VERSION ""

NS_ :

BS_:

BU_: VCU_LE CHUD_LE VKM_LE RCRM_LE VPM_LE EDI_LE V2V_LE TCP_LE CSM_LE UHP_Low_LE TouchPad_LE RSE_LE RSC_LE RSA_LE PDIM_LE OTIM_LE ICS_LE LVMPC_LE LVMNav_LE DVB_T_LE ONSTAR_LE HUD_LE IPC_LE RadioHead_LE CHM_LE Dummy_LE CGM_LE AMP_LE

BO_ 2154807296 Lighting_Customization_Info_3_LE: 4 CGM_LE
 SG_ TnDrvStBltShftIntrlkCsStAvl : 19|1@0+ (1,0) [0|1] ""  VCU_LE,CSM_LE
 SG_ TnDrvStBltShftIntrlkCrStVal : 22|3@0+ (1,0) [0|7] ""  VCU_LE,CSM_LE
 SG_ StBltShftIntrlkCsStAvl : 18|1@0+ (1,0) [0|1] ""  CSM_LE
 SG_ StBltShftIntrlkCsCrStVal : 15|3@0+ (1,0) [0|7] ""  CSM_LE
 SG_ EASSI_UnsdRsrvd2 : 24|1@0+ (1,0) [0|1] ""  Dummy_LE
 SG_ EASSI_StlDetd : 26|1@0+ (1,0) [0|1] ""  Dummy_LE
 SG_ EASSI_TrqDetd : 27|1@0+ (1,0) [0|1] ""  Dummy_LE
 SG_ EASSI_FuelReqOn : 28|1@0+ (1,0) [0|1] ""  Dummy_LE
 SG_ EASSI_StrtTyp : 31|3@0+ (1,0) [0|7] ""  Dummy_LE
 SG_ EASSI_StrtStpSt : 17|2@0+ (1,0) [0|3] ""  Dummy_LE
 SG_ EASSI_TorqDetdIndet : 25|1@0+ (1,0) [0|1] ""  Dummy_LE
 SG_ EngAutoStpNotProb : 11|1@0+ (1,0) [0|1] ""  Dummy_LE
 SG_ AFLMnu3CstStAvl : 10|1@0+ (1,0) [0|1] ""  VCU_LE,CSM_LE,RadioHead_LE
 SG_ AFLMnu2CstStAvl : 9|1@0+ (1,0) [0|1] ""  VCU_LE,CSM_LE,RadioHead_LE
 SG_ AFLGPSMnu2CstStAvl : 8|1@0+ (1,0) [0|1] ""  VCU_LE,CSM_LE,RadioHead_LE
 SG_ AFLGPSCstStAvl : 6|1@0+ (1,0) [0|1] ""  VCU_LE,CSM_LE,RadioHead_LE
 SG_ AFLGPSCstCrStVal : 2|3@0+ (1,0) [0|7] ""  VCU_LE,CSM_LE,RadioHead_LE
 SG_ AFLCstStAvl : 7|1@0+ (1,0) [0|1] ""  VCU_LE,CSM_LE,RadioHead_LE
 SG_ AFLCstCrStVal : 5|3@0+ (1,0) [0|7] ""  VCU_LE,CSM_LE,RadioHead_LE

BO_ 2155970560 HVAC_PowerManager_Status_LE: 1 CGM_LE
 SG_ ClmCntLdShdLvlRq : 3|4@0+ (1,0) [0|15] ""  Dummy_LE
 SG_ ClmCntBatSaverIO : 5|1@0+ (1,0) [0|1] ""  VCU_LE,IPC_LE

BO_ 2159067136 ODI_DAB_2_IPC_LE: 8 RadioHead_LE
 SG_ ODI_DAB2IPC : 7|64@0+ (1,0) [0|1.84467440737096E+019] ""  VCU_LE,IPC_LE

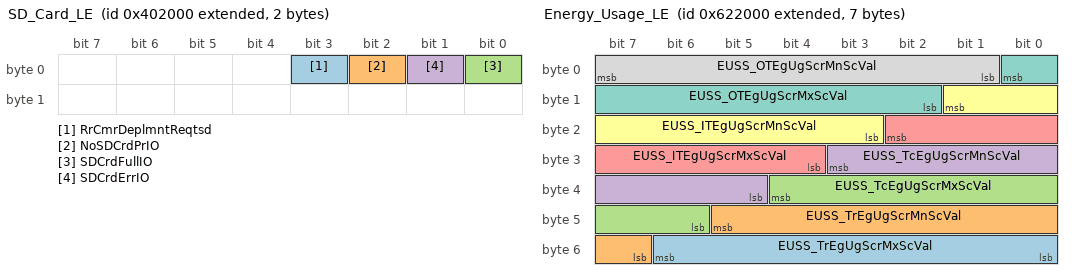
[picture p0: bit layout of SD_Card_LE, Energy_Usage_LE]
BO_ 2151686144 SD_Card_LE: 2 VPM_LE
 SG_ RrCmrDeplmntReqtsd : 3|1@0+ (1,0) [0|1] ""  RCRM_LE
 SG_ NoSDCrdPrIO : 2|1@0+ (1,0) [0|1] ""  CSM_LE,RadioHead_LE,VCU_LE,IPC_LE
 SG_ SDCrdFullIO : 0|1@0+ (1,0) [0|1] ""  CSM_LE,RadioHead_LE,VCU_LE,IPC_LE
 SG_ SDCrdErrIO : 1|1@0+ (1,0) [0|1] ""  CSM_LE,RadioHead_LE,VCU_LE,IPC_LE

BO_ 595 USDT_Req_to_TIM_CGM_LE: 8 ONSTAR_LE
 SG_ DgnInf : 7|64@0+ (1,0) [0|1.84467440737096E+019] ""  TCP_LE,ONSTAR_LE,CGM_LE

BO_ 2153914368 Energy_Usage_LE: 7 CGM_LE
 SG_ EUSS_TrEgUgScrMxScVal : 54|7@0- (0.1,0) [-5|5] ""  VCU_LE,CSM_LE,RadioHead_LE
 SG_ EUSS_TrEgUgScrMnScVal : 45|7@0- (0.1,0) [-5|5] ""  VCU_LE,CSM_LE,RadioHead_LE
 SG_ EUSS_TcEgUgScrMxScVal : 36|7@0- (0.1,0) [-5|5] ""  VCU_LE,CSM_LE,RadioHead_LE
 SG_ EUSS_TcEgUgScrMnScVal : 27|7@0- (0.1,0) [-5|5] ""  VCU_LE,CSM_LE,RadioHead_LE
 SG_ EUSS_ITEgUgScrMxScVal : 18|7@0- (0.1,0) [-5|5] ""  VCU_LE,CSM_LE,RadioHead_LE
 SG_ EUSS_ITEgUgScrMnScVal : 9|7@0- (0.1,0) [-5|5] ""  VCU_LE,CSM_LE,RadioHead_LE
 SG_ EUSS_OTEgUgScrMxScVal : 0|7@0- (0.1,0) [-5|5] ""  VCU_LE,CSM_LE,RadioHead_LE
 SG_ EUSS_OTEgUgScrMnScVal : 7|7@0- (0.1,0) [-5|5] ""  VCU_LE,CSM_LE,RadioHead_LE

BO_ 2150629376 CV_System_Failure_LE: 1 CGM_LE
 SG_ CVSysFlrIO : 0|1@0+ (1,0) [0|1] ""  CSM_LE,VCU_LE,IPC_LE

BO_ 2153390080 Manual_Liftgate_Control_LE: 1 CGM_LE
 SG_ RrClosOpenSwAct_2D1V : 3|1@0+ (1,0) [0|1] ""  VCU_LE,IPC_LE
 SG_ RrClosOpenSwAct_2D1 : 1|1@0+ (1,0) [0|1] ""  VKM_LE,VCU_LE,IPC_LE

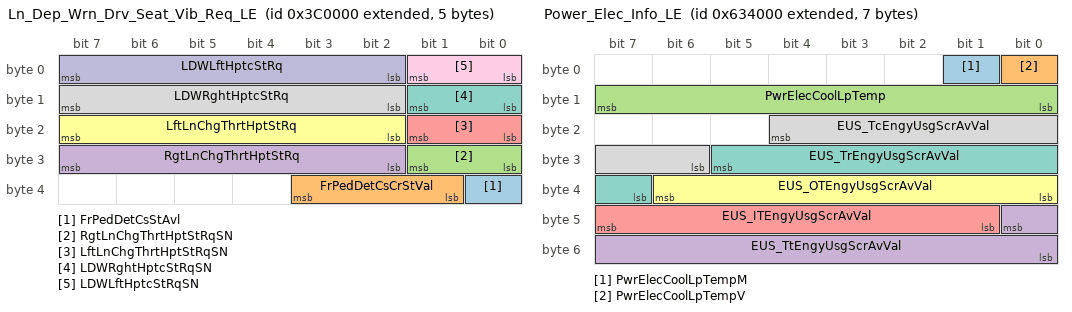
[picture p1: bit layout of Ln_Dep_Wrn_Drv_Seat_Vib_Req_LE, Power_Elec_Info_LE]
BO_ 2151415808 Ln_Dep_Wrn_Drv_Seat_Vib_Req_LE: 5 CGM_LE
 SG_ FrPedDetCsStAvl : 32|1@0+ (1,0) [0|1] ""  VCU_LE,CSM_LE,RadioHead_LE
 SG_ FrPedDetCsCrStVal : 35|3@0+ (1,0) [0|7] ""  VCU_LE,CSM_LE,RadioHead_LE
 SG_ RgtLnChgThrtHptStRqSN : 25|2@0+ (1,0) [0|3] ""  Dummy_LE
 SG_ RgtLnChgThrtHptStRq : 31|6@0+ (1,0) [0|63] "Pulse"  Dummy_LE
 SG_ LftLnChgThrtHptStRqSN : 17|2@0+ (1,0) [0|3] ""  Dummy_LE
 SG_ LftLnChgThrtHptStRq : 23|6@0+ (1,0) [0|63] "Pulse"  Dummy_LE
 SG_ LDWRghtHptcStRqSN : 9|2@0+ (1,0) [0|3] ""  Dummy_LE
 SG_ LDWRghtHptcStRq : 15|6@0+ (1,0) [0|63] ""  Dummy_LE
 SG_ LDWLftHptcStRqSN : 1|2@0+ (1,0) [0|3] ""  Dummy_LE
 SG_ LDWLftHptcStRq : 7|6@0+ (1,0) [0|63] ""  Dummy_LE

BO_ 2150080512 Aux_Coolant_Heater_Status_LE: 8 CGM_LE
 SG_ LBCVLS_VehGPSLctV : 27|1@0+ (1,0) [0|1] ""  TCP_LE,ONSTAR_LE,VCU_LE,CSM_LE,RadioHead_LE
 SG_ LBCVLS_VehGPSLct : 26|3@0+ (1,0) [0|7] ""  TCP_LE,ONSTAR_LE,VCU_LE,CSM_LE,RadioHead_LE
 SG_ EngAstHtDfrdHtMdAct : 0|1@0+ (1,0) [0|1] ""  Dummy_LE
 SG_ LBCPSS_PosUpdtStat : 20|2@0+ (1,0) [0|3] ""  VCU_LE,CSM_LE,RadioHead_LE
 SG_ LBCPSS_PosUpdtLct : 18|3@0+ (1,0) [0|7] ""  VCU_LE,CSM_LE,RadioHead_LE
 SG_ LBCCsStAvl : 7|1@0+ (1,0) [0|1] ""  VCU_LE,CSM_LE,RadioHead_LE
 SG_ LBCCsCrStVal : 2|2@0+ (1,0) [0|3] ""  VCU_LE,CSM_LE,RadioHead_LE
 SG_ LBCCF_Lct4PosStrdIO : 28|1@0+ (1,0) [0|1] ""  VCU_LE,CSM_LE,RadioHead_LE
 SG_ LBCCF_Lct3PosStrdIO : 29|1@0+ (1,0) [0|1] ""  VCU_LE,CSM_LE,RadioHead_LE
 SG_ LBCCF_Lct2PosStrdIO : 30|1@0+ (1,0) [0|1] ""  VCU_LE,CSM_LE,RadioHead_LE
 SG_ LBCCF_Lct1PosStrdIO : 31|1@0+ (1,0) [0|1] ""  VCU_LE,CSM_LE,RadioHead_LE
 SG_ LBCCDRR_PosNumbr : 10|3@0+ (1,0) [0|7] ""  VCU_LE,CSM_LE,RadioHead_LE
 SG_ LBCCDRR_ClrStrdPosResp : 12|2@0+ (1,0) [0|3] ""  VCU_LE,CSM_LE,RadioHead_LE
 SG_ LBCChrgLvlPrfExpIO : 6|1@0+ (1,0) [0|1] ""  VCU_LE,CSM_LE,RadioHead_LE
 SG_ AuxClntHtrVlvStat : 5|3@0+ (1,0) [0|7] ""  Dummy_LE
 SG_ ChrgCyclOvrlEngyEcnEq : 51|12@0+ (0.1,0) [0|409.5] "km/l"  VCU_LE,CSM_LE,RadioHead_LE
 SG_ ChrgCyclElecEngyEcnEq : 35|12@0+ (0.1,0) [0|409.5] "km/l"  VCU_LE,CSM_LE,RadioHead_LE

BO_ 2153988096 Power_Elec_Info_LE: 7 CGM_LE
 SG_ PwrElecCoolLpTempM : 1|1@0+ (1,0) [0|1] ""  Dummy_LE
 SG_ PwrElecCoolLpTempV : 0|1@0+ (1,0) [0|1] ""  Dummy_LE
 SG_ PwrElecCoolLpTemp : 15|8@0+ (1,-40) [-40|215] "deg C"  Dummy_LE
 SG_ EUS_TtEngyUsgScrAvVal : 40|9@0- (0.1,0) [-20|20] ""  VCU_LE,CSM_LE,RadioHead_LE
 SG_ EUS_ITEngyUsgScrAvVal : 47|7@0- (0.1,0) [-5|5] ""  VCU_LE,CSM_LE,RadioHead_LE
 SG_ EUS_OTEngyUsgScrAvVal : 38|7@0- (0.1,0) [-5|5] ""  VCU_LE,CSM_LE,RadioHead_LE
 SG_ EUS_TrEngyUsgScrAvVal : 29|7@0- (0.1,0) [-5|5] ""  VCU_LE,CSM_LE,RadioHead_LE
 SG_ EUS_TcEngyUsgScrAvVal : 20|7@0- (0.1,0) [-5|5] ""  VCU_LE,CSM_LE,RadioHead_LE

BO_ 2151915520 HMI_Display_LE: 8 CGM_LE
 SG_ ESPTrnVehOffFrPrkIO : 44|1@0+ (1,0) [0|1] ""  VCU_LE,IPC_LE
 SG_ ESPTrnsCtlrMalfIO : 45|1@0+ (1,0) [0|1] ""  VCU_LE,IPC_LE
 SG_ ESPShfToDrvTryAgnIO : 43|1@0+ (1,0) [0|1] ""  VCU_LE,IPC_LE
 SG_ ElcShfPriTwoGrsSlInRq : 47|2@0+ (1,0) [0|3] ""  VCU_LE,IPC_LE
 SG_ ESPRedSpdReqShftIO : 42|1@0+ (1,0) [0|1] ""  VCU_LE,IPC_LE
 SG_ DrvEffInd : 39|8@0- (0.78125,0) [-100|99.21875] "%"  CSM_LE,VCU_LE,IPC_LE
 SG_ EngIntkArBstPrExtRngV : 14|1@0+ (1,0) [0|1] ""  VCU_LE,IPC_LE
 SG_ EngIntkArBstPrExtRng : 8|9@0+ (1,-110) [-110|401] "kPa"  VCU_LE,IPC_LE
 SG_ ElecShfRngDispRCExtd : 27|4@0+ (1,0) [0|15] ""  VCU_LE,IPC_LE
 SG_ ElecShfRngDisp : 31|4@0+ (1,0) [0|15] ""  VCU_LE,IPC_LE
 SG_ ESPTransMalfIO : 9|1@0+ (1,0) [0|1] ""  VCU_LE,IPC_LE
 SG_ ESPRngInvldReqIO : 10|1@0+ (1,0) [0|1] ""  VCU_LE,IPC_LE
 SG_ ESPPrkInvldReqIO : 11|1@0+ (1,0) [0|1] ""  VCU_LE,IPC_LE
 SG_ ESPHldShfLvrToEngRgIO : 12|1@0+ (1,0) [0|1] ""  VCU_LE,IPC_LE
 SG_ ESPDrvrPrkIlkSftAtdIO : 13|1@0+ (1,0) [0|1] ""  VCU_LE,IPC_LE
 SG_ ESPDrvrIlkShfAtdIO : 7|1@0+ (1,0) [0|1] ""  VCU_LE,IPC_LE
 SG_ AHAct : 6|1@0+ (1,0) [0|1] ""  VCU_LE,IPC_LE
 SG_ AHEnbld : 5|1@0+ (1,0) [0|1] ""  CSM_LE,VCU_LE,IPC_LE
 SG_ ShfToPrkBfExtngIO : 4|1@0+ (1,0) [0|1] ""  VCU_LE,IPC_LE
 SG_ AHServcIO : 3|1@0+ (1,0) [0|1] ""  VCU_LE,IPC_LE
 SG_ AHAppBrkPedlIO : 2|1@0+ (1,0) [0|1] ""  VCU_LE,IPC_LE
 SG_ AHDisbldStbltIO : 1|1@0+ (1,0) [0|1] ""  VCU_LE,IPC_LE
 SG_ AHDisbldDrOpnIO : 0|1@0+ (1,0) [0|1] ""  VCU_LE,IPC_LE
 SG_ ElcTransRngSlctVDA : 15|1@0+ (1,0) [0|1] ""  VCU_LE,IPC_LE

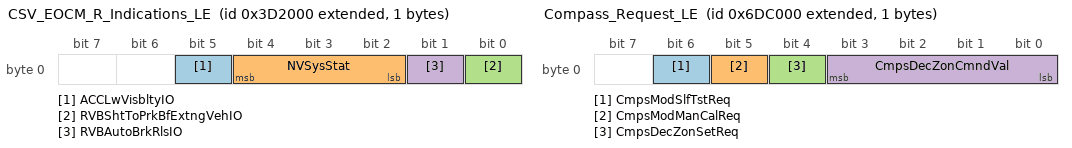
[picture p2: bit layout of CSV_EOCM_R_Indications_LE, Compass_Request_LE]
BO_ 2151489536 CSV_EOCM_R_Indications_LE: 1 CGM_LE
 SG_ ACCLwVisbltyIO : 5|1@0+ (1,0) [0|1] ""  VCU_LE,IPC_LE
 SG_ NVSysStat : 4|3@0+ (1,0) [0|7] ""  VCU_LE,IPC_LE
 SG_ RVBShtToPrkBfExtngVehIO : 0|1@0+ (1,0) [0|1] ""  VCU_LE,IPC_LE
 SG_ RVBAutoBrkRlsIO : 1|1@0+ (1,0) [0|1] ""  VCU_LE,IPC_LE

BO_ 590 USDT_Req_to_RSC_LE: 8 ONSTAR_LE
 SG_ DgnInf : 7|64@0+ (1,0) [0|1.84467440737096E+019] ""  TCP_LE,ONSTAR_LE,CGM_LE,VKM_LE,RSC_LE

BO_ 586 USDT_Req_to_LVMPC_LE: 8 ONSTAR_LE
 SG_ DgnInf : 7|64@0+ (1,0) [0|1.84467440737096E+019] ""  TCP_LE,ONSTAR_LE,CGM_LE,CHUD_LE,LVMPC_LE

BO_ 596 USDT_Req_to_AMP_LE: 8 ONSTAR_LE
 SG_ DgnInf : 7|64@0+ (1,0) [0|1.84467440737096E+019] ""  TCP_LE,ONSTAR_LE,AMP_LE

BO_ 582 USDT_Req_to_ICS_LE: 8 ONSTAR_LE
 SG_ DgnInf : 7|64@0+ (1,0) [0|1.84467440737096E+019] ""  TCP_LE,ONSTAR_LE,ICS_LE

BO_ 257 USDT_Req_to_All_LE_ECUs: 8 ONSTAR_LE
 SG_ DgnInf : 7|64@0+ (1,0) [0|1.84467440737096E+019] ""  RCRM_LE,V2V_LE,CGM_LE,VKM_LE,RSC_LE,RSE_LE,RSA_LE,PDIM_LE,TCP_LE,UHP_Low_LE,LVMNav_LE,ONSTAR_LE,CHUD_LE,LVMPC_LE,IPC_LE,VPM_LE,HUD_LE,AMP_LE,VCU_LE,CSM_LE,RadioHead_LE,CHM_LE,OTIM_LE,ICS_LE,TouchPad_LE,DVB_T_LE

BO_ 594 USDT_Req_to_DVBT_LE: 8 ONSTAR_LE
 SG_ DgnInf : 7|64@0+ (1,0) [0|1.84467440737096E+019] ""  TCP_LE,ONSTAR_LE,TouchPad_LE,DVB_T_LE

BO_ 592 USDT_Req_to_HUD_LE: 8 ONSTAR_LE
 SG_ DgnInf : 7|64@0+ (1,0) [0|1.84467440737096E+019] ""  TCP_LE,ONSTAR_LE,VPM_LE,HUD_LE

BO_ 588 USDT_Req_to_IPC_LE: 8 ONSTAR_LE
 SG_ DgnInf : 7|64@0+ (1,0) [0|1.84467440737096E+019] ""  TCP_LE,ONSTAR_LE,IPC_LE

BO_ 585 USDT_Req_to_OTIM_LE: 8 ONSTAR_LE
 SG_ DgnInf : 7|64@0+ (1,0) [0|1.84467440737096E+019] ""  TCP_LE,ONSTAR_LE,CGM_LE,OTIM_LE

BO_ 584 USDT_Req_to_PDIM_LE: 8 ONSTAR_LE
 SG_ DgnInf : 7|64@0+ (1,0) [0|1.84467440737096E+019] ""  TCP_LE,ONSTAR_LE,CGM_LE,PDIM_LE

BO_ 580 USDT_Req_to_RadioHead_LE: 8 ONSTAR_LE
 SG_ DgnInf : 7|64@0+ (1,0) [0|1.84467440737096E+019] ""  TCP_LE,ONSTAR_LE,VCU_LE,CSM_LE,RadioHead_LE,CHM_LE

BO_ 598 USDT_Req_to_RSA_RSE_LE: 8 ONSTAR_LE
 SG_ DgnInf : 7|64@0+ (1,0) [0|1.84467440737096E+019] ""  TCP_LE,ONSTAR_LE,CGM_LE,RSE_LE,RSA_LE

BO_ 589 USDT_Req_to_UHP_ONS_LE: 8 CSM_LE
 SG_ DgnInf : 7|64@0+ (1,0) [0|1.84467440737096E+019] ""  TCP_LE,UHP_Low_LE,LVMNav_LE,ONSTAR_LE

BO_ 1612 USDT_Resp_From_IPC_LE: 8 IPC_LE
 SG_ DgnInf : 7|64@0+ (1,0) [0|1.84467440737096E+019] ""  CSM_LE,CGM_LE,TCP_LE,ONSTAR_LE

BO_ 1580 VNMF_LE_62C_IPC: 8 IPC_LE
 SG_ VectraSpcNWMgtD : 7|64@0+ (1,0) [0|1.84467440737096E+019] ""  RCRM_LE,V2V_LE,TCP_LE,UHP_Low_LE,LVMNav_LE,ONSTAR_LE,VKM_LE,RSC_LE,RSE_LE,RSA_LE,PDIM_LE,OTIM_LE,CHUD_LE,LVMPC_LE,ICS_LE,VPM_LE,HUD_LE,TouchPad_LE,DVB_T_LE,VCU_LE,CSM_LE,RadioHead_LE,CHM_LE,AMP_LE,CGM_LE

BO_ 1356 UUDT_Resp_From_IPC_LE: 8 IPC_LE
 SG_ DgnInf_LS54C : 7|64@0+ (1,0) [0|1.84467440737096E+019] ""  CSM_LE,CGM_LE,TCP_LE,ONSTAR_LE

BO_ 2154676224 Compass_Request_LE: 1 IPC_LE
 SG_ CmpsModSlfTstReq : 6|1@0+ (1,0) [0|1] ""  CGM_LE
 SG_ CmpsModManCalReq : 5|1@0+ (1,0) [0|1] ""  CGM_LE
 SG_ CmpsDecZonSetReq : 4|1@0+ (1,0) [0|1] ""  CGM_LE
 SG_ CmpsDecZonCmndVal : 3|4@0+ (1,0) [0|15] ""  CGM_LE

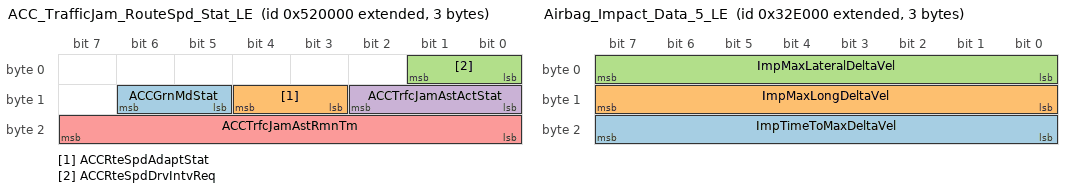
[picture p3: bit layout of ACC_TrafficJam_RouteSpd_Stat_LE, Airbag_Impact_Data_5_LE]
BO_ 2152857600 ACC_TrafficJam_RouteSpd_Stat_LE: 3 CGM_LE
 SG_ ACCGrnMdStat : 14|2@0+ (1,0) [0|3] ""  CSM_LE,ONSTAR_LE,VCU_LE,IPC_LE
 SG_ ACCRteSpdAdaptStat : 12|2@0+ (1,0) [0|3] ""  CSM_LE,VCU_LE,IPC_LE
 SG_ ACCRteSpdDrvIntvReq : 1|2@0+ (1,0) [0|3] ""  VCU_LE,IPC_LE
 SG_ ACCTrfcJamAstActStat : 10|3@0+ (1,0) [0|7] ""  VCU_LE,IPC_LE
 SG_ ACCTrfcJamAstRmnTm : 23|8@0+ (1,0) [0|255] "sec"  VCU_LE,IPC_LE

BO_ 2154995712 Air_Conditioning_Comp_Type_LE: 1 CGM_LE
 SG_ HVHtrFldIO : 4|1@0+ (1,0) [0|1] ""  VCU_LE,IPC_LE
 SG_ HVHtrOvrTmpIndOn : 3|1@0+ (1,0) [0|1] ""  CSM_LE,ONSTAR_LE,VCU_LE,IPC_LE

BO_ 2150817792 Airbag_Impact_Data_5_LE: 3 CGM_LE
 SG_ ImpTimeToMaxDeltaVel : 23|8@0+ (10,0) [0|2550] "ms"  TCP_LE,ONSTAR_LE
 SG_ ImpMaxLongDeltaVel : 15|8@0- (1,0) [-128|127] ""  TCP_LE,ONSTAR_LE
 SG_ ImpMaxLateralDeltaVel : 7|8@0- (1,0) [-128|127] ""  TCP_LE,ONSTAR_LE

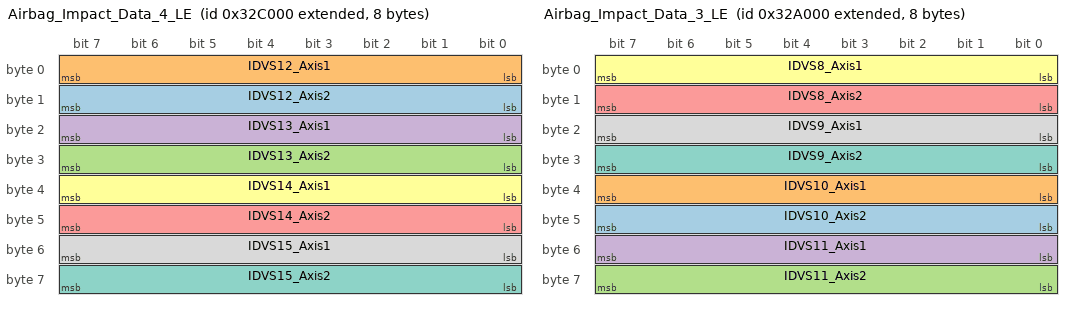
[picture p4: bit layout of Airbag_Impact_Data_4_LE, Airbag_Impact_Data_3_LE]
BO_ 2150809600 Airbag_Impact_Data_4_LE: 8 CGM_LE
 SG_ IDVS12_Axis2 : 15|8@0- (1,0) [-128|127] "counts"  TCP_LE,ONSTAR_LE
 SG_ IDVS12_Axis1 : 7|8@0- (1,0) [-128|127] "counts"  TCP_LE,ONSTAR_LE
 SG_ IDVS13_Axis2 : 31|8@0- (1,0) [-128|127] "counts"  TCP_LE,ONSTAR_LE
 SG_ IDVS13_Axis1 : 23|8@0- (1,0) [-128|127] "counts"  TCP_LE,ONSTAR_LE
 SG_ IDVS14_Axis2 : 47|8@0- (1,0) [-128|127] "counts"  TCP_LE,ONSTAR_LE
 SG_ IDVS14_Axis1 : 39|8@0- (1,0) [-128|127] "counts"  TCP_LE,ONSTAR_LE
 SG_ IDVS15_Axis2 : 63|8@0- (1,0) [-128|127] "counts"  TCP_LE,ONSTAR_LE
 SG_ IDVS15_Axis1 : 55|8@0- (1,0) [-128|127] "counts"  TCP_LE,ONSTAR_LE

BO_ 2150801408 Airbag_Impact_Data_3_LE: 8 CGM_LE
 SG_ IDVS10_Axis2 : 47|8@0- (1,0) [-128|127] "counts"  TCP_LE,ONSTAR_LE
 SG_ IDVS10_Axis1 : 39|8@0- (1,0) [-128|127] "counts"  TCP_LE,ONSTAR_LE
 SG_ IDVS11_Axis2 : 63|8@0- (1,0) [-128|127] "counts"  TCP_LE,ONSTAR_LE
 SG_ IDVS11_Axis1 : 55|8@0- (1,0) [-128|127] "counts"  TCP_LE,ONSTAR_LE
 SG_ IDVS8_Axis2 : 15|8@0- (1,0) [-128|127] "counts"  TCP_LE,ONSTAR_LE
 SG_ IDVS8_Axis1 : 7|8@0- (1,0) [-128|127] "counts"  TCP_LE,ONSTAR_LE
 SG_ IDVS9_Axis2 : 31|8@0- (1,0) [-128|127] "counts"  TCP_LE,ONSTAR_LE
 SG_ IDVS9_Axis1 : 23|8@0- (1,0) [-128|127] "counts"  TCP_LE,ONSTAR_LE

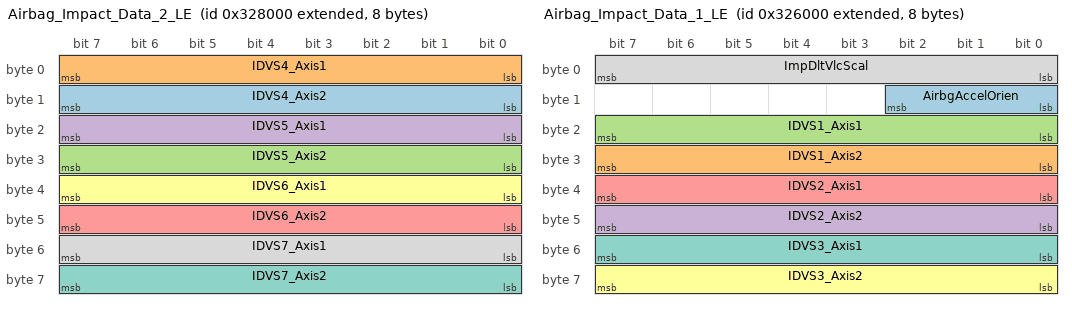
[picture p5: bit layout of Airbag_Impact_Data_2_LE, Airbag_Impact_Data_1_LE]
BO_ 2150793216 Airbag_Impact_Data_2_LE: 8 CGM_LE
 SG_ IDVS4_Axis2 : 15|8@0- (1,0) [-128|127] "counts"  TCP_LE,ONSTAR_LE
 SG_ IDVS4_Axis1 : 7|8@0- (1,0) [-128|127] "counts"  TCP_LE,ONSTAR_LE
 SG_ IDVS5_Axis2 : 31|8@0- (1,0) [-128|127] "counts"  TCP_LE,ONSTAR_LE
 SG_ IDVS5_Axis1 : 23|8@0- (1,0) [-128|127] "counts"  TCP_LE,ONSTAR_LE
 SG_ IDVS6_Axis2 : 47|8@0- (1,0) [-128|127] "counts"  TCP_LE,ONSTAR_LE
 SG_ IDVS6_Axis1 : 39|8@0- (1,0) [-128|127] "counts"  TCP_LE,ONSTAR_LE
 SG_ IDVS7_Axis2 : 63|8@0- (1,0) [-128|127] "counts"  TCP_LE,ONSTAR_LE
 SG_ IDVS7_Axis1 : 55|8@0- (1,0) [-128|127] "counts"  TCP_LE,ONSTAR_LE

BO_ 2150785024 Airbag_Impact_Data_1_LE: 8 CGM_LE
 SG_ AirbgAccelOrien : 10|3@0+ (45,0) [0|315] "deg"  TCP_LE,ONSTAR_LE
 SG_ IDVS1_Axis2 : 31|8@0- (1,0) [-128|127] "counts"  TCP_LE,ONSTAR_LE
 SG_ IDVS1_Axis1 : 23|8@0- (1,0) [-128|127] "counts"  TCP_LE,ONSTAR_LE
 SG_ IDVS2_Axis2 : 47|8@0- (1,0) [-128|127] "counts"  TCP_LE,ONSTAR_LE
 SG_ IDVS2_Axis1 : 39|8@0- (1,0) [-128|127] "counts"  TCP_LE,ONSTAR_LE
 SG_ IDVS3_Axis2 : 63|8@0- (1,0) [-128|127] "counts"  TCP_LE,ONSTAR_LE
 SG_ IDVS3_Axis1 : 55|8@0- (1,0) [-128|127] "counts"  TCP_LE,ONSTAR_LE
 SG_ ImpDltVlcScal : 7|8@0+ (0.00245,0.706) [0.706|1.33075] "kph/cnt"  TCP_LE,ONSTAR_LE

BO_ 2150825984 Airbag_Indications_LE: 6 CGM_LE
 SG_ PdstIntdProtSysDplyd : 46|1@0+ (1,0) [0|1] ""  VCU_LE,IPC_LE
 SG_ PdstIntdProtSysDsbld : 45|1@0+ (1,0) [0|1] ""  VCU_LE,IPC_LE
 SG_ SrvIntdPdstProtSysIO : 44|1@0+ (1,0) [0|1] ""  VCU_LE,IPC_LE
 SG_ FstnThrdRwRtPsStbtInR : 41|2@0+ (1,0) [0|3] ""  CSM_LE,ONSTAR_LE,VCU_LE,IPC_LE
 SG_ FstnThrdRwLtPsStbtInR : 43|2@0+ (1,0) [0|3] ""  CSM_LE,ONSTAR_LE,VCU_LE,IPC_LE
 SG_ FstnThrdRwCtPsStbtInR : 39|2@0+ (1,0) [0|3] ""  V2V_LE,CSM_LE,ONSTAR_LE,VCU_LE,IPC_LE
 SG_ FPSIC_IndPer : 11|4@0+ (1,0) [0|15] ""  CSM_LE,TCP_LE,V2V_LE,ONSTAR_LE,VCU_LE,IPC_LE
 SG_ FPSIC_IO : 15|1@0+ (1,0) [0|1] ""  CSM_LE,TCP_LE,V2V_LE,ONSTAR_LE,VCU_LE,IPC_LE
 SG_ FPSIC_IndDtCyc : 14|3@0+ (12.5,12.5) [12.5|100] "%"  CSM_LE,TCP_LE,V2V_LE,ONSTAR_LE,VCU_LE,IPC_LE
 SG_ FDSIC_IndPer : 3|4@0+ (1,0) [0|15] ""  CSM_LE,TCP_LE,V2V_LE,ONSTAR_LE,VCU_LE,IPC_LE
 SG_ FDSIC_IO : 7|1@0+ (1,0) [0|1] ""  CSM_LE,TCP_LE,V2V_LE,ONSTAR_LE,VCU_LE,IPC_LE
 SG_ FDSIC_IndDC : 6|3@0+ (12.5,12.5) [12.5|100] "%"  CSM_LE,TCP_LE,V2V_LE,ONSTAR_LE,VCU_LE,IPC_LE
 SG_ AirbgFldIO : 35|1@0+ (1,0) [0|1] ""  TCP_LE,V2V_LE,ONSTAR_LE,VCU_LE,IPC_LE
 SG_ SndRwStbltRdIndMd : 37|2@0+ (1,0) [0|3] ""  V2V_LE,CSM_LE,ONSTAR_LE,VCU_LE,IPC_LE
 SG_ AirbgICIndPer : 19|4@0+ (1,0) [0|15] ""  CSM_LE,TCP_LE,ONSTAR_LE,VCU_LE,IPC_LE
 SG_ AirbgICDutCyc : 22|3@0+ (12.5,12.5) [12.5|100] "%"  CSM_LE,TCP_LE,ONSTAR_LE,VCU_LE,IPC_LE
 SG_ AirbgICIO : 23|1@0+ (1,0) [0|1] ""  CSM_LE,TCP_LE,ONSTAR_LE,VCU_LE,IPC_LE
 SG_ FstnSndRwRtPsStbtInR : 29|2@0+ (1,0) [0|3] ""  CSM_LE,ONSTAR_LE,V2V_LE,VCU_LE,IPC_LE
 SG_ FstnSndRwLtPsStbtInR : 25|2@0+ (1,0) [0|3] ""  CSM_LE,ONSTAR_LE,V2V_LE,VCU_LE,IPC_LE
 SG_ FstnSndRwCtPsStbtInR : 27|2@0+ (1,0) [0|3] ""  CSM_LE,ONSTAR_LE,VCU_LE,IPC_LE
 SG_ FsnDrStbAuxIR : 31|2@0+ (1,0) [0|3] ""  VCU_LE,IPC_LE
 SG_ FsnPsStbAuxIR : 34|3@0+ (1,0) [0|7] ""  VCU_LE,IPC_LE

BO_ 2151268352 Column_Lock_Status_LE: 1 CGM_LE
 SG_ ClmnLckTT : 1|2@0+ (1,0) [0|3] ""  CSM_LE,VCU_LE,IPC_LE

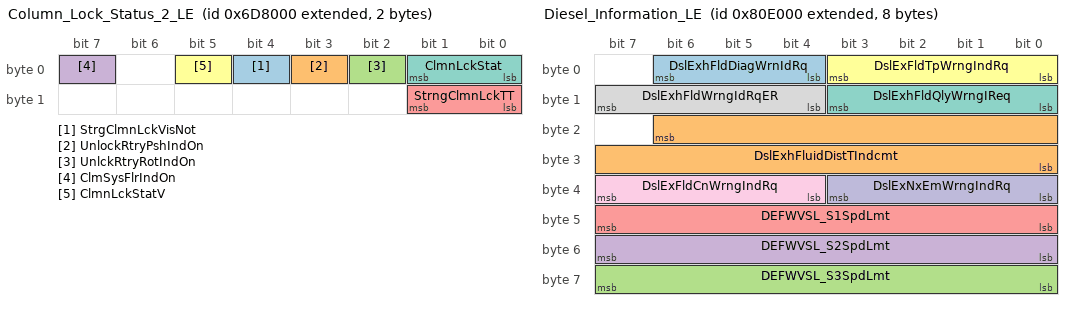
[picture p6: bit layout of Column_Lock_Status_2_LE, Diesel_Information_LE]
BO_ 2154659840 Column_Lock_Status_2_LE: 2 CGM_LE
 SG_ StrgClmnLckVisNot : 4|1@0+ (1,0) [0|1] ""  VCU_LE,IPC_LE
 SG_ UnlockRtryPshIndOn : 3|1@0+ (1,0) [0|1] ""  VCU_LE,IPC_LE
 SG_ UnlckRtryRotIndOn : 2|1@0+ (1,0) [0|1] ""  VCU_LE,IPC_LE
 SG_ ClmSysFlrIndOn : 7|1@0+ (1,0) [0|1] ""  VCU_LE,IPC_LE
 SG_ StrngClmnLckTT : 9|2@0+ (1,0) [0|3] ""  VCU_LE,IPC_LE
 SG_ ClmnLckStatV : 5|1@0+ (1,0) [0|1] ""  Dummy_LE
 SG_ ClmnLckStat : 1|2@0+ (1,0) [0|3] ""  Dummy_LE

BO_ 2149974016 Content_Theft_Sensor_Status_LE: 3 CGM_LE
 SG_ IntrSnsDisbld : 1|1@0+ (1,0) [0|1] ""  VCU_LE,IPC_LE
 SG_ AlrmStat : 18|3@0+ (1,0) [0|7] ""  VPM_LE,TCP_LE,ONSTAR_LE
 SG_ AlrmTrggrdBattRcnctd : 11|1@0+ (1,0) [0|1] ""  TCP_LE,ONSTAR_LE
 SG_ AlrmTrgDrvDr : 3|1@0+ (1,0) [0|1] ""  TCP_LE,ONSTAR_LE
 SG_ AlrmTrgGlsBrkSns : 12|1@0+ (1,0) [0|1] ""  TCP_LE,ONSTAR_LE
 SG_ AlrmTrgHd : 21|1@0+ (1,0) [0|1] ""  TCP_LE,ONSTAR_LE
 SG_ AlrmTrgdIO : 15|1@0+ (1,0) [0|1] ""  VCU_LE,IPC_LE
 SG_ AlrmTrgIntMvmntSns : 10|1@0+ (1,0) [0|1] ""  TCP_LE,ONSTAR_LE
 SG_ AlrmTrgNonOffPM : 13|1@0+ (1,0) [0|1] ""  Dummy_LE
 SG_ AlrmTrgPsngDr : 4|1@0+ (1,0) [0|1] ""  TCP_LE,ONSTAR_LE
 SG_ AlrmTrgRrLftDr : 6|1@0+ (1,0) [0|1] ""  TCP_LE,ONSTAR_LE
 SG_ AlrmTrgRrRtDr : 5|1@0+ (1,0) [0|1] ""  TCP_LE,ONSTAR_LE
 SG_ AlrmTrgTltSns : 9|1@0+ (1,0) [0|1] ""  TCP_LE,ONSTAR_LE
 SG_ AlrmTrgTrnk : 8|1@0+ (1,0) [0|1] ""  TCP_LE,ONSTAR_LE
 SG_ SrvAlrmSysIO : 0|1@0+ (1,0) [0|1] ""  TCP_LE,ONSTAR_LE,VCU_LE,IPC_LE
 SG_ AlrmTrigMidClsr : 14|1@0+ (1,0) [0|1] ""  TCP_LE,ONSTAR_LE
 SG_ AlrmTrigTonn : 7|1@0+ (1,0) [0|1] ""  Dummy_LE

BO_ 2155929600 Diesel_Information_LE: 8 CGM_LE
 SG_ DslExhFldDiagWrnIdRq : 6|3@0+ (1,0) [0|7] ""  CSM_LE,VCU_LE,IPC_LE
 SG_ DslExhFluidDistTIndcmt : 22|15@0+ (2,0) [0|65534] "km"  VCU_LE,IPC_LE
 SG_ DEFWVSL_S3SpdLmt : 63|8@0+ (1,0) [0|255] "km / h"  VCU_LE,IPC_LE
 SG_ DEFWVSL_S2SpdLmt : 55|8@0+ (1,0) [0|255] "km / h"  VCU_LE,IPC_LE
 SG_ DEFWVSL_S1SpdLmt : 47|8@0+ (1,0) [0|255] "km / h"  VCU_LE,IPC_LE
 SG_ DslExFldTpWrngIndRq : 3|4@0+ (1,0) [0|15] ""  VCU_LE,IPC_LE
 SG_ DslExhFldQlyWrngIReq : 11|4@0+ (1,0) [0|15] ""  VCU_LE,IPC_LE
 SG_ DslExhFldWrngIdRqER : 15|4@0+ (1,0) [0|15] ""  VCU_LE,IPC_LE
 SG_ DslExFldCnWrngIndRq : 39|4@0+ (1,0) [0|15] ""  VCU_LE,IPC_LE
 SG_ DslExNxEmWrngIndRq : 35|4@0+ (1,0) [0|15] ""  VCU_LE,IPC_LE

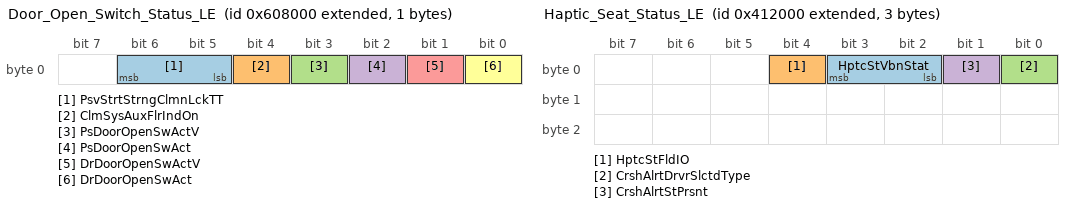
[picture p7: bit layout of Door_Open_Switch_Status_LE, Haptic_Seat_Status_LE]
BO_ 2153807872 Door_Open_Switch_Status_LE: 1 CGM_LE
 SG_ PsvStrtStrngClmnLckTT : 6|2@0+ (1,0) [0|3] ""  VCU_LE,IPC_LE
 SG_ ClmSysAuxFlrIndOn : 4|1@0+ (1,0) [0|1] ""  VCU_LE,IPC_LE
 SG_ PsDoorOpenSwActV : 3|1@0+ (1,0) [0|1] ""  V2V_LE,Dummy_LE
 SG_ PsDoorOpenSwAct : 2|1@0+ (1,0) [0|1] ""  V2V_LE,Dummy_LE
 SG_ DrDoorOpenSwActV : 1|1@0+ (1,0) [0|1] ""  V2V_LE,Dummy_LE
 SG_ DrDoorOpenSwAct : 0|1@0+ (1,0) [0|1] ""  V2V_LE,Dummy_LE

BO_ 2154938368 Fob_Programming_Mode_Status_LE: 1 CGM_LE
 SG_ FobProgMdStat : 1|2@0+ (1,0) [0|3] ""  VCU_LE,IPC_LE

BO_ 2151751680 Haptic_Seat_Status_LE: 3 CGM_LE
 SG_ HptcStVbnStat : 3|2@0+ (1,0) [0|3] ""  V2V_LE,VPM_LE,Dummy_LE
 SG_ HptcStFldIO : 4|1@0+ (1,0) [0|1] ""  VPM_LE,V2V_LE,VCU_LE,IPC_LE
 SG_ CrshAlrtDrvrSlctdType : 0|1@0+ (1,0) [0|1] ""  V2V_LE,VPM_LE,Dummy_LE
 SG_ CrshAlrtStPrsnt : 1|1@0+ (1,0) [0|1] ""  VPM_LE,V2V_LE

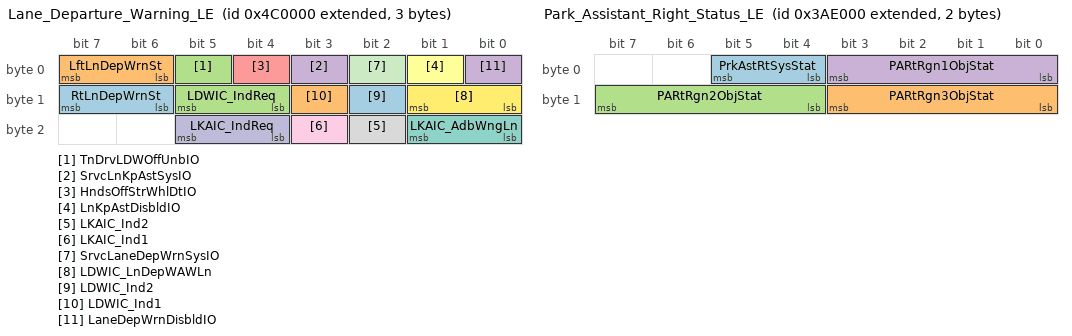
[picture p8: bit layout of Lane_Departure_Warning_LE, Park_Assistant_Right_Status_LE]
BO_ 2152464384 Lane_Departure_Warning_LE: 3 CGM_LE
 SG_ RtLnDepWrnSt : 15|2@0+ (1,0) [0|3] ""  CSM_LE,RadioHead_LE,VCU_LE,IPC_LE
 SG_ LftLnDepWrnSt : 7|2@0+ (1,0) [0|3] ""  CSM_LE,RadioHead_LE,VCU_LE,IPC_LE
 SG_ TnDrvLDWOffUnbIO : 5|1@0+ (1,0) [0|1] ""  VCU_LE,IPC_LE
 SG_ SrvcLnKpAstSysIO : 3|1@0+ (1,0) [0|1] ""  VCU_LE,IPC_LE
 SG_ HndsOffStrWhlDtIO : 4|1@0+ (1,0) [0|1] ""  VCU_LE,IPC_LE
 SG_ LnKpAstDisbldIO : 1|1@0+ (1,0) [0|1] ""  VCU_LE,IPC_LE
 SG_ LKAIC_AdbWngLn : 17|2@0+ (1,0) [0|3] ""  CSM_LE,RadioHead_LE,VCU_LE,IPC_LE
 SG_ LKAIC_Ind2 : 18|1@0+ (1,0) [0|1] ""  CSM_LE,RadioHead_LE,VCU_LE,IPC_LE
 SG_ LKAIC_Ind1 : 19|1@0+ (1,0) [0|1] ""  CSM_LE,RadioHead_LE,VCU_LE,IPC_LE
 SG_ LKAIC_IndReq : 21|2@0+ (1,0) [0|3] ""  CSM_LE,RadioHead_LE,VCU_LE,IPC_LE
 SG_ SrvcLaneDepWrnSysIO : 2|1@0+ (1,0) [0|1] ""  VCU_LE,IPC_LE
 SG_ LDWIC_LnDepWAWLn : 9|2@0+ (1,0) [0|3] ""  CSM_LE,RadioHead_LE,VCU_LE,IPC_LE
 SG_ LDWIC_Ind2 : 10|1@0+ (1,0) [0|1] ""  CSM_LE,RadioHead_LE,VCU_LE,IPC_LE
 SG_ LDWIC_Ind1 : 11|1@0+ (1,0) [0|1] ""  CSM_LE,RadioHead_LE,VCU_LE,IPC_LE
 SG_ LDWIC_IndReq : 13|2@0+ (1,0) [0|3] ""  CSM_LE,RadioHead_LE,VCU_LE,IPC_LE
 SG_ LaneDepWrnDisbldIO : 0|1@0+ (1,0) [0|1] ""  VCU_LE,IPC_LE

BO_ 2151342080 Park_Assistant_Right_Status_LE: 2 CGM_LE
 SG_ PrkAstRtSysStat : 5|2@0+ (1,0) [0|3] ""  VCU_LE,IPC_LE
 SG_ PARtRgn3ObjStat : 11|4@0+ (1,0) [0|15] ""  VCU_LE,IPC_LE
 SG_ PARtRgn2ObjStat : 15|4@0+ (1,0) [0|15] ""  VCU_LE,IPC_LE
 SG_ PARtRgn1ObjStat : 3|4@0+ (1,0) [0|15] ""  VCU_LE,IPC_LE

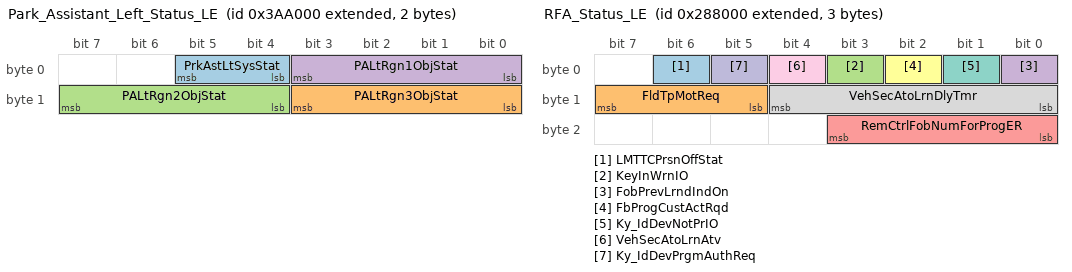
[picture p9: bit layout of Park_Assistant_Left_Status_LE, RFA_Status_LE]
BO_ 2151325696 Park_Assistant_Left_Status_LE: 2 CGM_LE
 SG_ PrkAstLtSysStat : 5|2@0+ (1,0) [0|3] ""  VCU_LE,IPC_LE
 SG_ PALtRgn3ObjStat : 11|4@0+ (1,0) [0|15] ""  VCU_LE,IPC_LE
 SG_ PALtRgn2ObjStat : 15|4@0+ (1,0) [0|15] ""  VCU_LE,IPC_LE
 SG_ PALtRgn1ObjStat : 3|4@0+ (1,0) [0|15] ""  VCU_LE,IPC_LE

BO_ 2150137856 RFA_Status_LE: 3 CGM_LE
 SG_ LMTTCPrsnOffStat : 6|1@0+ (1,0) [0|1] ""  Dummy_LE
 SG_ FldTpMotReq : 15|3@0+ (1,0) [0|7] ""  Dummy_LE
 SG_ KeyInWrnIO : 3|1@0+ (1,0) [0|1] ""  VCU_LE,IPC_LE
 SG_ FobPrevLrndIndOn : 0|1@0+ (1,0) [0|1] ""  Dummy_LE,VCU_LE,IPC_LE
 SG_ RemCtrlFobNumForProgER : 19|4@0+ (1,0) [0|15] ""  VCU_LE,IPC_LE
 SG_ FbProgCustActRqd : 2|1@0+ (1,0) [0|1] ""  Dummy_LE,VCU_LE,IPC_LE
 SG_ Ky_IdDevNotPrIO : 1|1@0+ (1,0) [0|1] ""  VCU_LE,IPC_LE
 SG_ VehSecAtoLrnDlyTmr : 12|5@0+ (1,0) [0|31] "min"  VCU_LE,IPC_LE
 SG_ VehSecAtoLrnAtv : 4|1@0+ (1,0) [0|1] ""  VCU_LE,IPC_LE
 SG_ Ky_IdDevPrgmAuthReq : 5|1@0+ (1,0) [0|1] ""  Dummy_LE

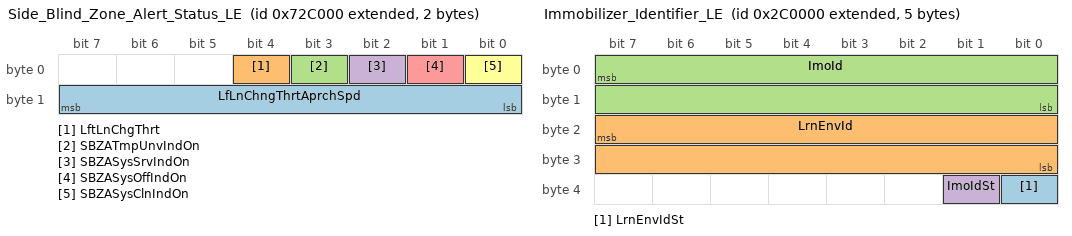
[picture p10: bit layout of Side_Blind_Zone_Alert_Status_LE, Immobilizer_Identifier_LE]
BO_ 2155003904 Side_Blind_Zone_Alert_Status_LE: 2 CGM_LE
 SG_ LfLnChngThrtAprchSpd : 15|8@0- (1,0) [-128|127] "km/h"  Dummy_LE
 SG_ LftLnChgThrt : 4|1@0+ (1,0) [0|1] ""  Dummy_LE
 SG_ SBZATmpUnvIndOn : 3|1@0+ (1,0) [0|1] ""  VCU_LE,IPC_LE
 SG_ SBZASysSrvIndOn : 2|1@0+ (1,0) [0|1] ""  VCU_LE,IPC_LE
 SG_ SBZASysOffIndOn : 1|1@0+ (1,0) [0|1] ""  VCU_LE,IPC_LE
 SG_ SBZASysClnIndOn : 0|1@0+ (1,0) [0|1] ""  VCU_LE,IPC_LE

BO_ 2150662144 Environment_Id_Resp_3_LE: 3 IPC_LE
 SG_ EnvIdRsp3 : 7|16@0+ (1,0) [0|65535] ""  CGM_LE
 SG_ EnvIdRspSt3 : 17|2@0+ (1,0) [0|3] ""  CGM_LE

BO_ 2150367232 Immobilizer_Identifier_LE: 5 CGM_LE
 SG_ LrnEnvIdSt : 32|1@0+ (1,0) [0|1] ""  VCU_LE,IPC_LE
 SG_ LrnEnvId : 23|16@0+ (1,0) [0|65535] ""  VCU_LE,IPC_LE
 SG_ ImoId : 7|16@0+ (1,0) [0|65535] ""  V2V_LE,VCU_LE,IPC_LE
 SG_ ImoIdSt : 33|1@0+ (1,0) [0|1] ""  VCU_LE,IPC_LE

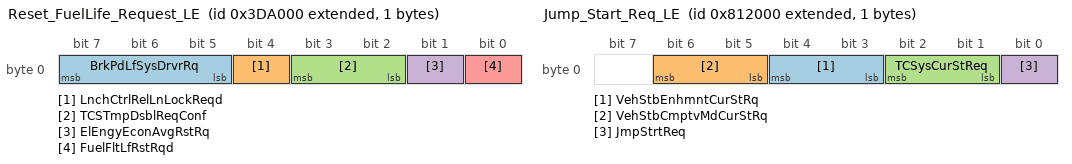
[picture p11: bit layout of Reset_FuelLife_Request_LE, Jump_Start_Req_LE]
BO_ 2151522304 Reset_FuelLife_Request_LE: 1 IPC_LE
 SG_ BrkPdLfSysDrvrRq : 7|3@0+ (1,0) [0|7] ""  CGM_LE
 SG_ LnchCtrlRelLnLockReqd : 4|1@0+ (1,0) [0|1] ""  CGM_LE
 SG_ TCSTmpDsblReqConf : 3|2@0+ (1,0) [0|3] ""  CGM_LE
 SG_ ElEngyEconAvgRstRq : 1|1@0+ (1,0) [0|1] ""  CGM_LE
 SG_ FuelFltLfRstRqd : 0|1@0+ (1,0) [0|1] ""  CGM_LE

BO_ 2153791488 ARB_State_LE: 1 CGM_LE
 SG_ ArtcldRngBrdSt : 2|3@0+ (1,0) [0|7] ""  VCU_LE,IPC_LE

BO_ 2150449152 Engine_Information_5_LE: 4 CGM_LE
 SG_ ESPDrvrExtIO : 29|1@0+ (1,0) [0|1] ""  VCU_LE,IPC_LE
 SG_ ESPDrvrDrStIndtrmntIO : 30|1@0+ (1,0) [0|1] ""  VCU_LE,IPC_LE
 SG_ ESPAutoPrkIO : 31|1@0+ (1,0) [0|1] ""  VCU_LE,IPC_LE
 SG_ ManTransIndReq : 28|3@0+ (1,0) [0|7] ""  VCU_LE,IPC_LE
 SG_ SrvcFlSysPrkInOpnArIO : 0|1@0+ (1,0) [0|1] ""  VCU_LE,IPC_LE
 SG_ TnDrvStblCtrlOffUnbIO : 2|1@0+ (1,0) [0|1] ""  VCU_LE,IPC_LE
 SG_ TnDrvTrCtrlOffUnbIO : 1|1@0+ (1,0) [0|1] ""  VCU_LE,IPC_LE
 SG_ ASIRI_Indication08 : 16|1@0+ (1,0) [0|1] ""  CSM_LE,VCU_LE,IPC_LE
 SG_ ASIRI_Indication07 : 17|1@0+ (1,0) [0|1] ""  CSM_LE,VCU_LE,IPC_LE
 SG_ ASIRI_Indication06 : 18|1@0+ (1,0) [0|1] ""  CSM_LE,VCU_LE,IPC_LE
 SG_ ASIRI_Indication05 : 19|1@0+ (1,0) [0|1] ""  CSM_LE,VCU_LE,IPC_LE
 SG_ ASIRI_Indication04 : 20|1@0+ (1,0) [0|1] ""  CSM_LE,VCU_LE,IPC_LE
 SG_ ASIRI_Indication03 : 21|1@0+ (1,0) [0|1] ""  CSM_LE,VCU_LE,IPC_LE
 SG_ ASIRI_Indication02 : 22|1@0+ (1,0) [0|1] ""  CSM_LE,VCU_LE,IPC_LE
 SG_ ASIRI_Indication01 : 23|1@0+ (1,0) [0|1] ""  CSM_LE,VCU_LE,IPC_LE
 SG_ SpdLmtrSttngTypAct : 25|2@0+ (1,0) [0|3] ""  CSM_LE,RadioHead_LE,VCU_LE,IPC_LE
 SG_ FuelSysNEmsRltMalfAct : 4|1@0+ (1,0) [0|1] ""  VCU_LE,IPC_LE
 SG_ InActFuelMdFuelLvlIO : 3|1@0+ (1,0) [0|1] ""  VCU_LE,IPC_LE
 SG_ EngInltSpcfcHmdtyV : 7|1@0+ (1,0) [0|1] ""  Dummy_LE
 SG_ EngInltSpcfcHmdtyM : 6|1@0+ (1,0) [0|1] ""  Dummy_LE
 SG_ EngInltSpcfcHmdty : 15|8@0+ (0.0196078,0) [0|4.999989] "% water"  Dummy_LE
 SG_ AltFuelSysOvrflDtdIO : 5|1@0+ (1,0) [0|1] ""  VCU_LE,IPC_LE

BO_ 2155945984 Jump_Start_Req_LE: 1 IPC_LE
 SG_ VehStbEnhmntCurStRq : 4|2@0+ (1,0) [0|3] ""  CGM_LE
 SG_ VehStbCmptvMdCurStRq : 6|2@0+ (1,0) [0|3] ""  CGM_LE
 SG_ TCSysCurStReq : 2|2@0+ (1,0) [0|3] ""  CGM_LE
 SG_ JmpStrtReq : 0|1@0+ (1,0) [0|1] ""  CGM_LE

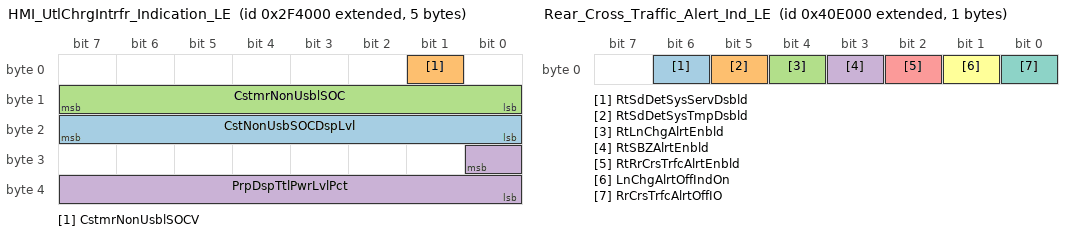
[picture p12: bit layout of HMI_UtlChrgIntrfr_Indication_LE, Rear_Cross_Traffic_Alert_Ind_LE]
BO_ 2150580224 HMI_UtlChrgIntrfr_Indication_LE: 5 CGM_LE
 SG_ CstNonUsbSOCDspLvl : 23|8@0+ (0.392157,0) [0|100.000035] "%"  VCU_LE,IPC_LE
 SG_ CstmrNonUsblSOCV : 1|1@0+ (1,0) [0|1] ""  CSM_LE,ONSTAR_LE,VCU_LE,IPC_LE
 SG_ CstmrNonUsblSOC : 15|8@0+ (0.392157,0) [0|100.000035] "%"  CSM_LE,ONSTAR_LE,VCU_LE,IPC_LE
 SG_ PrpDspTtlPwrLvlPct : 24|9@0- (0.392157,0) [-100.392192|100.000035] "%"  CSM_LE,RadioHead_LE,VCU_LE,IPC_LE

BO_ 2150391808 HMI_Hourmeter_Data_LE: 6 IPC_LE
 SG_ EngRunAtvTm : 31|24@0+ (1,0) [0|16777215] "min"  CSM_LE,CGM_LE
 SG_ EngIdlAtvTm : 7|24@0+ (1,0) [0|16777215] "min"  CGM_LE

BO_ 2151735296 Rear_Cross_Traffic_Alert_Ind_LE: 1 CGM_LE
 SG_ RtSdDetSysServDsbld : 6|1@0+ (1,0) [0|1] ""  Dummy_LE
 SG_ RtSdDetSysTmpDsbld : 5|1@0+ (1,0) [0|1] ""  Dummy_LE
 SG_ RtLnChgAlrtEnbld : 4|1@0+ (1,0) [0|1] ""  Dummy_LE
 SG_ RtSBZAlrtEnbld : 3|1@0+ (1,0) [0|1] ""  Dummy_LE
 SG_ RtRrCrsTrfcAlrtEnbld : 2|1@0+ (1,0) [0|1] ""  Dummy_LE
 SG_ LnChgAlrtOffIndOn : 1|1@0+ (1,0) [0|1] ""  VCU_LE,IPC_LE
 SG_ RrCrsTrfcAlrtOffIO : 0|1@0+ (1,0) [0|1] ""  VCU_LE,IPC_LE

BO_ 2159198208 ODI_IPC_2_AuxIP_LE: 8 IPC_LE
 SG_ ODI_IPC2AxIP : 7|64@0+ (1,0) [0|1.84467440737096E+019] ""  CHUD_LE,HUD_LE

BO_ 2159075328 ODI_IPC_2_DAB_LE: 8 IPC_LE
 SG_ ODI_IPC2DAB : 7|64@0+ (1,0) [0|1.84467440737096E+019] ""  CSM_LE,VCU_LE,RadioHead_LE

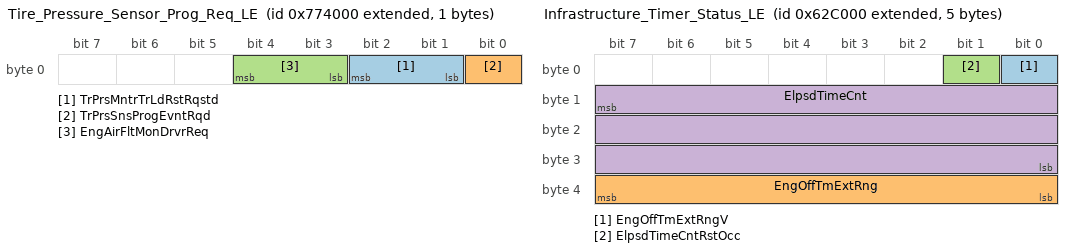
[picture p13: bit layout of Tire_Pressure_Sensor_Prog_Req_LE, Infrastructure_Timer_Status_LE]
BO_ 2155298816 Tire_Pressure_Sensor_Prog_Req_LE: 1 IPC_LE
 SG_ TrPrsMntrTrLdRstRqstd : 2|2@0+ (1,0) [0|3] ""  CGM_LE
 SG_ TrPrsSnsProgEvntRqd : 0|1@0+ (1,0) [0|1] ""  CGM_LE
 SG_ EngAirFltMonDrvrReq : 4|2@0+ (1,0) [0|3] ""  CGM_LE

BO_ 2157985792 Fob_Programming_Request_LE: 1 IPC_LE
 SG_ FobProgEvntRqd : 0|1@0+ (1,0) [0|1] ""  CSM_LE,CGM_LE

BO_ 2153955328 Infrastructure_Timer_Status_LE: 5 CGM_LE
 SG_ EngOffTmExtRngV : 0|1@0+ (1,0) [0|1] ""  EDI_LE,VCU_LE,IPC_LE
 SG_ EngOffTmExtRng : 39|8@0+ (4,0) [0|1020] "min"  EDI_LE,VCU_LE,IPC_LE
 SG_ ElpsdTimeCntRstOcc : 1|1@0+ (1,0) [0|1] ""  EDI_LE,VCU_LE,IPC_LE
 SG_ ElpsdTimeCnt : 15|24@0+ (1,0) [0|16777215] "min"  EDI_LE,VCU_LE,IPC_LE

BO_TX_BU_ 2159067136 : CSM_LE,VCU_LE,RadioHead_LE;
BO_TX_BU_ 595 : CGM_LE,CSM_LE,TCP_LE,ONSTAR_LE;
BO_TX_BU_ 590 : CSM_LE,CGM_LE,TCP_LE,ONSTAR_LE;
BO_TX_BU_ 586 : CSM_LE,CGM_LE,TCP_LE,ONSTAR_LE;
BO_TX_BU_ 596 : CSM_LE,CGM_LE,TCP_LE,ONSTAR_LE;
BO_TX_BU_ 582 : CSM_LE,CGM_LE,TCP_LE,ONSTAR_LE;
BO_TX_BU_ 257 : CSM_LE,TCP_LE,ONSTAR_LE,CGM_LE;
BO_TX_BU_ 594 : CSM_LE,CGM_LE,TCP_LE,ONSTAR_LE;
BO_TX_BU_ 592 : CSM_LE,CGM_LE,TCP_LE,ONSTAR_LE;
BO_TX_BU_ 588 : CSM_LE,CGM_LE,TCP_LE,ONSTAR_LE;
BO_TX_BU_ 585 : CSM_LE,CGM_LE,TCP_LE,ONSTAR_LE;
BO_TX_BU_ 584 : CSM_LE,CGM_LE,TCP_LE,ONSTAR_LE;
BO_TX_BU_ 580 : CGM_LE,TCP_LE,ONSTAR_LE;
BO_TX_BU_ 598 : CGM_LE,CSM_LE,TCP_LE,ONSTAR_LE;
BO_TX_BU_ 589 : CSM_LE,CGM_LE;
BO_TX_BU_ 2154676224 : VCU_LE,IPC_LE;
BO_TX_BU_ 2150662144 : VCU_LE,IPC_LE;
BO_TX_BU_ 2151522304 : VCU_LE,IPC_LE;
BO_TX_BU_ 2155945984 : VCU_LE,IPC_LE;
BO_TX_BU_ 2150391808 : VCU_LE,IPC_LE;
BO_TX_BU_ 2159198208 : VCU_LE,IPC_LE;
BO_TX_BU_ 2159075328 : VCU_LE,IPC_LE;
BO_TX_BU_ 2155298816 : VCU_LE,IPC_LE;
BO_TX_BU_ 2157985792 : VCU_LE,IPC_LE;
CM_ SG_ 2150785024 AirbgAccelOrien "Orientation of first accelerometer axis.  0 degrees is right side of vehicle, 90 degrees is front of vehicle.  Second axis given by adding 90 degrees to first axis.";
CM_ BO_ 2153807872 "LAP: Open Switch ???";
BA_DEF_ SG_  "VNSigPrimaryTriggering" ENUM  "No","Yes","DLCLS","DLCHS","DLCCE","DLCFO";
BA_DEF_ SG_  "VNSigRemoteDiagnostics" ENUM  "No","Yes","DLCLS","DLCHS","DLCCE","DLCFO";
BA_DEF_ SG_  "VNSigInfotainment" ENUM  "No","Yes","DLCLS","DLCHS","DLCCE","DLCFO";
BA_DEF_ SG_  "VNSigParkedVehicle" ENUM  "No","Yes","DLCLS","DLCHS","DLCCE","DLCFO";
BA_DEF_ SG_  "VNSigIntermediate" ENUM  "No","Yes","DLCLS","DLCHS","DLCCE","DLCFO";
BA_DEF_ SG_  "VNSigUnused_4" ENUM  "No","Yes","DLCLS","DLCHS","DLCCE","DLCFO";
BA_DEF_ SG_  "SignalType" STRING ;
BA_DEF_ SG_  "PacketOrder" INT 0 65535;
BA_DEF_ SG_  "SignalLongName" STRING ;
BA_DEF_ SG_  "GenSigStartValue" INT 0 65535;
BA_DEF_ SG_  "VNSigDiagnostic" ENUM  "No","Yes","DLCLS","DLCHS","DLCCE","DLCFO";
BA_DEF_ SG_  "VNSigAllNodes" ENUM  "No","Yes","DLCLS","DLCHS","DLCCE","DLCFO";
BA_DEF_ SG_  "GenSigDeltaValue" INT 0 0;
BA_DEF_ SG_  "GenSigSendType" ENUM  "not used","not used","not used","not used","not used","not used","not used","NoSigSendType","not used","not used","OnAnyChange","OnChangeIfActive","OnDelta","DLCLS","DLCHS","DLCCE","DLCFO";
BA_DEF_ SG_  "GenSigSendOnInit" ENUM  "Not Initialized","Application","Handler","DLCLS","DLCHS","DLCCE","DLCFO";
BA_DEF_ BO_  "AppGenMsgCycleTime" INT 0 0;
BA_DEF_ BO_  "TpTxIndex" INT 0 99;
BA_DEF_ BO_  "GenMsgILSupport" ENUM  "No","Yes","DLCLS","DLCHS","DLCCE","DLCFO";
BA_DEF_ BO_  "TpApplType" STRING ;
BA_DEF_ BO_  "Prio" INT 0 7;
BA_DEF_ BO_  "MessageSubnet" ENUM  "LS","MS","HS","CE","PE","HV","FO","S1","HE","LE","HE2","DLCLS","DLCHS","DLCCE","DLCFO";
BA_DEF_ BO_  "GenMsgMandatoryToSupervision" ENUM  "No","Yes","DLCLS","DLCHS","DLCCE","DLCFO";
BA_DEF_ BO_  "DiagState" ENUM  "No","Yes","DLCLS","DLCHS","DLCCE","DLCFO";
BA_DEF_ BO_  "GenMsgStartDelayTime" INT 0 100000;
BA_DEF_ BO_  "GenMsgDelayTime" INT 0 100000;
BA_DEF_ BO_  "GenMsgCycleTime" INT 0 100000;
BA_DEF_ BO_  "GenMsgSendType" ENUM  "cyclicX","spontanX","cyclicIfActiveX","spontanWithDelay","cyclicAndSpontanX","cyclicAndSpontanWithDelay","spontanWithRepitition","cyclicIfActiveAndSpontanWD","DLCLS","DLCHS","DLCCE","DLCFO";
BA_DEF_ BO_  "DiagResponse" ENUM  "No","Yes","DLCLS","DLCHS","DLCCE","DLCFO";
BA_DEF_ BO_  "DiagRequest" ENUM  "No","Yes","DLCLS","DLCHS","DLCCE","DLCFO";
BA_DEF_ BO_  "NmMessage" ENUM  "No","Yes","DLCLS","DLCHS","DLCCE","DLCFO";
BA_DEF_REL_ BU_SG_REL_  "GenSigSuprvRespComment" STRING ;
BA_DEF_REL_ BU_SG_REL_  "GenSigVBitResp" ENUM  "No","Yes","DLCLS","DLCHS","DLCCE","DLCFO";
BA_DEF_REL_ BU_SG_REL_  "GenSigVBitRespComment" STRING ;
BA_DEF_REL_ BU_SG_REL_  "GenSigVDAFailComment" STRING ;
BA_DEF_REL_ BU_SG_REL_  "GenSigVDAFailResp" ENUM  "No","Yes","DLCLS","DLCHS","DLCCE","DLCFO";
BA_DEF_REL_ BU_SG_REL_  "GenSigRxStartValue" STRING ;
BA_DEF_REL_ BU_SG_REL_  "GenSigSuprvRespSubValue" INT 0 65535;
BA_DEF_REL_ BU_SG_REL_  "GenSigSuprvResp" ENUM  "None","Notify App","Substitute Default","DLCLS","DLCHS","DLCCE","DLCFO";
BA_DEF_REL_ BU_SG_REL_  "GenSigTimeoutMsg" HEX -2147483648 268435455;
BA_DEF_DEF_  "VNSigPrimaryTriggering" "No";
BA_DEF_DEF_  "VNSigRemoteDiagnostics" "No";
BA_DEF_DEF_  "VNSigInfotainment" "No";
BA_DEF_DEF_  "VNSigParkedVehicle" "No";
BA_DEF_DEF_  "VNSigIntermediate" "No";
BA_DEF_DEF_  "VNSigUnused_4" "No";
BA_DEF_DEF_  "SignalType" "";
BA_DEF_DEF_  "PacketOrder" 0;
BA_DEF_DEF_  "SignalLongName" "";
BA_DEF_DEF_  "GenSigStartValue" 0;
BA_DEF_DEF_  "VNSigDiagnostic" "No";
BA_DEF_DEF_  "VNSigAllNodes" "No";
BA_DEF_DEF_  "GenSigDeltaValue" 0;
BA_DEF_DEF_  "GenSigSendType" "NoSigSendType";
BA_DEF_DEF_  "GenSigSendOnInit" "Not Initialized";
BA_DEF_DEF_  "AppGenMsgCycleTime" 0;
BA_DEF_DEF_  "TpTxIndex" 0;
BA_DEF_DEF_  "GenMsgILSupport" "Yes";
BA_DEF_DEF_  "TpApplType" "";
BA_DEF_DEF_  "Prio" 4;
BA_DEF_DEF_  "MessageSubnet" "FO";
BA_DEF_DEF_  "GenMsgMandatoryToSupervision" "No";
BA_DEF_DEF_  "DiagState" "No";
BA_DEF_DEF_  "GenMsgStartDelayTime" 0;
BA_DEF_DEF_  "GenMsgDelayTime" 0;
BA_DEF_DEF_  "GenMsgCycleTime" 0;
BA_DEF_DEF_  "GenMsgSendType" "spontanX";
BA_DEF_DEF_  "DiagResponse" "No";
BA_DEF_DEF_  "DiagRequest" "No";
BA_DEF_DEF_  "NmMessage" "No";
BA_DEF_DEF_REL_ "GenSigSuprvRespComment" "";
BA_DEF_DEF_REL_ "GenSigVBitResp" "No";
BA_DEF_DEF_REL_ "GenSigVBitRespComment" "";
BA_DEF_DEF_REL_ "GenSigVDAFailComment" "";
BA_DEF_DEF_REL_ "GenSigVDAFailResp" "No";
BA_DEF_DEF_REL_ "GenSigRxStartValue" "";
BA_DEF_DEF_REL_ "GenSigSuprvRespSubValue" 0;
BA_DEF_DEF_REL_ "GenSigSuprvResp" "None";
BA_DEF_DEF_REL_ "GenSigTimeoutMsg" 0;
BA_ "MessageSubnet" BO_ 2154807296 9;
BA_ "GenMsgDelayTime" BO_ 2154807296 100;
BA_ "MessageSubnet" BO_ 2155970560 9;
BA_ "GenMsgDelayTime" BO_ 2155970560 100;
BA_ "MessageSubnet" BO_ 2159067136 9;
BA_ "GenMsgDelayTime" BO_ 2159067136 10;
BA_ "MessageSubnet" BO_ 2151686144 9;
BA_ "GenMsgDelayTime" BO_ 2151686144 100;
BA_ "Prio" BO_ 595 0;
BA_ "MessageSubnet" BO_ 595 9;
BA_ "DiagRequest" BO_ 595 1;
BA_ "MessageSubnet" BO_ 2153914368 9;
BA_ "GenMsgDelayTime" BO_ 2153914368 100;
BA_ "MessageSubnet" BO_ 2150629376 9;
BA_ "GenMsgDelayTime" BO_ 2150629376 100;
BA_ "MessageSubnet" BO_ 2153390080 9;
BA_ "GenMsgDelayTime" BO_ 2153390080 500;
BA_ "MessageSubnet" BO_ 2151415808 9;
BA_ "GenMsgDelayTime" BO_ 2151415808 100;
BA_ "MessageSubnet" BO_ 2150080512 9;
BA_ "GenMsgDelayTime" BO_ 2150080512 100;
BA_ "MessageSubnet" BO_ 2153988096 9;
BA_ "GenMsgDelayTime" BO_ 2153988096 100;
BA_ "MessageSubnet" BO_ 2151915520 9;
BA_ "GenMsgCycleTime" BO_ 2151915520 250;
BA_ "GenMsgSendType" BO_ 2151915520 0;
BA_ "MessageSubnet" BO_ 2151489536 9;
BA_ "GenMsgDelayTime" BO_ 2151489536 100;
BA_ "Prio" BO_ 590 0;
BA_ "MessageSubnet" BO_ 590 9;
BA_ "DiagRequest" BO_ 590 1;
BA_ "Prio" BO_ 586 0;
BA_ "MessageSubnet" BO_ 586 9;
BA_ "DiagRequest" BO_ 586 1;
BA_ "Prio" BO_ 596 0;
BA_ "MessageSubnet" BO_ 596 9;
BA_ "DiagRequest" BO_ 596 1;
BA_ "Prio" BO_ 582 0;
BA_ "MessageSubnet" BO_ 582 9;
BA_ "DiagRequest" BO_ 582 1;
BA_ "GenMsgILSupport" BO_ 257 0;
BA_ "Prio" BO_ 257 0;
BA_ "MessageSubnet" BO_ 257 9;
BA_ "DiagState" BO_ 257 1;
BA_ "Prio" BO_ 594 0;
BA_ "MessageSubnet" BO_ 594 9;
BA_ "DiagRequest" BO_ 594 1;
BA_ "Prio" BO_ 592 0;
BA_ "MessageSubnet" BO_ 592 9;
BA_ "DiagRequest" BO_ 592 1;
BA_ "Prio" BO_ 588 0;
BA_ "MessageSubnet" BO_ 588 9;
BA_ "DiagRequest" BO_ 588 1;
BA_ "GenMsgILSupport" BO_ 585 0;
BA_ "Prio" BO_ 585 0;
BA_ "MessageSubnet" BO_ 585 9;
BA_ "DiagRequest" BO_ 585 1;
BA_ "Prio" BO_ 584 0;
BA_ "MessageSubnet" BO_ 584 9;
BA_ "DiagRequest" BO_ 584 1;
BA_ "Prio" BO_ 580 0;
BA_ "MessageSubnet" BO_ 580 9;
BA_ "DiagRequest" BO_ 580 1;
BA_ "Prio" BO_ 598 0;
BA_ "MessageSubnet" BO_ 598 9;
BA_ "DiagRequest" BO_ 598 1;
BA_ "Prio" BO_ 589 0;
BA_ "MessageSubnet" BO_ 589 9;
BA_ "DiagRequest" BO_ 589 1;
BA_ "Prio" BO_ 1612 0;
BA_ "MessageSubnet" BO_ 1612 9;
BA_ "DiagResponse" BO_ 1612 1;
BA_ "Prio" BO_ 1580 0;
BA_ "MessageSubnet" BO_ 1580 9;
BA_ "GenMsgCycleTime" BO_ 1580 3000;
BA_ "GenMsgSendType" BO_ 1580 0;
BA_ "NmMessage" BO_ 1580 1;
BA_ "GenMsgILSupport" BO_ 1356 0;
BA_ "TpApplType" BO_ 1356 "DiagUUDTResponse";
BA_ "Prio" BO_ 1356 0;
BA_ "MessageSubnet" BO_ 1356 9;
BA_ "MessageSubnet" BO_ 2154676224 9;
BA_ "GenMsgDelayTime" BO_ 2154676224 100;
BA_ "MessageSubnet" BO_ 2152857600 9;
BA_ "GenMsgDelayTime" BO_ 2152857600 100;
BA_ "MessageSubnet" BO_ 2154995712 9;
BA_ "GenMsgDelayTime" BO_ 2154995712 100;
BA_ "MessageSubnet" BO_ 2150817792 9;
BA_ "GenMsgDelayTime" BO_ 2150817792 10;
BA_ "MessageSubnet" BO_ 2150809600 9;
BA_ "GenMsgDelayTime" BO_ 2150809600 10;
BA_ "MessageSubnet" BO_ 2150801408 9;
BA_ "GenMsgDelayTime" BO_ 2150801408 10;
BA_ "MessageSubnet" BO_ 2150793216 9;
BA_ "GenMsgDelayTime" BO_ 2150793216 10;
BA_ "MessageSubnet" BO_ 2150785024 9;
BA_ "GenMsgDelayTime" BO_ 2150785024 10;
BA_ "MessageSubnet" BO_ 2150825984 9;
BA_ "GenMsgDelayTime" BO_ 2150825984 10;
BA_ "MessageSubnet" BO_ 2151268352 9;
BA_ "GenMsgDelayTime" BO_ 2151268352 100;
BA_ "MessageSubnet" BO_ 2154659840 9;
BA_ "GenMsgDelayTime" BO_ 2154659840 100;
BA_ "MessageSubnet" BO_ 2149974016 9;
BA_ "GenMsgDelayTime" BO_ 2149974016 100;
BA_ "MessageSubnet" BO_ 2155929600 9;
BA_ "GenMsgCycleTime" BO_ 2155929600 1000;
BA_ "GenMsgSendType" BO_ 2155929600 0;
BA_ "Prio" BO_ 2153807872 3;
BA_ "MessageSubnet" BO_ 2153807872 9;
BA_ "GenMsgDelayTime" BO_ 2153807872 100;
BA_ "MessageSubnet" BO_ 2154938368 9;
BA_ "GenMsgDelayTime" BO_ 2154938368 100;
BA_ "MessageSubnet" BO_ 2151751680 9;
BA_ "GenMsgDelayTime" BO_ 2151751680 100;
BA_ "MessageSubnet" BO_ 2152464384 9;
BA_ "GenMsgDelayTime" BO_ 2152464384 100;
BA_ "MessageSubnet" BO_ 2151342080 9;
BA_ "GenMsgDelayTime" BO_ 2151342080 100;
BA_ "MessageSubnet" BO_ 2151325696 9;
BA_ "GenMsgDelayTime" BO_ 2151325696 100;
BA_ "MessageSubnet" BO_ 2150137856 9;
BA_ "GenMsgDelayTime" BO_ 2150137856 100;
BA_ "MessageSubnet" BO_ 2155003904 9;
BA_ "GenMsgDelayTime" BO_ 2155003904 100;
BA_ "MessageSubnet" BO_ 2150662144 9;
BA_ "GenMsgDelayTime" BO_ 2150662144 100;
BA_ "MessageSubnet" BO_ 2150367232 9;
BA_ "GenMsgStartDelayTime" BO_ 2150367232 170;
BA_ "GenMsgCycleTime" BO_ 2150367232 300;
BA_ "GenMsgSendType" BO_ 2150367232 0;
BA_ "MessageSubnet" BO_ 2151522304 9;
BA_ "GenMsgDelayTime" BO_ 2151522304 100;
BA_ "MessageSubnet" BO_ 2153791488 9;
BA_ "GenMsgDelayTime" BO_ 2153791488 100;
BA_ "MessageSubnet" BO_ 2150449152 9;
BA_ "GenMsgDelayTime" BO_ 2150449152 100;
BA_ "MessageSubnet" BO_ 2155945984 9;
BA_ "GenMsgDelayTime" BO_ 2155945984 100;
BA_ "MessageSubnet" BO_ 2150580224 9;
BA_ "GenMsgDelayTime" BO_ 2150580224 100;
BA_ "MessageSubnet" BO_ 2150391808 9;
BA_ "GenMsgDelayTime" BO_ 2150391808 100;
BA_ "MessageSubnet" BO_ 2151735296 9;
BA_ "GenMsgDelayTime" BO_ 2151735296 100;
BA_ "MessageSubnet" BO_ 2159198208 9;
BA_ "GenMsgDelayTime" BO_ 2159198208 10;
BA_ "MessageSubnet" BO_ 2159075328 9;
BA_ "GenMsgDelayTime" BO_ 2159075328 10;
BA_ "MessageSubnet" BO_ 2155298816 9;
BA_ "GenMsgDelayTime" BO_ 2155298816 100;
BA_ "MessageSubnet" BO_ 2157985792 9;
BA_ "GenMsgDelayTime" BO_ 2157985792 100;
BA_ "MessageSubnet" BO_ 2153955328 9;
BA_ "GenMsgDelayTime" BO_ 2153955328 100;
BA_ "GenSigSendType" SG_ 2154807296 TnDrvStBltShftIntrlkCsStAvl 10;
BA_ "SignalType" SG_ 2154807296 TnDrvStBltShftIntrlkCsStAvl "BLN";
BA_ "SignalLongName" SG_ 2154807296 TnDrvStBltShftIntrlkCsStAvl "Teen Driver Seat Belt Shift Interlock Customization Setting Available";
BA_ "VNSigAllNodes" SG_ 2154807296 TnDrvStBltShftIntrlkCsStAvl 1;
BA_ "GenSigSendType" SG_ 2154807296 TnDrvStBltShftIntrlkCrStVal 10;
BA_ "SignalType" SG_ 2154807296 TnDrvStBltShftIntrlkCrStVal "ENM";
BA_ "SignalLongName" SG_ 2154807296 TnDrvStBltShftIntrlkCrStVal "Teen Driver Seat Belt Shift Interlock Customization Current Setting Value";
BA_ "VNSigAllNodes" SG_ 2154807296 TnDrvStBltShftIntrlkCrStVal 1;
BA_ "GenSigSendType" SG_ 2154807296 StBltShftIntrlkCsStAvl 10;
BA_ "SignalType" SG_ 2154807296 StBltShftIntrlkCsStAvl "BLN";
BA_ "SignalLongName" SG_ 2154807296 StBltShftIntrlkCsStAvl "Seat Belt Shift Interlock Customization Setting Available";
BA_ "VNSigAllNodes" SG_ 2154807296 StBltShftIntrlkCsStAvl 1;
BA_ "GenSigSendType" SG_ 2154807296 StBltShftIntrlkCsCrStVal 10;
BA_ "SignalType" SG_ 2154807296 StBltShftIntrlkCsCrStVal "ENM";
BA_ "SignalLongName" SG_ 2154807296 StBltShftIntrlkCsCrStVal "Seat Belt Shift Interlock Customization Current Setting Value";
BA_ "VNSigAllNodes" SG_ 2154807296 StBltShftIntrlkCsCrStVal 1;
BA_ "GenSigSendType" SG_ 2154807296 EASSI_UnsdRsrvd2 10;
BA_ "SignalType" SG_ 2154807296 EASSI_UnsdRsrvd2 "BLN";
BA_ "PacketOrder" SG_ 2154807296 EASSI_UnsdRsrvd2 7;
BA_ "SignalLongName" SG_ 2154807296 EASSI_UnsdRsrvd2 "Engine Auto Start Stop Information : Unused and Reserved 2";
BA_ "VNSigAllNodes" SG_ 2154807296 EASSI_UnsdRsrvd2 1;
BA_ "GenSigSendType" SG_ 2154807296 EASSI_StlDetd 10;
BA_ "SignalType" SG_ 2154807296 EASSI_StlDetd "BLN";
BA_ "PacketOrder" SG_ 2154807296 EASSI_StlDetd 5;
BA_ "SignalLongName" SG_ 2154807296 EASSI_StlDetd "Engine Auto Start Stop Information : Stall Detected";
BA_ "VNSigAllNodes" SG_ 2154807296 EASSI_StlDetd 1;
BA_ "GenSigSendType" SG_ 2154807296 EASSI_TrqDetd 10;
BA_ "SignalType" SG_ 2154807296 EASSI_TrqDetd "BLN";
BA_ "PacketOrder" SG_ 2154807296 EASSI_TrqDetd 4;
BA_ "SignalLongName" SG_ 2154807296 EASSI_TrqDetd "Engine Auto Start Stop Information : Torque Detected";
BA_ "VNSigAllNodes" SG_ 2154807296 EASSI_TrqDetd 1;
BA_ "GenSigSendType" SG_ 2154807296 EASSI_FuelReqOn 10;
BA_ "SignalType" SG_ 2154807296 EASSI_FuelReqOn "BLN";
BA_ "PacketOrder" SG_ 2154807296 EASSI_FuelReqOn 3;
BA_ "SignalLongName" SG_ 2154807296 EASSI_FuelReqOn "Engine Auto Start Stop Information : Fuel Requested On";
BA_ "VNSigAllNodes" SG_ 2154807296 EASSI_FuelReqOn 1;
BA_ "GenSigSendType" SG_ 2154807296 EASSI_StrtTyp 10;
BA_ "SignalType" SG_ 2154807296 EASSI_StrtTyp "ENM";
BA_ "PacketOrder" SG_ 2154807296 EASSI_StrtTyp 2;
BA_ "SignalLongName" SG_ 2154807296 EASSI_StrtTyp "Engine Auto Start Stop Information : Start Type";
BA_ "VNSigAllNodes" SG_ 2154807296 EASSI_StrtTyp 1;
BA_ "GenSigSendType" SG_ 2154807296 EASSI_StrtStpSt 10;
BA_ "SignalType" SG_ 2154807296 EASSI_StrtStpSt "ENM";
BA_ "PacketOrder" SG_ 2154807296 EASSI_StrtStpSt 1;
BA_ "SignalLongName" SG_ 2154807296 EASSI_StrtStpSt "Engine Auto Start Stop Information : Start Stop State";
BA_ "VNSigAllNodes" SG_ 2154807296 EASSI_StrtStpSt 1;
BA_ "GenSigSendType" SG_ 2154807296 EASSI_TorqDetdIndet 10;
BA_ "SignalType" SG_ 2154807296 EASSI_TorqDetdIndet "BLN";
BA_ "PacketOrder" SG_ 2154807296 EASSI_TorqDetdIndet 6;
BA_ "SignalLongName" SG_ 2154807296 EASSI_TorqDetdIndet "Engine Auto Start Stop Information : Torque Detected Indeterminate";
BA_ "VNSigAllNodes" SG_ 2154807296 EASSI_TorqDetdIndet 1;
BA_ "GenSigSendType" SG_ 2154807296 EngAutoStpNotProb 10;
BA_ "SignalType" SG_ 2154807296 EngAutoStpNotProb "BLN";
BA_ "SignalLongName" SG_ 2154807296 EngAutoStpNotProb "Engine Auto Stop Not Probable";
BA_ "VNSigAllNodes" SG_ 2154807296 EngAutoStpNotProb 1;
BA_ "GenSigSendType" SG_ 2154807296 AFLMnu3CstStAvl 10;
BA_ "GenSigSendOnInit" SG_ 2154807296 AFLMnu3CstStAvl 2;
BA_ "SignalType" SG_ 2154807296 AFLMnu3CstStAvl "BLN";
BA_ "SignalLongName" SG_ 2154807296 AFLMnu3CstStAvl "Adaptive Forward Lighting Menu 3 Customization Setting Available";
BA_ "VNSigAllNodes" SG_ 2154807296 AFLMnu3CstStAvl 1;
BA_ "GenSigSendType" SG_ 2154807296 AFLMnu2CstStAvl 10;
BA_ "GenSigSendOnInit" SG_ 2154807296 AFLMnu2CstStAvl 2;
BA_ "SignalType" SG_ 2154807296 AFLMnu2CstStAvl "BLN";
BA_ "SignalLongName" SG_ 2154807296 AFLMnu2CstStAvl "Adaptive Forward Lighting Menu 2 Customization Setting Available";
BA_ "VNSigAllNodes" SG_ 2154807296 AFLMnu2CstStAvl 1;
BA_ "GenSigSendType" SG_ 2154807296 AFLGPSMnu2CstStAvl 10;
BA_ "GenSigSendOnInit" SG_ 2154807296 AFLGPSMnu2CstStAvl 2;
BA_ "SignalType" SG_ 2154807296 AFLGPSMnu2CstStAvl "BLN";
BA_ "SignalLongName" SG_ 2154807296 AFLGPSMnu2CstStAvl "Adaptive Forward Lighting With GPS Menu 2 Customization Setting Avail";
BA_ "VNSigAllNodes" SG_ 2154807296 AFLGPSMnu2CstStAvl 1;
BA_ "GenSigSendType" SG_ 2154807296 AFLGPSCstStAvl 10;
BA_ "GenSigSendOnInit" SG_ 2154807296 AFLGPSCstStAvl 2;
BA_ "SignalType" SG_ 2154807296 AFLGPSCstStAvl "BLN";
BA_ "SignalLongName" SG_ 2154807296 AFLGPSCstStAvl "Adaptive Forward Lighting With GPS Customization Setting Available";
BA_ "VNSigAllNodes" SG_ 2154807296 AFLGPSCstStAvl 1;
BA_ "GenSigSendType" SG_ 2154807296 AFLGPSCstCrStVal 10;
BA_ "GenSigSendOnInit" SG_ 2154807296 AFLGPSCstCrStVal 2;
BA_ "SignalType" SG_ 2154807296 AFLGPSCstCrStVal "ENM";
BA_ "SignalLongName" SG_ 2154807296 AFLGPSCstCrStVal "Adaptive Forward Lighting With GPS Customization Current Setting Value";
BA_ "VNSigAllNodes" SG_ 2154807296 AFLGPSCstCrStVal 1;
BA_ "GenSigSendType" SG_ 2154807296 AFLCstStAvl 10;
BA_ "GenSigSendOnInit" SG_ 2154807296 AFLCstStAvl 2;
BA_ "SignalType" SG_ 2154807296 AFLCstStAvl "BLN";
BA_ "SignalLongName" SG_ 2154807296 AFLCstStAvl "Adaptive Forward Lighting Customization Setting Available";
BA_ "VNSigAllNodes" SG_ 2154807296 AFLCstStAvl 1;
BA_ "GenSigSendType" SG_ 2154807296 AFLCstCrStVal 10;
BA_ "GenSigSendOnInit" SG_ 2154807296 AFLCstCrStVal 2;
BA_ "SignalType" SG_ 2154807296 AFLCstCrStVal "ENM";
BA_ "SignalLongName" SG_ 2154807296 AFLCstCrStVal "Adaptive Forward Lighting Customization Current Setting Value";
BA_ "VNSigAllNodes" SG_ 2154807296 AFLCstCrStVal 1;
BA_ "GenSigSendType" SG_ 2155970560 ClmCntLdShdLvlRq 10;
BA_ "SignalType" SG_ 2155970560 ClmCntLdShdLvlRq "ENM";
BA_ "SignalLongName" SG_ 2155970560 ClmCntLdShdLvlRq "Climate Control Load Shedding Level Request";
BA_ "VNSigAllNodes" SG_ 2155970560 ClmCntLdShdLvlRq 1;
BA_ "GenSigSendType" SG_ 2155970560 ClmCntBatSaverIO 10;
BA_ "SignalType" SG_ 2155970560 ClmCntBatSaverIO "BLN";
BA_ "SignalLongName" SG_ 2155970560 ClmCntBatSaverIO "Climate Control Battery Saver Indication On";
BA_ "VNSigAllNodes" SG_ 2155970560 ClmCntBatSaverIO 1;
BA_ "GenSigDeltaValue" SG_ 2159067136 ODI_DAB2IPC 1;
BA_ "GenSigSendType" SG_ 2159067136 ODI_DAB2IPC 12;
BA_ "VNSigInfotainment" SG_ 2159067136 ODI_DAB2IPC 1;
BA_ "SignalType" SG_ 2159067136 ODI_DAB2IPC "UNM";
BA_ "SignalLongName" SG_ 2159067136 ODI_DAB2IPC "Open Display Interface DAB 2 IPC";
BA_ "VNSigAllNodes" SG_ 2159067136 ODI_DAB2IPC 1;
BA_ "GenSigSendType" SG_ 2151686144 RrCmrDeplmntReqtsd 10;
BA_ "GenSigSendOnInit" SG_ 2151686144 RrCmrDeplmntReqtsd 2;
BA_ "SignalType" SG_ 2151686144 RrCmrDeplmntReqtsd "BLN";
BA_ "SignalLongName" SG_ 2151686144 RrCmrDeplmntReqtsd "Rear Camera Deployment Requested";
BA_ "VNSigAllNodes" SG_ 2151686144 RrCmrDeplmntReqtsd 1;
BA_ "GenSigSendType" SG_ 2151686144 NoSDCrdPrIO 10;
BA_ "SignalType" SG_ 2151686144 NoSDCrdPrIO "BLN";
BA_ "SignalLongName" SG_ 2151686144 NoSDCrdPrIO "No SD Card Present Indication On";
BA_ "VNSigAllNodes" SG_ 2151686144 NoSDCrdPrIO 1;
BA_ "GenSigSendType" SG_ 2151686144 SDCrdFullIO 10;
BA_ "SignalType" SG_ 2151686144 SDCrdFullIO "BLN";
BA_ "SignalLongName" SG_ 2151686144 SDCrdFullIO "SD Card Full Indication On";
BA_ "VNSigAllNodes" SG_ 2151686144 SDCrdFullIO 1;
BA_ "GenSigSendType" SG_ 2151686144 SDCrdErrIO 10;
BA_ "SignalType" SG_ 2151686144 SDCrdErrIO "BLN";
BA_ "SignalLongName" SG_ 2151686144 SDCrdErrIO "SD Card Error Indication On";
BA_ "VNSigAllNodes" SG_ 2151686144 SDCrdErrIO 1;
BA_ "SignalType" SG_ 595 DgnInf "UNM";
BA_ "SignalLongName" SG_ 595 DgnInf "Diagnostic Information";
BA_ "VNSigDiagnostic" SG_ 595 DgnInf 1;
BA_ "VNSigAllNodes" SG_ 595 DgnInf 1;
BA_ "GenSigDeltaValue" SG_ 2153914368 EUSS_TrEgUgScrMxScVal 1;
BA_ "GenSigSendType" SG_ 2153914368 EUSS_TrEgUgScrMxScVal 12;
BA_ "GenSigSendOnInit" SG_ 2153914368 EUSS_TrEgUgScrMxScVal 1;
BA_ "VNSigInfotainment" SG_ 2153914368 EUSS_TrEgUgScrMxScVal 1;
BA_ "SignalType" SG_ 2153914368 EUSS_TrEgUgScrMxScVal "SNM";
BA_ "PacketOrder" SG_ 2153914368 EUSS_TrEgUgScrMxScVal 8;
BA_ "SignalLongName" SG_ 2153914368 EUSS_TrEgUgScrMxScVal "Energy Usage Score Scaling : Terrain Energy Usage Score Maximum Scale Value";
BA_ "VNSigAllNodes" SG_ 2153914368 EUSS_TrEgUgScrMxScVal 1;
BA_ "GenSigDeltaValue" SG_ 2153914368 EUSS_TrEgUgScrMnScVal 1;
BA_ "GenSigSendType" SG_ 2153914368 EUSS_TrEgUgScrMnScVal 12;
BA_ "GenSigSendOnInit" SG_ 2153914368 EUSS_TrEgUgScrMnScVal 1;
BA_ "VNSigInfotainment" SG_ 2153914368 EUSS_TrEgUgScrMnScVal 1;
BA_ "SignalType" SG_ 2153914368 EUSS_TrEgUgScrMnScVal "SNM";
BA_ "PacketOrder" SG_ 2153914368 EUSS_TrEgUgScrMnScVal 7;
BA_ "SignalLongName" SG_ 2153914368 EUSS_TrEgUgScrMnScVal "Energy Usage Score Scaling : Terrain Energy Usage Score Minimum Scale Value";
BA_ "VNSigAllNodes" SG_ 2153914368 EUSS_TrEgUgScrMnScVal 1;
BA_ "GenSigDeltaValue" SG_ 2153914368 EUSS_TcEgUgScrMxScVal 1;
BA_ "GenSigSendType" SG_ 2153914368 EUSS_TcEgUgScrMxScVal 12;
BA_ "GenSigSendOnInit" SG_ 2153914368 EUSS_TcEgUgScrMxScVal 1;
BA_ "VNSigInfotainment" SG_ 2153914368 EUSS_TcEgUgScrMxScVal 1;
BA_ "SignalType" SG_ 2153914368 EUSS_TcEgUgScrMxScVal "SNM";
BA_ "PacketOrder" SG_ 2153914368 EUSS_TcEgUgScrMxScVal 6;
BA_ "SignalLongName" SG_ 2153914368 EUSS_TcEgUgScrMxScVal "Energy Usage Score Scaling : Technique Energy Usage Score Maximum Scale Value";
BA_ "VNSigAllNodes" SG_ 2153914368 EUSS_TcEgUgScrMxScVal 1;
BA_ "GenSigDeltaValue" SG_ 2153914368 EUSS_TcEgUgScrMnScVal 1;
BA_ "GenSigSendType" SG_ 2153914368 EUSS_TcEgUgScrMnScVal 12;
BA_ "GenSigSendOnInit" SG_ 2153914368 EUSS_TcEgUgScrMnScVal 1;
BA_ "VNSigInfotainment" SG_ 2153914368 EUSS_TcEgUgScrMnScVal 1;
BA_ "SignalType" SG_ 2153914368 EUSS_TcEgUgScrMnScVal "SNM";
BA_ "PacketOrder" SG_ 2153914368 EUSS_TcEgUgScrMnScVal 5;
BA_ "SignalLongName" SG_ 2153914368 EUSS_TcEgUgScrMnScVal "Energy Usage Score Scaling : Technique Energy Usage Score Minimum Scale Value";
BA_ "VNSigAllNodes" SG_ 2153914368 EUSS_TcEgUgScrMnScVal 1;
BA_ "GenSigDeltaValue" SG_ 2153914368 EUSS_ITEgUgScrMxScVal 1;
BA_ "GenSigSendType" SG_ 2153914368 EUSS_ITEgUgScrMxScVal 12;
BA_ "GenSigSendOnInit" SG_ 2153914368 EUSS_ITEgUgScrMxScVal 1;
BA_ "VNSigInfotainment" SG_ 2153914368 EUSS_ITEgUgScrMxScVal 1;
BA_ "SignalType" SG_ 2153914368 EUSS_ITEgUgScrMxScVal "SNM";
BA_ "PacketOrder" SG_ 2153914368 EUSS_ITEgUgScrMxScVal 4;
BA_ "SignalLongName" SG_ 2153914368 EUSS_ITEgUgScrMxScVal "Energy Usage Score Scaling : Inside Temp Energy Usage Score Max Scale Value";
BA_ "VNSigAllNodes" SG_ 2153914368 EUSS_ITEgUgScrMxScVal 1;
BA_ "GenSigDeltaValue" SG_ 2153914368 EUSS_ITEgUgScrMnScVal 1;
BA_ "GenSigSendType" SG_ 2153914368 EUSS_ITEgUgScrMnScVal 12;
BA_ "GenSigSendOnInit" SG_ 2153914368 EUSS_ITEgUgScrMnScVal 1;
BA_ "VNSigInfotainment" SG_ 2153914368 EUSS_ITEgUgScrMnScVal 1;
BA_ "SignalType" SG_ 2153914368 EUSS_ITEgUgScrMnScVal "SNM";
BA_ "PacketOrder" SG_ 2153914368 EUSS_ITEgUgScrMnScVal 3;
BA_ "SignalLongName" SG_ 2153914368 EUSS_ITEgUgScrMnScVal "Energy Usage Score Scaling : Inside Temp Energy Usage Score Min Scale Value";
BA_ "VNSigAllNodes" SG_ 2153914368 EUSS_ITEgUgScrMnScVal 1;
BA_ "GenSigDeltaValue" SG_ 2153914368 EUSS_OTEgUgScrMxScVal 1;
BA_ "GenSigSendType" SG_ 2153914368 EUSS_OTEgUgScrMxScVal 12;
BA_ "GenSigSendOnInit" SG_ 2153914368 EUSS_OTEgUgScrMxScVal 1;
BA_ "VNSigInfotainment" SG_ 2153914368 EUSS_OTEgUgScrMxScVal 1;
BA_ "SignalType" SG_ 2153914368 EUSS_OTEgUgScrMxScVal "SNM";
BA_ "PacketOrder" SG_ 2153914368 EUSS_OTEgUgScrMxScVal 2;
BA_ "SignalLongName" SG_ 2153914368 EUSS_OTEgUgScrMxScVal "Energy Usage Score Scaling : Outside Temp Energy Usage Score Max Scale Value";
BA_ "VNSigAllNodes" SG_ 2153914368 EUSS_OTEgUgScrMxScVal 1;
BA_ "GenSigDeltaValue" SG_ 2153914368 EUSS_OTEgUgScrMnScVal 1;
BA_ "GenSigSendType" SG_ 2153914368 EUSS_OTEgUgScrMnScVal 12;
BA_ "GenSigSendOnInit" SG_ 2153914368 EUSS_OTEgUgScrMnScVal 1;
BA_ "VNSigInfotainment" SG_ 2153914368 EUSS_OTEgUgScrMnScVal 1;
BA_ "SignalType" SG_ 2153914368 EUSS_OTEgUgScrMnScVal "SNM";
BA_ "PacketOrder" SG_ 2153914368 EUSS_OTEgUgScrMnScVal 1;
BA_ "SignalLongName" SG_ 2153914368 EUSS_OTEgUgScrMnScVal "Energy Usage Score Scaling : Outside Temp Energy Usage Score Min Scale Value";
BA_ "VNSigAllNodes" SG_ 2153914368 EUSS_OTEgUgScrMnScVal 1;
BA_ "GenSigSendType" SG_ 2150629376 CVSysFlrIO 10;
BA_ "SignalType" SG_ 2150629376 CVSysFlrIO "BLN";
BA_ "SignalLongName" SG_ 2150629376 CVSysFlrIO "ControVento System Failure Indication On";
BA_ "VNSigAllNodes" SG_ 2150629376 CVSysFlrIO 1;
BA_ "GenSigSendType" SG_ 2153390080 RrClosOpenSwAct_2D1V 10;
BA_ "SignalType" SG_ 2153390080 RrClosOpenSwAct_2D1V "ENM";
BA_ "SignalLongName" SG_ 2153390080 RrClosOpenSwAct_2D1V "Rear Closure Open Switch Active 2D1 Validity";
BA_ "VNSigAllNodes" SG_ 2153390080 RrClosOpenSwAct_2D1V 1;
BA_ "GenSigSendType" SG_ 2153390080 RrClosOpenSwAct_2D1 10;
BA_ "GenSigSendOnInit" SG_ 2153390080 RrClosOpenSwAct_2D1 2;
BA_ "SignalType" SG_ 2153390080 RrClosOpenSwAct_2D1 "BLN";
BA_ "SignalLongName" SG_ 2153390080 RrClosOpenSwAct_2D1 "Rear Closure Open Switch Active 2D1";
BA_ "VNSigAllNodes" SG_ 2153390080 RrClosOpenSwAct_2D1 1;
BA_ "GenSigSendType" SG_ 2151415808 FrPedDetCsStAvl 10;
BA_ "GenSigSendOnInit" SG_ 2151415808 FrPedDetCsStAvl 2;
BA_ "SignalType" SG_ 2151415808 FrPedDetCsStAvl "BLN";
BA_ "SignalLongName" SG_ 2151415808 FrPedDetCsStAvl "Front Pedestrian Detection Customization Setting Available";
BA_ "VNSigAllNodes" SG_ 2151415808 FrPedDetCsStAvl 1;
BA_ "GenSigSendType" SG_ 2151415808 FrPedDetCsCrStVal 10;
BA_ "GenSigSendOnInit" SG_ 2151415808 FrPedDetCsCrStVal 2;
BA_ "SignalType" SG_ 2151415808 FrPedDetCsCrStVal "ENM";
BA_ "SignalLongName" SG_ 2151415808 FrPedDetCsCrStVal "Front Pedestrian Detection Customization Current Setting Value";
BA_ "VNSigAllNodes" SG_ 2151415808 FrPedDetCsCrStVal 1;
BA_ "GenSigDeltaValue" SG_ 2151415808 RgtLnChgThrtHptStRqSN 1;
BA_ "GenSigSendType" SG_ 2151415808 RgtLnChgThrtHptStRqSN 12;
BA_ "SignalType" SG_ 2151415808 RgtLnChgThrtHptStRqSN "UNM";
BA_ "SignalLongName" SG_ 2151415808 RgtLnChgThrtHptStRqSN "Right Lane Change Threat Haptic Seat Request Sequence Number";
BA_ "VNSigAllNodes" SG_ 2151415808 RgtLnChgThrtHptStRqSN 1;
BA_ "GenSigDeltaValue" SG_ 2151415808 RgtLnChgThrtHptStRq 1;
BA_ "GenSigSendType" SG_ 2151415808 RgtLnChgThrtHptStRq 12;
BA_ "SignalType" SG_ 2151415808 RgtLnChgThrtHptStRq "UNM";
BA_ "SignalLongName" SG_ 2151415808 RgtLnChgThrtHptStRq "Right Lane Change Threat Haptic Seat Request";
BA_ "VNSigAllNodes" SG_ 2151415808 RgtLnChgThrtHptStRq 1;
BA_ "GenSigDeltaValue" SG_ 2151415808 LftLnChgThrtHptStRqSN 1;
BA_ "GenSigSendType" SG_ 2151415808 LftLnChgThrtHptStRqSN 12;
BA_ "SignalType" SG_ 2151415808 LftLnChgThrtHptStRqSN "UNM";
BA_ "SignalLongName" SG_ 2151415808 LftLnChgThrtHptStRqSN "Left Lane Change Threat Haptic Seat Request Sequence Number";
BA_ "VNSigAllNodes" SG_ 2151415808 LftLnChgThrtHptStRqSN 1;
BA_ "GenSigDeltaValue" SG_ 2151415808 LftLnChgThrtHptStRq 1;
BA_ "GenSigSendType" SG_ 2151415808 LftLnChgThrtHptStRq 12;
BA_ "SignalType" SG_ 2151415808 LftLnChgThrtHptStRq "UNM";
BA_ "SignalLongName" SG_ 2151415808 LftLnChgThrtHptStRq "Left Lane Change Threat Haptic Seat Request";
BA_ "VNSigAllNodes" SG_ 2151415808 LftLnChgThrtHptStRq 1;
BA_ "GenSigDeltaValue" SG_ 2151415808 LDWRghtHptcStRqSN 1;
BA_ "GenSigSendType" SG_ 2151415808 LDWRghtHptcStRqSN 12;
BA_ "SignalType" SG_ 2151415808 LDWRghtHptcStRqSN "UNM";
BA_ "SignalLongName" SG_ 2151415808 LDWRghtHptcStRqSN "Lane Departure Warning Right Haptic Seat Request Sequence Number";
BA_ "VNSigAllNodes" SG_ 2151415808 LDWRghtHptcStRqSN 1;
BA_ "GenSigDeltaValue" SG_ 2151415808 LDWRghtHptcStRq 1;
BA_ "GenSigSendType" SG_ 2151415808 LDWRghtHptcStRq 12;
BA_ "SignalType" SG_ 2151415808 LDWRghtHptcStRq "UNM";
BA_ "SignalLongName" SG_ 2151415808 LDWRghtHptcStRq "Lane Departure Warning Right Haptic Seat Request";
BA_ "VNSigAllNodes" SG_ 2151415808 LDWRghtHptcStRq 1;
BA_ "GenSigDeltaValue" SG_ 2151415808 LDWLftHptcStRqSN 1;
BA_ "GenSigSendType" SG_ 2151415808 LDWLftHptcStRqSN 12;
BA_ "SignalType" SG_ 2151415808 LDWLftHptcStRqSN "UNM";
BA_ "SignalLongName" SG_ 2151415808 LDWLftHptcStRqSN "Lane Departure Warning Left Haptic Seat Request Sequence Number";
BA_ "VNSigAllNodes" SG_ 2151415808 LDWLftHptcStRqSN 1;
BA_ "GenSigDeltaValue" SG_ 2151415808 LDWLftHptcStRq 1;
BA_ "GenSigSendType" SG_ 2151415808 LDWLftHptcStRq 12;
BA_ "SignalType" SG_ 2151415808 LDWLftHptcStRq "UNM";
BA_ "SignalLongName" SG_ 2151415808 LDWLftHptcStRq "Lane Departure Warning Left Haptic Seat Request";
BA_ "VNSigAllNodes" SG_ 2151415808 LDWLftHptcStRq 1;
BA_ "GenSigSendType" SG_ 2150080512 LBCVLS_VehGPSLctV 10;
BA_ "GenSigSendOnInit" SG_ 2150080512 LBCVLS_VehGPSLctV 1;
BA_ "PacketOrder" SG_ 2150080512 LBCVLS_VehGPSLctV 1;
BA_ "VNSigInfotainment" SG_ 2150080512 LBCVLS_VehGPSLctV 1;
BA_ "SignalType" SG_ 2150080512 LBCVLS_VehGPSLctV "ENM";
BA_ "SignalLongName" SG_ 2150080512 LBCVLS_VehGPSLctV "Location Based Charging Vehicle Location Status : Vehicle GPS Location Validity";
BA_ "VNSigAllNodes" SG_ 2150080512 LBCVLS_VehGPSLctV 1;
BA_ "GenSigSendType" SG_ 2150080512 LBCVLS_VehGPSLct 10;
BA_ "GenSigSendOnInit" SG_ 2150080512 LBCVLS_VehGPSLct 1;
BA_ "PacketOrder" SG_ 2150080512 LBCVLS_VehGPSLct 2;
BA_ "VNSigInfotainment" SG_ 2150080512 LBCVLS_VehGPSLct 1;
BA_ "SignalType" SG_ 2150080512 LBCVLS_VehGPSLct "ENM";
BA_ "SignalLongName" SG_ 2150080512 LBCVLS_VehGPSLct "Location Based Charging Vehicle Location Status : Vehicle GPS Location";
BA_ "VNSigAllNodes" SG_ 2150080512 LBCVLS_VehGPSLct 1;
BA_ "GenSigSendType" SG_ 2150080512 EngAstHtDfrdHtMdAct 10;
BA_ "SignalType" SG_ 2150080512 EngAstHtDfrdHtMdAct "BLN";
BA_ "SignalLongName" SG_ 2150080512 EngAstHtDfrdHtMdAct "Engine Assisted Heating Deferred Heat Mode Active";
BA_ "VNSigAllNodes" SG_ 2150080512 EngAstHtDfrdHtMdAct 1;
BA_ "GenSigSendType" SG_ 2150080512 LBCPSS_PosUpdtStat 10;
BA_ "GenSigSendOnInit" SG_ 2150080512 LBCPSS_PosUpdtStat 1;
BA_ "VNSigInfotainment" SG_ 2150080512 LBCPSS_PosUpdtStat 1;
BA_ "SignalType" SG_ 2150080512 LBCPSS_PosUpdtStat "ENM";
BA_ "PacketOrder" SG_ 2150080512 LBCPSS_PosUpdtStat 1;
BA_ "SignalLongName" SG_ 2150080512 LBCPSS_PosUpdtStat "Location Based Charging Position Storage Status : Position Update Status";
BA_ "VNSigAllNodes" SG_ 2150080512 LBCPSS_PosUpdtStat 1;
BA_ "GenSigSendType" SG_ 2150080512 LBCPSS_PosUpdtLct 10;
BA_ "GenSigSendOnInit" SG_ 2150080512 LBCPSS_PosUpdtLct 1;
BA_ "VNSigInfotainment" SG_ 2150080512 LBCPSS_PosUpdtLct 1;
BA_ "SignalType" SG_ 2150080512 LBCPSS_PosUpdtLct "ENM";
BA_ "PacketOrder" SG_ 2150080512 LBCPSS_PosUpdtLct 2;
BA_ "SignalLongName" SG_ 2150080512 LBCPSS_PosUpdtLct "Location Based Charging Position Storage Status : Position Update Location";
BA_ "VNSigAllNodes" SG_ 2150080512 LBCPSS_PosUpdtLct 1;
BA_ "GenSigSendType" SG_ 2150080512 LBCCsStAvl 10;
BA_ "GenSigSendOnInit" SG_ 2150080512 LBCCsStAvl 1;
BA_ "VNSigInfotainment" SG_ 2150080512 LBCCsStAvl 1;
BA_ "SignalType" SG_ 2150080512 LBCCsStAvl "BLN";
BA_ "SignalLongName" SG_ 2150080512 LBCCsStAvl "Location Based Charging Customization Setting Available";
BA_ "VNSigAllNodes" SG_ 2150080512 LBCCsStAvl 1;
BA_ "GenSigSendType" SG_ 2150080512 LBCCsCrStVal 10;
BA_ "GenSigSendOnInit" SG_ 2150080512 LBCCsCrStVal 1;
BA_ "VNSigInfotainment" SG_ 2150080512 LBCCsCrStVal 1;
BA_ "SignalType" SG_ 2150080512 LBCCsCrStVal "ENM";
BA_ "SignalLongName" SG_ 2150080512 LBCCsCrStVal "Location Based Charging Customization Current Setting Value";
BA_ "VNSigAllNodes" SG_ 2150080512 LBCCsCrStVal 1;
BA_ "GenSigSendType" SG_ 2150080512 LBCCF_Lct4PosStrdIO 10;
BA_ "GenSigSendOnInit" SG_ 2150080512 LBCCF_Lct4PosStrdIO 1;
BA_ "VNSigInfotainment" SG_ 2150080512 LBCCF_Lct4PosStrdIO 1;
BA_ "SignalType" SG_ 2150080512 LBCCF_Lct4PosStrdIO "BLN";
BA_ "PacketOrder" SG_ 2150080512 LBCCF_Lct4PosStrdIO 4;
BA_ "SignalLongName" SG_ 2150080512 LBCCF_Lct4PosStrdIO "Location Based Charging Customer Feedback : Location 4 Position Stored Indication On";
BA_ "VNSigAllNodes" SG_ 2150080512 LBCCF_Lct4PosStrdIO 1;
BA_ "GenSigSendType" SG_ 2150080512 LBCCF_Lct3PosStrdIO 10;
BA_ "GenSigSendOnInit" SG_ 2150080512 LBCCF_Lct3PosStrdIO 1;
BA_ "VNSigInfotainment" SG_ 2150080512 LBCCF_Lct3PosStrdIO 1;
BA_ "SignalType" SG_ 2150080512 LBCCF_Lct3PosStrdIO "BLN";
BA_ "PacketOrder" SG_ 2150080512 LBCCF_Lct3PosStrdIO 3;
BA_ "SignalLongName" SG_ 2150080512 LBCCF_Lct3PosStrdIO "Location Based Charging Customer Feedback : Location 3 Position Stored Indication On";
BA_ "VNSigAllNodes" SG_ 2150080512 LBCCF_Lct3PosStrdIO 1;
BA_ "GenSigSendType" SG_ 2150080512 LBCCF_Lct2PosStrdIO 10;
BA_ "GenSigSendOnInit" SG_ 2150080512 LBCCF_Lct2PosStrdIO 1;
BA_ "VNSigInfotainment" SG_ 2150080512 LBCCF_Lct2PosStrdIO 1;
BA_ "SignalType" SG_ 2150080512 LBCCF_Lct2PosStrdIO "BLN";
BA_ "PacketOrder" SG_ 2150080512 LBCCF_Lct2PosStrdIO 2;
BA_ "SignalLongName" SG_ 2150080512 LBCCF_Lct2PosStrdIO "Location Based Charging Customer Feedback : Location 2 Position Stored Indication On";
BA_ "VNSigAllNodes" SG_ 2150080512 LBCCF_Lct2PosStrdIO 1;
BA_ "GenSigSendType" SG_ 2150080512 LBCCF_Lct1PosStrdIO 10;
BA_ "GenSigSendOnInit" SG_ 2150080512 LBCCF_Lct1PosStrdIO 1;
BA_ "VNSigInfotainment" SG_ 2150080512 LBCCF_Lct1PosStrdIO 1;
BA_ "SignalType" SG_ 2150080512 LBCCF_Lct1PosStrdIO "BLN";
BA_ "PacketOrder" SG_ 2150080512 LBCCF_Lct1PosStrdIO 1;
BA_ "SignalLongName" SG_ 2150080512 LBCCF_Lct1PosStrdIO "Location Based Charging Customer Feedback : Location 1 Position Stored Indication On";
BA_ "VNSigAllNodes" SG_ 2150080512 LBCCF_Lct1PosStrdIO 1;
BA_ "GenSigSendType" SG_ 2150080512 LBCCDRR_PosNumbr 10;
BA_ "VNSigInfotainment" SG_ 2150080512 LBCCDRR_PosNumbr 1;
BA_ "SignalType" SG_ 2150080512 LBCCDRR_PosNumbr "ENM";
BA_ "PacketOrder" SG_ 2150080512 LBCCDRR_PosNumbr 2;
BA_ "SignalLongName" SG_ 2150080512 LBCCDRR_PosNumbr "Location Based Charging Customer Data Reset Response : Position Number";
BA_ "VNSigAllNodes" SG_ 2150080512 LBCCDRR_PosNumbr 1;
BA_ "GenSigSendType" SG_ 2150080512 LBCCDRR_ClrStrdPosResp 10;
BA_ "VNSigInfotainment" SG_ 2150080512 LBCCDRR_ClrStrdPosResp 1;
BA_ "SignalType" SG_ 2150080512 LBCCDRR_ClrStrdPosResp "ENM";
BA_ "PacketOrder" SG_ 2150080512 LBCCDRR_ClrStrdPosResp 1;
BA_ "SignalLongName" SG_ 2150080512 LBCCDRR_ClrStrdPosResp "Location Based Charging Customer Data Reset Response : Clear Stored Position response";
BA_ "VNSigAllNodes" SG_ 2150080512 LBCCDRR_ClrStrdPosResp 1;
BA_ "GenSigSendType" SG_ 2150080512 LBCChrgLvlPrfExpIO 10;
BA_ "GenSigSendOnInit" SG_ 2150080512 LBCChrgLvlPrfExpIO 1;
BA_ "VNSigInfotainment" SG_ 2150080512 LBCChrgLvlPrfExpIO 1;
BA_ "SignalType" SG_ 2150080512 LBCChrgLvlPrfExpIO "BLN";
BA_ "SignalLongName" SG_ 2150080512 LBCChrgLvlPrfExpIO "Location Based Charging Charge Level Preference Expiration Indication On";
BA_ "VNSigAllNodes" SG_ 2150080512 LBCChrgLvlPrfExpIO 1;
BA_ "GenSigSendType" SG_ 2150080512 AuxClntHtrVlvStat 10;
BA_ "GenSigSendOnInit" SG_ 2150080512 AuxClntHtrVlvStat 1;
BA_ "SignalType" SG_ 2150080512 AuxClntHtrVlvStat "ENM";
BA_ "SignalLongName" SG_ 2150080512 AuxClntHtrVlvStat "Auxiliary Coolant Heater Valve Status";
BA_ "VNSigAllNodes" SG_ 2150080512 AuxClntHtrVlvStat 1;
BA_ "GenSigDeltaValue" SG_ 2150080512 ChrgCyclOvrlEngyEcnEq 1;
BA_ "GenSigSendType" SG_ 2150080512 ChrgCyclOvrlEngyEcnEq 12;
BA_ "GenSigSendOnInit" SG_ 2150080512 ChrgCyclOvrlEngyEcnEq 1;
BA_ "VNSigInfotainment" SG_ 2150080512 ChrgCyclOvrlEngyEcnEq 1;
BA_ "SignalType" SG_ 2150080512 ChrgCyclOvrlEngyEcnEq "UNM";
BA_ "SignalLongName" SG_ 2150080512 ChrgCyclOvrlEngyEcnEq "Charge Cycle Overall Energy Economy Equivalent";
BA_ "VNSigAllNodes" SG_ 2150080512 ChrgCyclOvrlEngyEcnEq 1;
BA_ "GenSigDeltaValue" SG_ 2150080512 ChrgCyclElecEngyEcnEq 1;
BA_ "GenSigSendType" SG_ 2150080512 ChrgCyclElecEngyEcnEq 12;
BA_ "GenSigSendOnInit" SG_ 2150080512 ChrgCyclElecEngyEcnEq 1;
BA_ "VNSigInfotainment" SG_ 2150080512 ChrgCyclElecEngyEcnEq 1;
BA_ "SignalType" SG_ 2150080512 ChrgCyclElecEngyEcnEq "UNM";
BA_ "SignalLongName" SG_ 2150080512 ChrgCyclElecEngyEcnEq "Charge Cycle Electrical Energy Economy Equivalent";
BA_ "VNSigAllNodes" SG_ 2150080512 ChrgCyclElecEngyEcnEq 1;
BA_ "GenSigSendType" SG_ 2153988096 PwrElecCoolLpTempM 10;
BA_ "GenSigSendOnInit" SG_ 2153988096 PwrElecCoolLpTempM 1;
BA_ "SignalType" SG_ 2153988096 PwrElecCoolLpTempM "ENM";
BA_ "SignalLongName" SG_ 2153988096 PwrElecCoolLpTempM "Power Electronics Cooling Loop Temperature Mask";
BA_ "VNSigAllNodes" SG_ 2153988096 PwrElecCoolLpTempM 1;
BA_ "GenSigSendType" SG_ 2153988096 PwrElecCoolLpTempV 10;
BA_ "GenSigSendOnInit" SG_ 2153988096 PwrElecCoolLpTempV 1;
BA_ "SignalType" SG_ 2153988096 PwrElecCoolLpTempV "ENM";
BA_ "SignalLongName" SG_ 2153988096 PwrElecCoolLpTempV "Power Electronics Cooling Loop Temperature Validity";
BA_ "VNSigAllNodes" SG_ 2153988096 PwrElecCoolLpTempV 1;
BA_ "GenSigDeltaValue" SG_ 2153988096 PwrElecCoolLpTemp 1;
BA_ "GenSigSendType" SG_ 2153988096 PwrElecCoolLpTemp 12;
BA_ "GenSigSendOnInit" SG_ 2153988096 PwrElecCoolLpTemp 1;
BA_ "SignalType" SG_ 2153988096 PwrElecCoolLpTemp "UNM";
BA_ "SignalLongName" SG_ 2153988096 PwrElecCoolLpTemp "Power Electronics Cooling Loop Temperature";
BA_ "VNSigAllNodes" SG_ 2153988096 PwrElecCoolLpTemp 1;
BA_ "GenSigDeltaValue" SG_ 2153988096 EUS_TtEngyUsgScrAvVal 1;
BA_ "GenSigSendType" SG_ 2153988096 EUS_TtEngyUsgScrAvVal 12;
BA_ "GenSigSendOnInit" SG_ 2153988096 EUS_TtEngyUsgScrAvVal 1;
BA_ "VNSigInfotainment" SG_ 2153988096 EUS_TtEngyUsgScrAvVal 1;
BA_ "SignalType" SG_ 2153988096 EUS_TtEngyUsgScrAvVal "SNM";
BA_ "PacketOrder" SG_ 2153988096 EUS_TtEngyUsgScrAvVal 5;
BA_ "SignalLongName" SG_ 2153988096 EUS_TtEngyUsgScrAvVal "Energy Usage Score : Total Energy Usage Score Value";
BA_ "VNSigAllNodes" SG_ 2153988096 EUS_TtEngyUsgScrAvVal 1;
BA_ "GenSigDeltaValue" SG_ 2153988096 EUS_ITEngyUsgScrAvVal 1;
BA_ "GenSigSendType" SG_ 2153988096 EUS_ITEngyUsgScrAvVal 12;
BA_ "GenSigSendOnInit" SG_ 2153988096 EUS_ITEngyUsgScrAvVal 1;
BA_ "VNSigInfotainment" SG_ 2153988096 EUS_ITEngyUsgScrAvVal 1;
BA_ "SignalType" SG_ 2153988096 EUS_ITEngyUsgScrAvVal "SNM";
BA_ "PacketOrder" SG_ 2153988096 EUS_ITEngyUsgScrAvVal 4;
BA_ "SignalLongName" SG_ 2153988096 EUS_ITEngyUsgScrAvVal "Energy Usage Score : Inside Temperature Energy Usage Score Average Value";
BA_ "VNSigAllNodes" SG_ 2153988096 EUS_ITEngyUsgScrAvVal 1;
BA_ "GenSigDeltaValue" SG_ 2153988096 EUS_OTEngyUsgScrAvVal 1;
BA_ "GenSigSendType" SG_ 2153988096 EUS_OTEngyUsgScrAvVal 12;
BA_ "GenSigSendOnInit" SG_ 2153988096 EUS_OTEngyUsgScrAvVal 1;
BA_ "VNSigInfotainment" SG_ 2153988096 EUS_OTEngyUsgScrAvVal 1;
BA_ "SignalType" SG_ 2153988096 EUS_OTEngyUsgScrAvVal "SNM";
BA_ "PacketOrder" SG_ 2153988096 EUS_OTEngyUsgScrAvVal 3;
BA_ "SignalLongName" SG_ 2153988096 EUS_OTEngyUsgScrAvVal "Energy Usage Score : Outside Temperature Energy Usage Score Average Value";
BA_ "VNSigAllNodes" SG_ 2153988096 EUS_OTEngyUsgScrAvVal 1;
BA_ "GenSigDeltaValue" SG_ 2153988096 EUS_TrEngyUsgScrAvVal 1;
BA_ "GenSigSendType" SG_ 2153988096 EUS_TrEngyUsgScrAvVal 12;
BA_ "GenSigSendOnInit" SG_ 2153988096 EUS_TrEngyUsgScrAvVal 1;
BA_ "VNSigInfotainment" SG_ 2153988096 EUS_TrEngyUsgScrAvVal 1;
BA_ "SignalType" SG_ 2153988096 EUS_TrEngyUsgScrAvVal "SNM";
BA_ "PacketOrder" SG_ 2153988096 EUS_TrEngyUsgScrAvVal 2;
BA_ "SignalLongName" SG_ 2153988096 EUS_TrEngyUsgScrAvVal "Energy Usage Score : Terrain Energy Usage Score Average Value";
BA_ "VNSigAllNodes" SG_ 2153988096 EUS_TrEngyUsgScrAvVal 1;
BA_ "GenSigDeltaValue" SG_ 2153988096 EUS_TcEngyUsgScrAvVal 1;
BA_ "GenSigSendType" SG_ 2153988096 EUS_TcEngyUsgScrAvVal 12;
BA_ "GenSigSendOnInit" SG_ 2153988096 EUS_TcEngyUsgScrAvVal 1;
BA_ "VNSigInfotainment" SG_ 2153988096 EUS_TcEngyUsgScrAvVal 1;
BA_ "SignalType" SG_ 2153988096 EUS_TcEngyUsgScrAvVal "SNM";
BA_ "PacketOrder" SG_ 2153988096 EUS_TcEngyUsgScrAvVal 1;
BA_ "SignalLongName" SG_ 2153988096 EUS_TcEngyUsgScrAvVal "Energy Usage Score : Technique Energy Usage Score Average Value";
BA_ "VNSigAllNodes" SG_ 2153988096 EUS_TcEngyUsgScrAvVal 1;
BA_ "SignalType" SG_ 2151915520 ESPTrnVehOffFrPrkIO "BLN";
BA_ "SignalLongName" SG_ 2151915520 ESPTrnVehOffFrPrkIO "Electronic Shift Primary Turn Vehicle Off For Park Indication On";
BA_ "VNSigAllNodes" SG_ 2151915520 ESPTrnVehOffFrPrkIO 1;
BA_ "SignalType" SG_ 2151915520 ESPTrnsCtlrMalfIO "BLN";
BA_ "SignalLongName" SG_ 2151915520 ESPTrnsCtlrMalfIO "Electronic Shift Primary Transmission Controller Malfunction Indication On";
BA_ "VNSigAllNodes" SG_ 2151915520 ESPTrnsCtlrMalfIO 1;
BA_ "SignalType" SG_ 2151915520 ESPShfToDrvTryAgnIO "BLN";
BA_ "SignalLongName" SG_ 2151915520 ESPShfToDrvTryAgnIO "Electronic Shift Primary Shift To Drive Try Again Indication On";
BA_ "VNSigAllNodes" SG_ 2151915520 ESPShfToDrvTryAgnIO 1;
BA_ "SignalType" SG_ 2151915520 ElcShfPriTwoGrsSlInRq "ENM";
BA_ "SignalLongName" SG_ 2151915520 ElcShfPriTwoGrsSlInRq "Electronic Shift Primary Two Gears Selected Indication Request";
BA_ "VNSigAllNodes" SG_ 2151915520 ElcShfPriTwoGrsSlInRq 1;
BA_ "GenSigSendType" SG_ 2151915520 ESPRedSpdReqShftIO 10;
BA_ "SignalType" SG_ 2151915520 ESPRedSpdReqShftIO "BLN";
BA_ "SignalLongName" SG_ 2151915520 ESPRedSpdReqShftIO "Electronic Shift Primary Reduce Speed for Requested Shift Indication On";
BA_ "VNSigAllNodes" SG_ 2151915520 ESPRedSpdReqShftIO 1;
BA_ "SignalType" SG_ 2151915520 DrvEffInd "SNM";
BA_ "SignalLongName" SG_ 2151915520 DrvEffInd "Drive Efficiency Indication";
BA_ "VNSigAllNodes" SG_ 2151915520 DrvEffInd 1;
BA_ "SignalType" SG_ 2151915520 EngIntkArBstPrExtRngV "ENM";
BA_ "SignalLongName" SG_ 2151915520 EngIntkArBstPrExtRngV "Engine Intake Air Boost Pressure Extended Range Validity";
BA_ "VNSigAllNodes" SG_ 2151915520 EngIntkArBstPrExtRngV 1;
BA_ "SignalType" SG_ 2151915520 EngIntkArBstPrExtRng "UNM";
BA_ "SignalLongName" SG_ 2151915520 EngIntkArBstPrExtRng "Engine Intake Air Boost Pressure Extended Range";
BA_ "VNSigAllNodes" SG_ 2151915520 EngIntkArBstPrExtRng 1;
BA_ "SignalType" SG_ 2151915520 ElecShfRngDispRCExtd "UNM";
BA_ "SignalLongName" SG_ 2151915520 ElecShfRngDispRCExtd "Electronic Shift Range Display Rolling Count Extended";
BA_ "VNSigAllNodes" SG_ 2151915520 ElecShfRngDispRCExtd 1;
BA_ "SignalType" SG_ 2151915520 ElecShfRngDisp "ENM";
BA_ "SignalLongName" SG_ 2151915520 ElecShfRngDisp "Electronic Shift Range Display";
BA_ "VNSigAllNodes" SG_ 2151915520 ElecShfRngDisp 1;
BA_ "SignalType" SG_ 2151915520 ESPTransMalfIO "BLN";
BA_ "SignalLongName" SG_ 2151915520 ESPTransMalfIO "Electronic Shift Primary Transmission Malfunction Indication On";
BA_ "VNSigAllNodes" SG_ 2151915520 ESPTransMalfIO 1;
BA_ "SignalType" SG_ 2151915520 ESPRngInvldReqIO "BLN";
BA_ "SignalLongName" SG_ 2151915520 ESPRngInvldReqIO "Electronic Shift Primary Range Invalid Request Indication On";
BA_ "VNSigAllNodes" SG_ 2151915520 ESPRngInvldReqIO 1;
BA_ "SignalType" SG_ 2151915520 ESPPrkInvldReqIO "BLN";
BA_ "SignalLongName" SG_ 2151915520 ESPPrkInvldReqIO "Electronic Shift Primary Park Invalid Request Indication On";
BA_ "VNSigAllNodes" SG_ 2151915520 ESPPrkInvldReqIO 1;
BA_ "SignalType" SG_ 2151915520 ESPHldShfLvrToEngRgIO "BLN";
BA_ "SignalLongName" SG_ 2151915520 ESPHldShfLvrToEngRgIO "Electronic Shift Primary Hold Shift Lever to Engage Range Indication On";
BA_ "VNSigAllNodes" SG_ 2151915520 ESPHldShfLvrToEngRgIO 1;
BA_ "SignalType" SG_ 2151915520 ESPDrvrPrkIlkSftAtdIO "BLN";
BA_ "SignalLongName" SG_ 2151915520 ESPDrvrPrkIlkSftAtdIO "Electronic Shift Primary Driver Park Interlock Shift Attempted Indication On";
BA_ "VNSigAllNodes" SG_ 2151915520 ESPDrvrPrkIlkSftAtdIO 1;
BA_ "SignalType" SG_ 2151915520 ESPDrvrIlkShfAtdIO "BLN";
BA_ "SignalLongName" SG_ 2151915520 ESPDrvrIlkShfAtdIO "Electronic Shift Primary Driver Interlock Shift Attempted Indication On";
BA_ "VNSigAllNodes" SG_ 2151915520 ESPDrvrIlkShfAtdIO 1;
BA_ "SignalType" SG_ 2151915520 AHAct "BLN";
BA_ "SignalLongName" SG_ 2151915520 AHAct "Auto Hold Active";
BA_ "VNSigAllNodes" SG_ 2151915520 AHAct 1;
BA_ "SignalType" SG_ 2151915520 AHEnbld "BLN";
BA_ "SignalLongName" SG_ 2151915520 AHEnbld "Auto Hold Enabled";
BA_ "VNSigAllNodes" SG_ 2151915520 AHEnbld 1;
BA_ "SignalType" SG_ 2151915520 ShfToPrkBfExtngIO "BLN";
BA_ "SignalLongName" SG_ 2151915520 ShfToPrkBfExtngIO "Shift To Park Before Exiting Indication On";
BA_ "VNSigAllNodes" SG_ 2151915520 ShfToPrkBfExtngIO 1;
BA_ "SignalType" SG_ 2151915520 AHServcIO "BLN";
BA_ "SignalLongName" SG_ 2151915520 AHServcIO "Auto Hold Service Indication On";
BA_ "VNSigAllNodes" SG_ 2151915520 AHServcIO 1;
BA_ "SignalType" SG_ 2151915520 AHAppBrkPedlIO "BLN";
BA_ "SignalLongName" SG_ 2151915520 AHAppBrkPedlIO "Auto Hold Apply Brake Pedal Indication On";
BA_ "VNSigAllNodes" SG_ 2151915520 AHAppBrkPedlIO 1;
BA_ "SignalType" SG_ 2151915520 AHDisbldStbltIO "BLN";
BA_ "SignalLongName" SG_ 2151915520 AHDisbldStbltIO "Auto Hold Disabled Seatbelt Indication On";
BA_ "VNSigAllNodes" SG_ 2151915520 AHDisbldStbltIO 1;
BA_ "SignalType" SG_ 2151915520 AHDisbldDrOpnIO "BLN";
BA_ "SignalLongName" SG_ 2151915520 AHDisbldDrOpnIO "Auto Hold Disabled Door Open Indication On";
BA_ "VNSigAllNodes" SG_ 2151915520 AHDisbldDrOpnIO 1;
BA_ "SignalType" SG_ 2151915520 ElcTransRngSlctVDA "ENM";
BA_ "SignalLongName" SG_ 2151915520 ElcTransRngSlctVDA "Electronic Transmission Range Select Virtual Device Availability";
BA_ "GenSigStartValue" SG_ 2151915520 ElcTransRngSlctVDA 1;
BA_ "VNSigAllNodes" SG_ 2151915520 ElcTransRngSlctVDA 1;
BA_ "GenSigSendType" SG_ 2151489536 ACCLwVisbltyIO 10;
BA_ "SignalType" SG_ 2151489536 ACCLwVisbltyIO "BLN";
BA_ "SignalLongName" SG_ 2151489536 ACCLwVisbltyIO "Adaptive Cruise Control Low Visibility Indication On";
BA_ "VNSigAllNodes" SG_ 2151489536 ACCLwVisbltyIO 1;
BA_ "GenSigSendType" SG_ 2151489536 NVSysStat 10;
BA_ "SignalType" SG_ 2151489536 NVSysStat "ENM";
BA_ "SignalLongName" SG_ 2151489536 NVSysStat "Night Vision System Status";
BA_ "VNSigAllNodes" SG_ 2151489536 NVSysStat 1;
BA_ "GenSigSendType" SG_ 2151489536 RVBShtToPrkBfExtngVehIO 10;
BA_ "GenSigSendOnInit" SG_ 2151489536 RVBShtToPrkBfExtngVehIO 2;
BA_ "SignalType" SG_ 2151489536 RVBShtToPrkBfExtngVehIO "BLN";
BA_ "SignalLongName" SG_ 2151489536 RVBShtToPrkBfExtngVehIO "RVB Shift to Park Before Exiting Vehicle Indication On";
BA_ "VNSigAllNodes" SG_ 2151489536 RVBShtToPrkBfExtngVehIO 1;
BA_ "GenSigSendType" SG_ 2151489536 RVBAutoBrkRlsIO 10;
BA_ "SignalType" SG_ 2151489536 RVBAutoBrkRlsIO "BLN";
BA_ "SignalLongName" SG_ 2151489536 RVBAutoBrkRlsIO "RVB Autonomous Brake Release Indication On";
BA_ "VNSigAllNodes" SG_ 2151489536 RVBAutoBrkRlsIO 1;
BA_ "SignalType" SG_ 590 DgnInf "UNM";
BA_ "SignalLongName" SG_ 590 DgnInf "Diagnostic Information";
BA_ "VNSigDiagnostic" SG_ 590 DgnInf 1;
BA_ "VNSigAllNodes" SG_ 590 DgnInf 1;
BA_ "SignalType" SG_ 586 DgnInf "UNM";
BA_ "SignalLongName" SG_ 586 DgnInf "Diagnostic Information";
BA_ "VNSigDiagnostic" SG_ 586 DgnInf 1;
BA_ "VNSigAllNodes" SG_ 586 DgnInf 1;
BA_ "SignalType" SG_ 596 DgnInf "UNM";
BA_ "SignalLongName" SG_ 596 DgnInf "Diagnostic Information";
BA_ "VNSigDiagnostic" SG_ 596 DgnInf 1;
BA_ "VNSigAllNodes" SG_ 596 DgnInf 1;
BA_ "SignalType" SG_ 582 DgnInf "UNM";
BA_ "SignalLongName" SG_ 582 DgnInf "Diagnostic Information";
BA_ "VNSigDiagnostic" SG_ 582 DgnInf 1;
BA_ "VNSigAllNodes" SG_ 582 DgnInf 1;
BA_ "GenSigDeltaValue" SG_ 257 DgnInf 1;
BA_ "GenSigSendType" SG_ 257 DgnInf 12;
BA_ "SignalType" SG_ 257 DgnInf "UNM";
BA_ "SignalLongName" SG_ 257 DgnInf "Diagnostic Information";
BA_ "VNSigDiagnostic" SG_ 257 DgnInf 1;
BA_ "VNSigAllNodes" SG_ 257 DgnInf 1;
BA_ "SignalType" SG_ 594 DgnInf "UNM";
BA_ "SignalLongName" SG_ 594 DgnInf "Diagnostic Information";
BA_ "VNSigDiagnostic" SG_ 594 DgnInf 1;
BA_ "VNSigAllNodes" SG_ 594 DgnInf 1;
BA_ "SignalType" SG_ 592 DgnInf "UNM";
BA_ "SignalLongName" SG_ 592 DgnInf "Diagnostic Information";
BA_ "VNSigDiagnostic" SG_ 592 DgnInf 1;
BA_ "VNSigAllNodes" SG_ 592 DgnInf 1;
BA_ "SignalType" SG_ 588 DgnInf "UNM";
BA_ "SignalLongName" SG_ 588 DgnInf "Diagnostic Information";
BA_ "VNSigDiagnostic" SG_ 588 DgnInf 1;
BA_ "VNSigAllNodes" SG_ 588 DgnInf 1;
BA_ "SignalType" SG_ 585 DgnInf "UNM";
BA_ "SignalLongName" SG_ 585 DgnInf "Diagnostic Information";
BA_ "VNSigDiagnostic" SG_ 585 DgnInf 1;
BA_ "VNSigAllNodes" SG_ 585 DgnInf 1;
BA_ "SignalType" SG_ 584 DgnInf "UNM";
BA_ "SignalLongName" SG_ 584 DgnInf "Diagnostic Information";
BA_ "VNSigDiagnostic" SG_ 584 DgnInf 1;
BA_ "VNSigAllNodes" SG_ 584 DgnInf 1;
BA_ "SignalType" SG_ 580 DgnInf "UNM";
BA_ "SignalLongName" SG_ 580 DgnInf "Diagnostic Information";
BA_ "VNSigDiagnostic" SG_ 580 DgnInf 1;
BA_ "VNSigAllNodes" SG_ 580 DgnInf 1;
BA_ "SignalType" SG_ 598 DgnInf "UNM";
BA_ "SignalLongName" SG_ 598 DgnInf "Diagnostic Information";
BA_ "VNSigDiagnostic" SG_ 598 DgnInf 1;
BA_ "VNSigAllNodes" SG_ 598 DgnInf 1;
BA_ "SignalType" SG_ 589 DgnInf "UNM";
BA_ "SignalLongName" SG_ 589 DgnInf "Diagnostic Information";
BA_ "VNSigDiagnostic" SG_ 589 DgnInf 1;
BA_ "VNSigAllNodes" SG_ 589 DgnInf 1;
BA_ "SignalType" SG_ 1612 DgnInf "UNM";
BA_ "SignalLongName" SG_ 1612 DgnInf "Diagnostic Information";
BA_ "VNSigDiagnostic" SG_ 1612 DgnInf 1;
BA_ "VNSigAllNodes" SG_ 1612 DgnInf 1;
BA_ "VNSigPrimaryTriggering" SG_ 1580 VectraSpcNWMgtD 1;
BA_ "VNSigRemoteDiagnostics" SG_ 1580 VectraSpcNWMgtD 1;
BA_ "VNSigInfotainment" SG_ 1580 VectraSpcNWMgtD 1;
BA_ "VNSigParkedVehicle" SG_ 1580 VectraSpcNWMgtD 1;
BA_ "VNSigIntermediate" SG_ 1580 VectraSpcNWMgtD 1;
BA_ "VNSigUnused_4" SG_ 1580 VectraSpcNWMgtD 1;
BA_ "SignalType" SG_ 1580 VectraSpcNWMgtD "UNM";
BA_ "SignalLongName" SG_ 1580 VectraSpcNWMgtD "Vectra Specific Network Management Data";
BA_ "VNSigDiagnostic" SG_ 1580 VectraSpcNWMgtD 1;
BA_ "VNSigAllNodes" SG_ 1580 VectraSpcNWMgtD 1;
BA_ "GenSigDeltaValue" SG_ 1356 DgnInf_LS54C 1;
BA_ "GenSigSendType" SG_ 1356 DgnInf_LS54C 12;
BA_ "SignalType" SG_ 1356 DgnInf_LS54C "UNM";
BA_ "SignalLongName" SG_ 1356 DgnInf_LS54C "Diagnostic Information LS54C";
BA_ "VNSigDiagnostic" SG_ 1356 DgnInf_LS54C 1;
BA_ "VNSigAllNodes" SG_ 1356 DgnInf_LS54C 1;
BA_ "GenSigSendType" SG_ 2154676224 CmpsModSlfTstReq 10;
BA_ "SignalType" SG_ 2154676224 CmpsModSlfTstReq "ENM";
BA_ "SignalLongName" SG_ 2154676224 CmpsModSlfTstReq "Compass Module Self Test Request";
BA_ "VNSigAllNodes" SG_ 2154676224 CmpsModSlfTstReq 1;
BA_ "GenSigSendType" SG_ 2154676224 CmpsModManCalReq 10;
BA_ "SignalType" SG_ 2154676224 CmpsModManCalReq "ENM";
BA_ "SignalLongName" SG_ 2154676224 CmpsModManCalReq "Compass Module Manual Calibration Request";
BA_ "VNSigAllNodes" SG_ 2154676224 CmpsModManCalReq 1;
BA_ "GenSigSendType" SG_ 2154676224 CmpsDecZonSetReq 10;
BA_ "SignalType" SG_ 2154676224 CmpsDecZonSetReq "ENM";
BA_ "SignalLongName" SG_ 2154676224 CmpsDecZonSetReq "Compass Declination Zone Set Request";
BA_ "VNSigAllNodes" SG_ 2154676224 CmpsDecZonSetReq 1;
BA_ "GenSigSendType" SG_ 2154676224 CmpsDecZonCmndVal 10;
BA_ "SignalType" SG_ 2154676224 CmpsDecZonCmndVal "ENM";
BA_ "SignalLongName" SG_ 2154676224 CmpsDecZonCmndVal "Compass Declination Zone Commanded Value";
BA_ "VNSigAllNodes" SG_ 2154676224 CmpsDecZonCmndVal 1;
BA_ "GenSigSendType" SG_ 2152857600 ACCGrnMdStat 10;
BA_ "SignalType" SG_ 2152857600 ACCGrnMdStat "ENM";
BA_ "SignalLongName" SG_ 2152857600 ACCGrnMdStat "Adaptive Cruise Control Green Mode Status";
BA_ "VNSigAllNodes" SG_ 2152857600 ACCGrnMdStat 1;
BA_ "GenSigSendType" SG_ 2152857600 ACCRteSpdAdaptStat 10;
BA_ "SignalType" SG_ 2152857600 ACCRteSpdAdaptStat "ENM";
BA_ "SignalLongName" SG_ 2152857600 ACCRteSpdAdaptStat "Adaptive Cruise Control Route Speed Adaption Status";
BA_ "VNSigAllNodes" SG_ 2152857600 ACCRteSpdAdaptStat 1;
BA_ "GenSigSendType" SG_ 2152857600 ACCRteSpdDrvIntvReq 10;
BA_ "SignalType" SG_ 2152857600 ACCRteSpdDrvIntvReq "ENM";
BA_ "SignalLongName" SG_ 2152857600 ACCRteSpdDrvIntvReq "Adaptive Cruise Control Route Speed Driver Intervention Request";
BA_ "VNSigAllNodes" SG_ 2152857600 ACCRteSpdDrvIntvReq 1;
BA_ "GenSigSendType" SG_ 2152857600 ACCTrfcJamAstActStat 10;
BA_ "SignalType" SG_ 2152857600 ACCTrfcJamAstActStat "ENM";
BA_ "SignalLongName" SG_ 2152857600 ACCTrfcJamAstActStat "Adaptive Cruise Control Traffic Jam Assist Activation Status";
BA_ "VNSigAllNodes" SG_ 2152857600 ACCTrfcJamAstActStat 1;
BA_ "GenSigDeltaValue" SG_ 2152857600 ACCTrfcJamAstRmnTm 1;
BA_ "GenSigSendType" SG_ 2152857600 ACCTrfcJamAstRmnTm 12;
BA_ "SignalType" SG_ 2152857600 ACCTrfcJamAstRmnTm "UNM";
BA_ "SignalLongName" SG_ 2152857600 ACCTrfcJamAstRmnTm "Adaptive Cruise Control Traffic Jam Assist Remaining Time";
BA_ "VNSigAllNodes" SG_ 2152857600 ACCTrfcJamAstRmnTm 1;
BA_ "GenSigSendType" SG_ 2154995712 HVHtrFldIO 10;
BA_ "SignalType" SG_ 2154995712 HVHtrFldIO "BLN";
BA_ "SignalLongName" SG_ 2154995712 HVHtrFldIO "High Voltage Heater Failed Indication On";
BA_ "VNSigAllNodes" SG_ 2154995712 HVHtrFldIO 1;
BA_ "GenSigSendType" SG_ 2154995712 HVHtrOvrTmpIndOn 10;
BA_ "SignalType" SG_ 2154995712 HVHtrOvrTmpIndOn "BLN";
BA_ "SignalLongName" SG_ 2154995712 HVHtrOvrTmpIndOn "High Voltage Heater Over Temperature Indication On";
BA_ "VNSigAllNodes" SG_ 2154995712 HVHtrOvrTmpIndOn 1;
BA_ "GenSigDeltaValue" SG_ 2150817792 ImpTimeToMaxDeltaVel 1;
BA_ "GenSigSendType" SG_ 2150817792 ImpTimeToMaxDeltaVel 12;
BA_ "VNSigPrimaryTriggering" SG_ 2150817792 ImpTimeToMaxDeltaVel 1;
BA_ "SignalType" SG_ 2150817792 ImpTimeToMaxDeltaVel "UNM";
BA_ "SignalLongName" SG_ 2150817792 ImpTimeToMaxDeltaVel "Impact Time to Maximum Delta Velocity";
BA_ "VNSigAllNodes" SG_ 2150817792 ImpTimeToMaxDeltaVel 1;
BA_ "GenSigDeltaValue" SG_ 2150817792 ImpMaxLongDeltaVel 1;
BA_ "GenSigSendType" SG_ 2150817792 ImpMaxLongDeltaVel 12;
BA_ "VNSigPrimaryTriggering" SG_ 2150817792 ImpMaxLongDeltaVel 1;
BA_ "SignalType" SG_ 2150817792 ImpMaxLongDeltaVel "SNM";
BA_ "SignalLongName" SG_ 2150817792 ImpMaxLongDeltaVel "Impact Maximum Longitudinal Delta Velocity";
BA_ "VNSigAllNodes" SG_ 2150817792 ImpMaxLongDeltaVel 1;
BA_ "GenSigDeltaValue" SG_ 2150817792 ImpMaxLateralDeltaVel 1;
BA_ "GenSigSendType" SG_ 2150817792 ImpMaxLateralDeltaVel 12;
BA_ "VNSigPrimaryTriggering" SG_ 2150817792 ImpMaxLateralDeltaVel 1;
BA_ "SignalType" SG_ 2150817792 ImpMaxLateralDeltaVel "SNM";
BA_ "SignalLongName" SG_ 2150817792 ImpMaxLateralDeltaVel "Impact Maximum Lateral Delta Velocity";
BA_ "VNSigAllNodes" SG_ 2150817792 ImpMaxLateralDeltaVel 1;
BA_ "GenSigDeltaValue" SG_ 2150809600 IDVS12_Axis2 1;
BA_ "GenSigSendType" SG_ 2150809600 IDVS12_Axis2 12;
BA_ "VNSigPrimaryTriggering" SG_ 2150809600 IDVS12_Axis2 1;
BA_ "SignalType" SG_ 2150809600 IDVS12_Axis2 "SNM";
BA_ "PacketOrder" SG_ 2150809600 IDVS12_Axis2 2;
BA_ "SignalLongName" SG_ 2150809600 IDVS12_Axis2 "Impact Delta Velocity Sample 12 : Axis 2";
BA_ "VNSigAllNodes" SG_ 2150809600 IDVS12_Axis2 1;
BA_ "GenSigDeltaValue" SG_ 2150809600 IDVS12_Axis1 1;
BA_ "GenSigSendType" SG_ 2150809600 IDVS12_Axis1 12;
BA_ "VNSigPrimaryTriggering" SG_ 2150809600 IDVS12_Axis1 1;
BA_ "SignalType" SG_ 2150809600 IDVS12_Axis1 "SNM";
BA_ "PacketOrder" SG_ 2150809600 IDVS12_Axis1 1;
BA_ "SignalLongName" SG_ 2150809600 IDVS12_Axis1 "Impact Delta Velocity Sample 12 : Axis 1";
BA_ "VNSigAllNodes" SG_ 2150809600 IDVS12_Axis1 1;
BA_ "GenSigDeltaValue" SG_ 2150809600 IDVS13_Axis2 1;
BA_ "GenSigSendType" SG_ 2150809600 IDVS13_Axis2 12;
BA_ "VNSigPrimaryTriggering" SG_ 2150809600 IDVS13_Axis2 1;
BA_ "SignalType" SG_ 2150809600 IDVS13_Axis2 "SNM";
BA_ "PacketOrder" SG_ 2150809600 IDVS13_Axis2 2;
BA_ "SignalLongName" SG_ 2150809600 IDVS13_Axis2 "Impact Delta Velocity Sample 13 : Axis 2";
BA_ "VNSigAllNodes" SG_ 2150809600 IDVS13_Axis2 1;
BA_ "GenSigDeltaValue" SG_ 2150809600 IDVS13_Axis1 1;
BA_ "GenSigSendType" SG_ 2150809600 IDVS13_Axis1 12;
BA_ "VNSigPrimaryTriggering" SG_ 2150809600 IDVS13_Axis1 1;
BA_ "SignalType" SG_ 2150809600 IDVS13_Axis1 "SNM";
BA_ "PacketOrder" SG_ 2150809600 IDVS13_Axis1 1;
BA_ "SignalLongName" SG_ 2150809600 IDVS13_Axis1 "Impact Delta Velocity Sample 13 : Axis 1";
BA_ "VNSigAllNodes" SG_ 2150809600 IDVS13_Axis1 1;
BA_ "GenSigDeltaValue" SG_ 2150809600 IDVS14_Axis2 1;
BA_ "GenSigSendType" SG_ 2150809600 IDVS14_Axis2 12;
BA_ "VNSigPrimaryTriggering" SG_ 2150809600 IDVS14_Axis2 1;
BA_ "SignalType" SG_ 2150809600 IDVS14_Axis2 "SNM";
BA_ "PacketOrder" SG_ 2150809600 IDVS14_Axis2 2;
BA_ "SignalLongName" SG_ 2150809600 IDVS14_Axis2 "Impact Delta Velocity Sample 14 : Axis 2";
BA_ "VNSigAllNodes" SG_ 2150809600 IDVS14_Axis2 1;
BA_ "GenSigDeltaValue" SG_ 2150809600 IDVS14_Axis1 1;
BA_ "GenSigSendType" SG_ 2150809600 IDVS14_Axis1 12;
BA_ "VNSigPrimaryTriggering" SG_ 2150809600 IDVS14_Axis1 1;
BA_ "SignalType" SG_ 2150809600 IDVS14_Axis1 "SNM";
BA_ "PacketOrder" SG_ 2150809600 IDVS14_Axis1 1;
BA_ "SignalLongName" SG_ 2150809600 IDVS14_Axis1 "Impact Delta Velocity Sample 14 : Axis 1";
BA_ "VNSigAllNodes" SG_ 2150809600 IDVS14_Axis1 1;
BA_ "GenSigDeltaValue" SG_ 2150809600 IDVS15_Axis2 1;
BA_ "GenSigSendType" SG_ 2150809600 IDVS15_Axis2 12;
BA_ "VNSigPrimaryTriggering" SG_ 2150809600 IDVS15_Axis2 1;
BA_ "SignalType" SG_ 2150809600 IDVS15_Axis2 "SNM";
BA_ "PacketOrder" SG_ 2150809600 IDVS15_Axis2 2;
BA_ "SignalLongName" SG_ 2150809600 IDVS15_Axis2 "Impact Delta Velocity Sample 15 : Axis 2";
BA_ "VNSigAllNodes" SG_ 2150809600 IDVS15_Axis2 1;
BA_ "GenSigDeltaValue" SG_ 2150809600 IDVS15_Axis1 1;
BA_ "GenSigSendType" SG_ 2150809600 IDVS15_Axis1 12;
BA_ "VNSigPrimaryTriggering" SG_ 2150809600 IDVS15_Axis1 1;
BA_ "SignalType" SG_ 2150809600 IDVS15_Axis1 "SNM";
BA_ "PacketOrder" SG_ 2150809600 IDVS15_Axis1 1;
BA_ "SignalLongName" SG_ 2150809600 IDVS15_Axis1 "Impact Delta Velocity Sample 15 : Axis 1";
BA_ "VNSigAllNodes" SG_ 2150809600 IDVS15_Axis1 1;
BA_ "GenSigDeltaValue" SG_ 2150801408 IDVS10_Axis2 1;
BA_ "GenSigSendType" SG_ 2150801408 IDVS10_Axis2 12;
BA_ "VNSigPrimaryTriggering" SG_ 2150801408 IDVS10_Axis2 1;
BA_ "SignalType" SG_ 2150801408 IDVS10_Axis2 "SNM";
BA_ "PacketOrder" SG_ 2150801408 IDVS10_Axis2 2;
BA_ "SignalLongName" SG_ 2150801408 IDVS10_Axis2 "Impact Delta Velocity Sample 10 : Axis 2";
BA_ "VNSigAllNodes" SG_ 2150801408 IDVS10_Axis2 1;
BA_ "GenSigDeltaValue" SG_ 2150801408 IDVS10_Axis1 1;
BA_ "GenSigSendType" SG_ 2150801408 IDVS10_Axis1 12;
BA_ "VNSigPrimaryTriggering" SG_ 2150801408 IDVS10_Axis1 1;
BA_ "SignalType" SG_ 2150801408 IDVS10_Axis1 "SNM";
BA_ "PacketOrder" SG_ 2150801408 IDVS10_Axis1 1;
BA_ "SignalLongName" SG_ 2150801408 IDVS10_Axis1 "Impact Delta Velocity Sample 10 : Axis 1";
BA_ "VNSigAllNodes" SG_ 2150801408 IDVS10_Axis1 1;
BA_ "GenSigDeltaValue" SG_ 2150801408 IDVS11_Axis2 1;
BA_ "GenSigSendType" SG_ 2150801408 IDVS11_Axis2 12;
BA_ "VNSigPrimaryTriggering" SG_ 2150801408 IDVS11_Axis2 1;
BA_ "SignalType" SG_ 2150801408 IDVS11_Axis2 "SNM";
BA_ "PacketOrder" SG_ 2150801408 IDVS11_Axis2 2;
BA_ "SignalLongName" SG_ 2150801408 IDVS11_Axis2 "Impact Delta Velocity Sample 11 : Axis 2";
BA_ "VNSigAllNodes" SG_ 2150801408 IDVS11_Axis2 1;
BA_ "GenSigDeltaValue" SG_ 2150801408 IDVS11_Axis1 1;
BA_ "GenSigSendType" SG_ 2150801408 IDVS11_Axis1 12;
BA_ "VNSigPrimaryTriggering" SG_ 2150801408 IDVS11_Axis1 1;
BA_ "SignalType" SG_ 2150801408 IDVS11_Axis1 "SNM";
BA_ "PacketOrder" SG_ 2150801408 IDVS11_Axis1 1;
BA_ "SignalLongName" SG_ 2150801408 IDVS11_Axis1 "Impact Delta Velocity Sample 11 : Axis 1";
BA_ "VNSigAllNodes" SG_ 2150801408 IDVS11_Axis1 1;
BA_ "GenSigDeltaValue" SG_ 2150801408 IDVS8_Axis2 1;
BA_ "GenSigSendType" SG_ 2150801408 IDVS8_Axis2 12;
BA_ "VNSigPrimaryTriggering" SG_ 2150801408 IDVS8_Axis2 1;
BA_ "SignalType" SG_ 2150801408 IDVS8_Axis2 "SNM";
BA_ "PacketOrder" SG_ 2150801408 IDVS8_Axis2 2;
BA_ "SignalLongName" SG_ 2150801408 IDVS8_Axis2 "Impact Delta Velocity Sample 8 : Axis 2";
BA_ "VNSigAllNodes" SG_ 2150801408 IDVS8_Axis2 1;
BA_ "GenSigDeltaValue" SG_ 2150801408 IDVS8_Axis1 1;
BA_ "GenSigSendType" SG_ 2150801408 IDVS8_Axis1 12;
BA_ "VNSigPrimaryTriggering" SG_ 2150801408 IDVS8_Axis1 1;
BA_ "SignalType" SG_ 2150801408 IDVS8_Axis1 "SNM";
BA_ "PacketOrder" SG_ 2150801408 IDVS8_Axis1 1;
BA_ "SignalLongName" SG_ 2150801408 IDVS8_Axis1 "Impact Delta Velocity Sample 8 : Axis 1";
BA_ "VNSigAllNodes" SG_ 2150801408 IDVS8_Axis1 1;
BA_ "GenSigDeltaValue" SG_ 2150801408 IDVS9_Axis2 1;
BA_ "GenSigSendType" SG_ 2150801408 IDVS9_Axis2 12;
BA_ "VNSigPrimaryTriggering" SG_ 2150801408 IDVS9_Axis2 1;
BA_ "SignalType" SG_ 2150801408 IDVS9_Axis2 "SNM";
BA_ "PacketOrder" SG_ 2150801408 IDVS9_Axis2 2;
BA_ "SignalLongName" SG_ 2150801408 IDVS9_Axis2 "Impact Delta Velocity Sample 9 : Axis 2";
BA_ "VNSigAllNodes" SG_ 2150801408 IDVS9_Axis2 1;
BA_ "GenSigDeltaValue" SG_ 2150801408 IDVS9_Axis1 1;
BA_ "GenSigSendType" SG_ 2150801408 IDVS9_Axis1 12;
BA_ "VNSigPrimaryTriggering" SG_ 2150801408 IDVS9_Axis1 1;
BA_ "SignalType" SG_ 2150801408 IDVS9_Axis1 "SNM";
BA_ "PacketOrder" SG_ 2150801408 IDVS9_Axis1 1;
BA_ "SignalLongName" SG_ 2150801408 IDVS9_Axis1 "Impact Delta Velocity Sample 9 : Axis 1";
BA_ "VNSigAllNodes" SG_ 2150801408 IDVS9_Axis1 1;
BA_ "GenSigDeltaValue" SG_ 2150793216 IDVS4_Axis2 1;
BA_ "GenSigSendType" SG_ 2150793216 IDVS4_Axis2 12;
BA_ "VNSigPrimaryTriggering" SG_ 2150793216 IDVS4_Axis2 1;
BA_ "SignalType" SG_ 2150793216 IDVS4_Axis2 "SNM";
BA_ "PacketOrder" SG_ 2150793216 IDVS4_Axis2 2;
BA_ "SignalLongName" SG_ 2150793216 IDVS4_Axis2 "Impact Delta Velocity Sample 4 : Axis 2";
BA_ "VNSigAllNodes" SG_ 2150793216 IDVS4_Axis2 1;
BA_ "GenSigDeltaValue" SG_ 2150793216 IDVS4_Axis1 1;
BA_ "GenSigSendType" SG_ 2150793216 IDVS4_Axis1 12;
BA_ "VNSigPrimaryTriggering" SG_ 2150793216 IDVS4_Axis1 1;
BA_ "SignalType" SG_ 2150793216 IDVS4_Axis1 "SNM";
BA_ "PacketOrder" SG_ 2150793216 IDVS4_Axis1 1;
BA_ "SignalLongName" SG_ 2150793216 IDVS4_Axis1 "Impact Delta Velocity Sample 4 : Axis 1";
BA_ "VNSigAllNodes" SG_ 2150793216 IDVS4_Axis1 1;
BA_ "GenSigDeltaValue" SG_ 2150793216 IDVS5_Axis2 1;
BA_ "GenSigSendType" SG_ 2150793216 IDVS5_Axis2 12;
BA_ "VNSigPrimaryTriggering" SG_ 2150793216 IDVS5_Axis2 1;
BA_ "SignalType" SG_ 2150793216 IDVS5_Axis2 "SNM";
BA_ "PacketOrder" SG_ 2150793216 IDVS5_Axis2 2;
BA_ "SignalLongName" SG_ 2150793216 IDVS5_Axis2 "Impact Delta Velocity Sample 5 : Axis 2";
BA_ "VNSigAllNodes" SG_ 2150793216 IDVS5_Axis2 1;
BA_ "GenSigDeltaValue" SG_ 2150793216 IDVS5_Axis1 1;
BA_ "GenSigSendType" SG_ 2150793216 IDVS5_Axis1 12;
BA_ "VNSigPrimaryTriggering" SG_ 2150793216 IDVS5_Axis1 1;
BA_ "SignalType" SG_ 2150793216 IDVS5_Axis1 "SNM";
BA_ "PacketOrder" SG_ 2150793216 IDVS5_Axis1 1;
BA_ "SignalLongName" SG_ 2150793216 IDVS5_Axis1 "Impact Delta Velocity Sample 5 : Axis 1";
BA_ "VNSigAllNodes" SG_ 2150793216 IDVS5_Axis1 1;
BA_ "GenSigDeltaValue" SG_ 2150793216 IDVS6_Axis2 1;
BA_ "GenSigSendType" SG_ 2150793216 IDVS6_Axis2 12;
BA_ "VNSigPrimaryTriggering" SG_ 2150793216 IDVS6_Axis2 1;
BA_ "SignalType" SG_ 2150793216 IDVS6_Axis2 "SNM";
BA_ "PacketOrder" SG_ 2150793216 IDVS6_Axis2 2;
BA_ "SignalLongName" SG_ 2150793216 IDVS6_Axis2 "Impact Delta Velocity Sample 6 : Axis 2";
BA_ "VNSigAllNodes" SG_ 2150793216 IDVS6_Axis2 1;
BA_ "GenSigDeltaValue" SG_ 2150793216 IDVS6_Axis1 1;
BA_ "GenSigSendType" SG_ 2150793216 IDVS6_Axis1 12;
BA_ "VNSigPrimaryTriggering" SG_ 2150793216 IDVS6_Axis1 1;
BA_ "SignalType" SG_ 2150793216 IDVS6_Axis1 "SNM";
BA_ "PacketOrder" SG_ 2150793216 IDVS6_Axis1 1;
BA_ "SignalLongName" SG_ 2150793216 IDVS6_Axis1 "Impact Delta Velocity Sample 6 : Axis 1";
BA_ "VNSigAllNodes" SG_ 2150793216 IDVS6_Axis1 1;
BA_ "GenSigDeltaValue" SG_ 2150793216 IDVS7_Axis2 1;
BA_ "GenSigSendType" SG_ 2150793216 IDVS7_Axis2 12;
BA_ "VNSigPrimaryTriggering" SG_ 2150793216 IDVS7_Axis2 1;
BA_ "SignalType" SG_ 2150793216 IDVS7_Axis2 "SNM";
BA_ "PacketOrder" SG_ 2150793216 IDVS7_Axis2 2;
BA_ "SignalLongName" SG_ 2150793216 IDVS7_Axis2 "Impact Delta Velocity Sample 7 : Axis 2";
BA_ "VNSigAllNodes" SG_ 2150793216 IDVS7_Axis2 1;
BA_ "GenSigDeltaValue" SG_ 2150793216 IDVS7_Axis1 1;
BA_ "GenSigSendType" SG_ 2150793216 IDVS7_Axis1 12;
BA_ "VNSigPrimaryTriggering" SG_ 2150793216 IDVS7_Axis1 1;
BA_ "SignalType" SG_ 2150793216 IDVS7_Axis1 "SNM";
BA_ "PacketOrder" SG_ 2150793216 IDVS7_Axis1 1;
BA_ "SignalLongName" SG_ 2150793216 IDVS7_Axis1 "Impact Delta Velocity Sample 7 : Axis 1";
BA_ "VNSigAllNodes" SG_ 2150793216 IDVS7_Axis1 1;
BA_ "GenSigDeltaValue" SG_ 2150785024 AirbgAccelOrien 1;
BA_ "GenSigSendType" SG_ 2150785024 AirbgAccelOrien 12;
BA_ "VNSigPrimaryTriggering" SG_ 2150785024 AirbgAccelOrien 1;
BA_ "SignalType" SG_ 2150785024 AirbgAccelOrien "UNM";
BA_ "SignalLongName" SG_ 2150785024 AirbgAccelOrien "Airbag Accelerometer Orientation";
BA_ "VNSigAllNodes" SG_ 2150785024 AirbgAccelOrien 1;
BA_ "GenSigDeltaValue" SG_ 2150785024 IDVS1_Axis2 1;
BA_ "GenSigSendType" SG_ 2150785024 IDVS1_Axis2 12;
BA_ "VNSigPrimaryTriggering" SG_ 2150785024 IDVS1_Axis2 1;
BA_ "SignalType" SG_ 2150785024 IDVS1_Axis2 "SNM";
BA_ "PacketOrder" SG_ 2150785024 IDVS1_Axis2 2;
BA_ "SignalLongName" SG_ 2150785024 IDVS1_Axis2 "Impact Delta Velocity Sample 1 : Axis 2";
BA_ "VNSigAllNodes" SG_ 2150785024 IDVS1_Axis2 1;
BA_ "GenSigSendType" SG_ 2150785024 IDVS1_Axis1 12;
BA_ "VNSigPrimaryTriggering" SG_ 2150785024 IDVS1_Axis1 1;
BA_ "SignalType" SG_ 2150785024 IDVS1_Axis1 "SNM";
BA_ "PacketOrder" SG_ 2150785024 IDVS1_Axis1 1;
BA_ "SignalLongName" SG_ 2150785024 IDVS1_Axis1 "Impact Delta Velocity Sample 1 : Axis 1";
BA_ "VNSigAllNodes" SG_ 2150785024 IDVS1_Axis1 1;
BA_ "GenSigDeltaValue" SG_ 2150785024 IDVS2_Axis2 1;
BA_ "GenSigSendType" SG_ 2150785024 IDVS2_Axis2 12;
BA_ "VNSigPrimaryTriggering" SG_ 2150785024 IDVS2_Axis2 1;
BA_ "SignalType" SG_ 2150785024 IDVS2_Axis2 "SNM";
BA_ "PacketOrder" SG_ 2150785024 IDVS2_Axis2 2;
BA_ "SignalLongName" SG_ 2150785024 IDVS2_Axis2 "Impact Delta Velocity Sample 2 : Axis 2";
BA_ "VNSigAllNodes" SG_ 2150785024 IDVS2_Axis2 1;
BA_ "GenSigDeltaValue" SG_ 2150785024 IDVS2_Axis1 1;
BA_ "GenSigSendType" SG_ 2150785024 IDVS2_Axis1 12;
BA_ "VNSigPrimaryTriggering" SG_ 2150785024 IDVS2_Axis1 1;
BA_ "SignalType" SG_ 2150785024 IDVS2_Axis1 "SNM";
BA_ "PacketOrder" SG_ 2150785024 IDVS2_Axis1 1;
BA_ "SignalLongName" SG_ 2150785024 IDVS2_Axis1 "Impact Delta Velocity Sample 2 : Axis 1";
BA_ "VNSigAllNodes" SG_ 2150785024 IDVS2_Axis1 1;
BA_ "GenSigDeltaValue" SG_ 2150785024 IDVS3_Axis2 1;
BA_ "GenSigSendType" SG_ 2150785024 IDVS3_Axis2 12;
BA_ "VNSigPrimaryTriggering" SG_ 2150785024 IDVS3_Axis2 1;
BA_ "SignalType" SG_ 2150785024 IDVS3_Axis2 "SNM";
BA_ "PacketOrder" SG_ 2150785024 IDVS3_Axis2 2;
BA_ "SignalLongName" SG_ 2150785024 IDVS3_Axis2 "Impact Delta Velocity Sample 3 : Axis 2";
BA_ "VNSigAllNodes" SG_ 2150785024 IDVS3_Axis2 1;
BA_ "GenSigDeltaValue" SG_ 2150785024 IDVS3_Axis1 1;
BA_ "GenSigSendType" SG_ 2150785024 IDVS3_Axis1 12;
BA_ "VNSigPrimaryTriggering" SG_ 2150785024 IDVS3_Axis1 1;
BA_ "SignalType" SG_ 2150785024 IDVS3_Axis1 "SNM";
BA_ "PacketOrder" SG_ 2150785024 IDVS3_Axis1 1;
BA_ "SignalLongName" SG_ 2150785024 IDVS3_Axis1 "Impact Delta Velocity Sample 3 : Axis 1";
BA_ "VNSigAllNodes" SG_ 2150785024 IDVS3_Axis1 1;
BA_ "GenSigDeltaValue" SG_ 2150785024 ImpDltVlcScal 1;
BA_ "GenSigSendType" SG_ 2150785024 ImpDltVlcScal 12;
BA_ "VNSigPrimaryTriggering" SG_ 2150785024 ImpDltVlcScal 1;
BA_ "SignalType" SG_ 2150785024 ImpDltVlcScal "UNM";
BA_ "SignalLongName" SG_ 2150785024 ImpDltVlcScal "Impact Delta Velocity Scaling";
BA_ "VNSigAllNodes" SG_ 2150785024 ImpDltVlcScal 1;
BA_ "GenSigSendType" SG_ 2150825984 PdstIntdProtSysDplyd 10;
BA_ "SignalType" SG_ 2150825984 PdstIntdProtSysDplyd "BLN";
BA_ "SignalLongName" SG_ 2150825984 PdstIntdProtSysDplyd "Pedestrian Integrated Protection System Deployed";
BA_ "VNSigAllNodes" SG_ 2150825984 PdstIntdProtSysDplyd 1;
BA_ "GenSigSendType" SG_ 2150825984 PdstIntdProtSysDsbld 10;
BA_ "SignalType" SG_ 2150825984 PdstIntdProtSysDsbld "BLN";
BA_ "SignalLongName" SG_ 2150825984 PdstIntdProtSysDsbld "Pedestrian Integrated Protection System Disabled";
BA_ "VNSigAllNodes" SG_ 2150825984 PdstIntdProtSysDsbld 1;
BA_ "GenSigSendType" SG_ 2150825984 SrvIntdPdstProtSysIO 10;
BA_ "SignalType" SG_ 2150825984 SrvIntdPdstProtSysIO "BLN";
BA_ "SignalLongName" SG_ 2150825984 SrvIntdPdstProtSysIO "Service Integrated Pedestrian Protection System Indication On";
BA_ "VNSigAllNodes" SG_ 2150825984 SrvIntdPdstProtSysIO 1;
BA_ "GenSigSendType" SG_ 2150825984 FstnThrdRwRtPsStbtInR 10;
BA_ "SignalType" SG_ 2150825984 FstnThrdRwRtPsStbtInR "ENM";
BA_ "SignalLongName" SG_ 2150825984 FstnThrdRwRtPsStbtInR "Fasten Third Row Right Passenger Seatbelt Indication Request";
BA_ "VNSigAllNodes" SG_ 2150825984 FstnThrdRwRtPsStbtInR 1;
BA_ "GenSigSendType" SG_ 2150825984 FstnThrdRwLtPsStbtInR 10;
BA_ "SignalType" SG_ 2150825984 FstnThrdRwLtPsStbtInR "ENM";
BA_ "SignalLongName" SG_ 2150825984 FstnThrdRwLtPsStbtInR "Fasten Third Row Left Passenger Seatbelt Indication Request";
BA_ "VNSigAllNodes" SG_ 2150825984 FstnThrdRwLtPsStbtInR 1;
BA_ "GenSigSendType" SG_ 2150825984 FstnThrdRwCtPsStbtInR 10;
BA_ "SignalType" SG_ 2150825984 FstnThrdRwCtPsStbtInR "ENM";
BA_ "SignalLongName" SG_ 2150825984 FstnThrdRwCtPsStbtInR "Fasten Third Row Center Passenger Seatbelt Indication Request";
BA_ "VNSigAllNodes" SG_ 2150825984 FstnThrdRwCtPsStbtInR 1;
BA_ "GenSigSendType" SG_ 2150825984 FPSIC_IndPer 10;
BA_ "GenSigSendOnInit" SG_ 2150825984 FPSIC_IndPer 1;
BA_ "GenSigStartValue" SG_ 2150825984 FPSIC_IndPer 3;
BA_ "SignalType" SG_ 2150825984 FPSIC_IndPer "ENM";
BA_ "PacketOrder" SG_ 2150825984 FPSIC_IndPer 3;
BA_ "SignalLongName" SG_ 2150825984 FPSIC_IndPer "Fasten Passenger Seatbelt Indication Control : Indication Period";
BA_ "VNSigAllNodes" SG_ 2150825984 FPSIC_IndPer 1;
BA_ "GenSigSendType" SG_ 2150825984 FPSIC_IO 10;
BA_ "GenSigSendOnInit" SG_ 2150825984 FPSIC_IO 1;
BA_ "SignalType" SG_ 2150825984 FPSIC_IO "BLN";
BA_ "PacketOrder" SG_ 2150825984 FPSIC_IO 1;
BA_ "SignalLongName" SG_ 2150825984 FPSIC_IO "Fasten Passenger Seatbelt Indication Control : Indication On";
BA_ "VNSigAllNodes" SG_ 2150825984 FPSIC_IO 1;
BA_ "GenSigDeltaValue" SG_ 2150825984 FPSIC_IndDtCyc 1;
BA_ "GenSigSendType" SG_ 2150825984 FPSIC_IndDtCyc 12;
BA_ "GenSigSendOnInit" SG_ 2150825984 FPSIC_IndDtCyc 1;
BA_ "GenSigStartValue" SG_ 2150825984 FPSIC_IndDtCyc 7;
BA_ "SignalType" SG_ 2150825984 FPSIC_IndDtCyc "UNM";
BA_ "PacketOrder" SG_ 2150825984 FPSIC_IndDtCyc 2;
BA_ "SignalLongName" SG_ 2150825984 FPSIC_IndDtCyc "Fasten Passenger Seatbelt Indication Control : Indication Duty Cycle";
BA_ "VNSigAllNodes" SG_ 2150825984 FPSIC_IndDtCyc 1;
BA_ "GenSigSendType" SG_ 2150825984 FDSIC_IndPer 10;
BA_ "GenSigSendOnInit" SG_ 2150825984 FDSIC_IndPer 1;
BA_ "GenSigStartValue" SG_ 2150825984 FDSIC_IndPer 3;
BA_ "SignalType" SG_ 2150825984 FDSIC_IndPer "ENM";
BA_ "PacketOrder" SG_ 2150825984 FDSIC_IndPer 3;
BA_ "SignalLongName" SG_ 2150825984 FDSIC_IndPer "Fasten Driver Seatbelt Indication Control : Indication Period";
BA_ "VNSigAllNodes" SG_ 2150825984 FDSIC_IndPer 1;
BA_ "GenSigSendType" SG_ 2150825984 FDSIC_IO 10;
BA_ "GenSigSendOnInit" SG_ 2150825984 FDSIC_IO 1;
BA_ "SignalType" SG_ 2150825984 FDSIC_IO "BLN";
BA_ "PacketOrder" SG_ 2150825984 FDSIC_IO 1;
BA_ "SignalLongName" SG_ 2150825984 FDSIC_IO "Fasten Driver Seatbelt Indication Control : Indication On";
BA_ "VNSigAllNodes" SG_ 2150825984 FDSIC_IO 1;
BA_ "GenSigDeltaValue" SG_ 2150825984 FDSIC_IndDC 1;
BA_ "GenSigSendType" SG_ 2150825984 FDSIC_IndDC 12;
BA_ "GenSigSendOnInit" SG_ 2150825984 FDSIC_IndDC 1;
BA_ "GenSigStartValue" SG_ 2150825984 FDSIC_IndDC 7;
BA_ "SignalType" SG_ 2150825984 FDSIC_IndDC "UNM";
BA_ "PacketOrder" SG_ 2150825984 FDSIC_IndDC 2;
BA_ "SignalLongName" SG_ 2150825984 FDSIC_IndDC "Fasten Driver Seatbelt Indication Control : Indication Duty Cycle";
BA_ "VNSigAllNodes" SG_ 2150825984 FDSIC_IndDC 1;
BA_ "GenSigSendType" SG_ 2150825984 AirbgFldIO 10;
BA_ "GenSigSendOnInit" SG_ 2150825984 AirbgFldIO 1;
BA_ "SignalType" SG_ 2150825984 AirbgFldIO "BLN";
BA_ "SignalLongName" SG_ 2150825984 AirbgFldIO "Airbag Failed Indication On";
BA_ "VNSigAllNodes" SG_ 2150825984 AirbgFldIO 1;
BA_ "GenSigSendType" SG_ 2150825984 SndRwStbltRdIndMd 10;
BA_ "SignalType" SG_ 2150825984 SndRwStbltRdIndMd "ENM";
BA_ "SignalLongName" SG_ 2150825984 SndRwStbltRdIndMd "Second Row Seatbelt Reminder Indication Mode";
BA_ "VNSigAllNodes" SG_ 2150825984 SndRwStbltRdIndMd 1;
BA_ "GenSigSendType" SG_ 2150825984 AirbgICIndPer 10;
BA_ "VNSigPrimaryTriggering" SG_ 2150825984 AirbgICIndPer 1;
BA_ "SignalType" SG_ 2150825984 AirbgICIndPer "ENM";
BA_ "PacketOrder" SG_ 2150825984 AirbgICIndPer 3;
BA_ "SignalLongName" SG_ 2150825984 AirbgICIndPer "Airbag Indication Control : Indication Period";
BA_ "VNSigAllNodes" SG_ 2150825984 AirbgICIndPer 1;
BA_ "GenSigDeltaValue" SG_ 2150825984 AirbgICDutCyc 1;
BA_ "GenSigSendType" SG_ 2150825984 AirbgICDutCyc 12;
BA_ "VNSigPrimaryTriggering" SG_ 2150825984 AirbgICDutCyc 1;
BA_ "SignalType" SG_ 2150825984 AirbgICDutCyc "UNM";
BA_ "PacketOrder" SG_ 2150825984 AirbgICDutCyc 2;
BA_ "SignalLongName" SG_ 2150825984 AirbgICDutCyc "Airbag Indication Control : Indication Duty Cycle";
BA_ "VNSigAllNodes" SG_ 2150825984 AirbgICDutCyc 1;
BA_ "GenSigSendType" SG_ 2150825984 AirbgICIO 10;
BA_ "VNSigPrimaryTriggering" SG_ 2150825984 AirbgICIO 1;
BA_ "SignalType" SG_ 2150825984 AirbgICIO "BLN";
BA_ "PacketOrder" SG_ 2150825984 AirbgICIO 1;
BA_ "SignalLongName" SG_ 2150825984 AirbgICIO "Airbag Indication Control : Indication On";
BA_ "VNSigAllNodes" SG_ 2150825984 AirbgICIO 1;
BA_ "GenSigSendType" SG_ 2150825984 FstnSndRwRtPsStbtInR 10;
BA_ "SignalType" SG_ 2150825984 FstnSndRwRtPsStbtInR "ENM";
BA_ "SignalLongName" SG_ 2150825984 FstnSndRwRtPsStbtInR "Fasten Second Row Right Passenger Seatbelt Indication Request";
BA_ "VNSigAllNodes" SG_ 2150825984 FstnSndRwRtPsStbtInR 1;
BA_ "GenSigSendType" SG_ 2150825984 FstnSndRwLtPsStbtInR 10;
BA_ "SignalType" SG_ 2150825984 FstnSndRwLtPsStbtInR "ENM";
BA_ "SignalLongName" SG_ 2150825984 FstnSndRwLtPsStbtInR "Fasten Second Row Left Passenger Seatbelt Indication Request";
BA_ "VNSigAllNodes" SG_ 2150825984 FstnSndRwLtPsStbtInR 1;
BA_ "GenSigSendType" SG_ 2150825984 FstnSndRwCtPsStbtInR 10;
BA_ "SignalType" SG_ 2150825984 FstnSndRwCtPsStbtInR "ENM";
BA_ "SignalLongName" SG_ 2150825984 FstnSndRwCtPsStbtInR "Fasten Second Row Center Passenger Seatbelt Indication Request";
BA_ "VNSigAllNodes" SG_ 2150825984 FstnSndRwCtPsStbtInR 1;
BA_ "GenSigSendType" SG_ 2150825984 FsnDrStbAuxIR 10;
BA_ "GenSigSendOnInit" SG_ 2150825984 FsnDrStbAuxIR 1;
BA_ "SignalType" SG_ 2150825984 FsnDrStbAuxIR "ENM";
BA_ "SignalLongName" SG_ 2150825984 FsnDrStbAuxIR "Fasten Driver Seatbelt Auxiliary Indication Request";
BA_ "VNSigAllNodes" SG_ 2150825984 FsnDrStbAuxIR 1;
BA_ "GenSigSendType" SG_ 2150825984 FsnPsStbAuxIR 10;
BA_ "GenSigSendOnInit" SG_ 2150825984 FsnPsStbAuxIR 1;
BA_ "SignalType" SG_ 2150825984 FsnPsStbAuxIR "ENM";
BA_ "SignalLongName" SG_ 2150825984 FsnPsStbAuxIR "Fasten Passenger Seatbelt Auxiliary Indication Request";
BA_ "VNSigAllNodes" SG_ 2150825984 FsnPsStbAuxIR 1;
BA_ "GenSigSendType" SG_ 2151268352 ClmnLckTT 10;
BA_ "GenSigSendOnInit" SG_ 2151268352 ClmnLckTT 1;
BA_ "SignalType" SG_ 2151268352 ClmnLckTT "ENM";
BA_ "SignalLongName" SG_ 2151268352 ClmnLckTT "Column Lock Telltale";
BA_ "VNSigAllNodes" SG_ 2151268352 ClmnLckTT 1;
BA_ "GenSigSendType" SG_ 2154659840 StrgClmnLckVisNot 10;
BA_ "SignalType" SG_ 2154659840 StrgClmnLckVisNot "BLN";
BA_ "SignalLongName" SG_ 2154659840 StrgClmnLckVisNot "Steering Column Locked Visual Notify";
BA_ "VNSigAllNodes" SG_ 2154659840 StrgClmnLckVisNot 1;
BA_ "GenSigSendType" SG_ 2154659840 UnlockRtryPshIndOn 10;
BA_ "SignalType" SG_ 2154659840 UnlockRtryPshIndOn "BLN";
BA_ "SignalLongName" SG_ 2154659840 UnlockRtryPshIndOn "Unlock Retry Push Indication On";
BA_ "VNSigAllNodes" SG_ 2154659840 UnlockRtryPshIndOn 1;
BA_ "GenSigSendType" SG_ 2154659840 UnlckRtryRotIndOn 10;
BA_ "SignalType" SG_ 2154659840 UnlckRtryRotIndOn "BLN";
BA_ "SignalLongName" SG_ 2154659840 UnlckRtryRotIndOn "Unlock Retry Rotation Indication On";
BA_ "VNSigAllNodes" SG_ 2154659840 UnlckRtryRotIndOn 1;
BA_ "GenSigSendType" SG_ 2154659840 ClmSysFlrIndOn 10;
BA_ "SignalType" SG_ 2154659840 ClmSysFlrIndOn "BLN";
BA_ "SignalLongName" SG_ 2154659840 ClmSysFlrIndOn "Column System Failure Indication On";
BA_ "VNSigAllNodes" SG_ 2154659840 ClmSysFlrIndOn 1;
BA_ "GenSigSendType" SG_ 2154659840 StrngClmnLckTT 10;
BA_ "SignalType" SG_ 2154659840 StrngClmnLckTT "ENM";
BA_ "SignalLongName" SG_ 2154659840 StrngClmnLckTT "Steering Column Lock Telltale";
BA_ "VNSigAllNodes" SG_ 2154659840 StrngClmnLckTT 1;
BA_ "GenSigSendType" SG_ 2154659840 ClmnLckStatV 10;
BA_ "SignalType" SG_ 2154659840 ClmnLckStatV "ENM";
BA_ "SignalLongName" SG_ 2154659840 ClmnLckStatV "Column Lock Status Validity";
BA_ "VNSigAllNodes" SG_ 2154659840 ClmnLckStatV 1;
BA_ "GenSigSendType" SG_ 2154659840 ClmnLckStat 10;
BA_ "GenSigSendOnInit" SG_ 2154659840 ClmnLckStat 2;
BA_ "SignalType" SG_ 2154659840 ClmnLckStat "ENM";
BA_ "SignalLongName" SG_ 2154659840 ClmnLckStat "Column Lock Status";
BA_ "VNSigAllNodes" SG_ 2154659840 ClmnLckStat 1;
BA_ "GenSigSendType" SG_ 2149974016 IntrSnsDisbld 10;
BA_ "SignalType" SG_ 2149974016 IntrSnsDisbld "BLN";
BA_ "SignalLongName" SG_ 2149974016 IntrSnsDisbld "Intrusion Sensing Disabled";
BA_ "VNSigAllNodes" SG_ 2149974016 IntrSnsDisbld 1;
BA_ "GenSigSendType" SG_ 2149974016 AlrmStat 10;
BA_ "GenSigSendOnInit" SG_ 2149974016 AlrmStat 2;
BA_ "SignalType" SG_ 2149974016 AlrmStat "ENM";
BA_ "SignalLongName" SG_ 2149974016 AlrmStat "Alarm Status";
BA_ "VNSigAllNodes" SG_ 2149974016 AlrmStat 1;
BA_ "GenSigSendType" SG_ 2149974016 AlrmTrggrdBattRcnctd 10;
BA_ "SignalType" SG_ 2149974016 AlrmTrggrdBattRcnctd "BLN";
BA_ "SignalLongName" SG_ 2149974016 AlrmTrggrdBattRcnctd "Alarm Triggered Battery Reconnected";
BA_ "VNSigAllNodes" SG_ 2149974016 AlrmTrggrdBattRcnctd 1;
BA_ "GenSigSendType" SG_ 2149974016 AlrmTrgDrvDr 10;
BA_ "SignalType" SG_ 2149974016 AlrmTrgDrvDr "BLN";
BA_ "SignalLongName" SG_ 2149974016 AlrmTrgDrvDr "Alarm Triggered Driver Door Ajar";
BA_ "VNSigAllNodes" SG_ 2149974016 AlrmTrgDrvDr 1;
BA_ "GenSigSendType" SG_ 2149974016 AlrmTrgGlsBrkSns 10;
BA_ "SignalType" SG_ 2149974016 AlrmTrgGlsBrkSns "BLN";
BA_ "SignalLongName" SG_ 2149974016 AlrmTrgGlsBrkSns "Alarm Triggered Glass Breakage Sensor";
BA_ "VNSigAllNodes" SG_ 2149974016 AlrmTrgGlsBrkSns 1;
BA_ "GenSigSendType" SG_ 2149974016 AlrmTrgHd 10;
BA_ "SignalType" SG_ 2149974016 AlrmTrgHd "BLN";
BA_ "SignalLongName" SG_ 2149974016 AlrmTrgHd "Alarm Triggered Hood Ajar";
BA_ "VNSigAllNodes" SG_ 2149974016 AlrmTrgHd 1;
BA_ "GenSigSendType" SG_ 2149974016 AlrmTrgdIO 10;
BA_ "SignalType" SG_ 2149974016 AlrmTrgdIO "BLN";
BA_ "SignalLongName" SG_ 2149974016 AlrmTrgdIO "Alarm Triggered Indication On";
BA_ "VNSigAllNodes" SG_ 2149974016 AlrmTrgdIO 1;
BA_ "GenSigSendType" SG_ 2149974016 AlrmTrgIntMvmntSns 10;
BA_ "SignalType" SG_ 2149974016 AlrmTrgIntMvmntSns "BLN";
BA_ "SignalLongName" SG_ 2149974016 AlrmTrgIntMvmntSns "Alarm Triggered Interior Movement Sensor";
BA_ "VNSigAllNodes" SG_ 2149974016 AlrmTrgIntMvmntSns 1;
BA_ "GenSigSendType" SG_ 2149974016 AlrmTrgNonOffPM 10;
BA_ "SignalType" SG_ 2149974016 AlrmTrgNonOffPM "BLN";
BA_ "SignalLongName" SG_ 2149974016 AlrmTrgNonOffPM "Alarm Triggered Non-Off Power Mode";
BA_ "VNSigAllNodes" SG_ 2149974016 AlrmTrgNonOffPM 1;
BA_ "GenSigSendType" SG_ 2149974016 AlrmTrgPsngDr 10;
BA_ "SignalType" SG_ 2149974016 AlrmTrgPsngDr "BLN";
BA_ "SignalLongName" SG_ 2149974016 AlrmTrgPsngDr "Alarm Triggered Passenger Door Ajar";
BA_ "VNSigAllNodes" SG_ 2149974016 AlrmTrgPsngDr 1;
BA_ "GenSigSendType" SG_ 2149974016 AlrmTrgRrLftDr 10;
BA_ "SignalType" SG_ 2149974016 AlrmTrgRrLftDr "BLN";
BA_ "SignalLongName" SG_ 2149974016 AlrmTrgRrLftDr "Alarm Triggered Rear Left Door Ajar";
BA_ "VNSigAllNodes" SG_ 2149974016 AlrmTrgRrLftDr 1;
BA_ "GenSigSendType" SG_ 2149974016 AlrmTrgRrRtDr 10;
BA_ "SignalType" SG_ 2149974016 AlrmTrgRrRtDr "BLN";
BA_ "SignalLongName" SG_ 2149974016 AlrmTrgRrRtDr "Alarm Triggered Rear Right Door Ajar";
BA_ "VNSigAllNodes" SG_ 2149974016 AlrmTrgRrRtDr 1;
BA_ "GenSigSendType" SG_ 2149974016 AlrmTrgTltSns 10;
BA_ "SignalType" SG_ 2149974016 AlrmTrgTltSns "BLN";
BA_ "SignalLongName" SG_ 2149974016 AlrmTrgTltSns "Alarm Triggered Tilt Sensor";
BA_ "VNSigAllNodes" SG_ 2149974016 AlrmTrgTltSns 1;
BA_ "GenSigSendType" SG_ 2149974016 AlrmTrgTrnk 10;
BA_ "SignalType" SG_ 2149974016 AlrmTrgTrnk "BLN";
BA_ "SignalLongName" SG_ 2149974016 AlrmTrgTrnk "Alarm Triggered Trunk Ajar";
BA_ "VNSigAllNodes" SG_ 2149974016 AlrmTrgTrnk 1;
BA_ "GenSigSendType" SG_ 2149974016 SrvAlrmSysIO 10;
BA_ "SignalType" SG_ 2149974016 SrvAlrmSysIO "BLN";
BA_ "SignalLongName" SG_ 2149974016 SrvAlrmSysIO "Service Alarm System Indication On";
BA_ "VNSigAllNodes" SG_ 2149974016 SrvAlrmSysIO 1;
BA_ "GenSigSendType" SG_ 2149974016 AlrmTrigMidClsr 10;
BA_ "SignalType" SG_ 2149974016 AlrmTrigMidClsr "BLN";
BA_ "SignalLongName" SG_ 2149974016 AlrmTrigMidClsr "Alarm Triggered Mid Closure";
BA_ "VNSigAllNodes" SG_ 2149974016 AlrmTrigMidClsr 1;
BA_ "GenSigSendType" SG_ 2149974016 AlrmTrigTonn 10;
BA_ "SignalType" SG_ 2149974016 AlrmTrigTonn "BLN";
BA_ "SignalLongName" SG_ 2149974016 AlrmTrigTonn "Alarm Triggered Tonneau";
BA_ "VNSigAllNodes" SG_ 2149974016 AlrmTrigTonn 1;
BA_ "SignalType" SG_ 2155929600 DslExhFldDiagWrnIdRq "ENM";
BA_ "SignalLongName" SG_ 2155929600 DslExhFldDiagWrnIdRq "Diesel Exhaust Fluid System Diagnostic Warning Indication Request";
BA_ "VNSigAllNodes" SG_ 2155929600 DslExhFldDiagWrnIdRq 1;
BA_ "SignalType" SG_ 2155929600 DslExhFluidDistTIndcmt "UNM";
BA_ "SignalLongName" SG_ 2155929600 DslExhFluidDistTIndcmt "Diesel Exhaust Fluid Distance to Inducement";
BA_ "VNSigAllNodes" SG_ 2155929600 DslExhFluidDistTIndcmt 1;
BA_ "SignalType" SG_ 2155929600 DEFWVSL_S3SpdLmt "UNM";
BA_ "PacketOrder" SG_ 2155929600 DEFWVSL_S3SpdLmt 3;
BA_ "SignalLongName" SG_ 2155929600 DEFWVSL_S3SpdLmt "Diesel Exhaust Fluid Warning Vehicle Speed Limit : Stage 3 Vehicle Speed Limit";
BA_ "VNSigAllNodes" SG_ 2155929600 DEFWVSL_S3SpdLmt 1;
BA_ "SignalType" SG_ 2155929600 DEFWVSL_S2SpdLmt "UNM";
BA_ "PacketOrder" SG_ 2155929600 DEFWVSL_S2SpdLmt 2;
BA_ "SignalLongName" SG_ 2155929600 DEFWVSL_S2SpdLmt "Diesel Exhaust Fluid Warning Vehicle Speed Limit : Stage 2 Vehicle Speed Limit";
BA_ "VNSigAllNodes" SG_ 2155929600 DEFWVSL_S2SpdLmt 1;
BA_ "SignalType" SG_ 2155929600 DEFWVSL_S1SpdLmt "UNM";
BA_ "PacketOrder" SG_ 2155929600 DEFWVSL_S1SpdLmt 1;
BA_ "SignalLongName" SG_ 2155929600 DEFWVSL_S1SpdLmt "Diesel Exhaust Fluid Warning Vehicle Speed Limit : Stage 1 Vehicle Speed Limit";
BA_ "VNSigAllNodes" SG_ 2155929600 DEFWVSL_S1SpdLmt 1;
BA_ "SignalType" SG_ 2155929600 DslExFldTpWrngIndRq "ENM";
BA_ "SignalLongName" SG_ 2155929600 DslExFldTpWrngIndRq "Diesel Exhaust Fluid Tampering Warning Indication Request";
BA_ "VNSigAllNodes" SG_ 2155929600 DslExFldTpWrngIndRq 1;
BA_ "SignalType" SG_ 2155929600 DslExhFldQlyWrngIReq "ENM";
BA_ "SignalLongName" SG_ 2155929600 DslExhFldQlyWrngIReq "Diesel Exhaust Fluid Quality Warning Indication Request";
BA_ "VNSigAllNodes" SG_ 2155929600 DslExhFldQlyWrngIReq 1;
BA_ "SignalType" SG_ 2155929600 DslExhFldWrngIdRqER "ENM";
BA_ "SignalLongName" SG_ 2155929600 DslExhFldWrngIdRqER "Diesel Exhaust Fluid Level Warning Indication Request Extended Range";
BA_ "VNSigAllNodes" SG_ 2155929600 DslExhFldWrngIdRqER 1;
BA_ "SignalType" SG_ 2155929600 DslExFldCnWrngIndRq "ENM";
BA_ "SignalLongName" SG_ 2155929600 DslExFldCnWrngIndRq "Diesel Exhaust Fluid Consumption Monitoring Warning Indication Request";
BA_ "VNSigAllNodes" SG_ 2155929600 DslExFldCnWrngIndRq 1;
BA_ "SignalType" SG_ 2155929600 DslExNxEmWrngIndRq "ENM";
BA_ "SignalLongName" SG_ 2155929600 DslExNxEmWrngIndRq "Diesel Exhaust NOx Emissions Too High Warning Indication Request";
BA_ "VNSigAllNodes" SG_ 2155929600 DslExNxEmWrngIndRq 1;
BA_ "GenSigSendType" SG_ 2153807872 PsvStrtStrngClmnLckTT 10;
BA_ "SignalType" SG_ 2153807872 PsvStrtStrngClmnLckTT "ENM";
BA_ "SignalLongName" SG_ 2153807872 PsvStrtStrngClmnLckTT "Passive Start Steering Column Lock Telltale";
BA_ "VNSigAllNodes" SG_ 2153807872 PsvStrtStrngClmnLckTT 1;
BA_ "GenSigSendType" SG_ 2153807872 ClmSysAuxFlrIndOn 10;
BA_ "SignalType" SG_ 2153807872 ClmSysAuxFlrIndOn "BLN";
BA_ "SignalLongName" SG_ 2153807872 ClmSysAuxFlrIndOn "Column System Auxiliary Failure Indication On";
BA_ "VNSigAllNodes" SG_ 2153807872 ClmSysAuxFlrIndOn 1;
BA_ "GenSigSendType" SG_ 2153807872 PsDoorOpenSwActV 10;
BA_ "SignalType" SG_ 2153807872 PsDoorOpenSwActV "ENM";
BA_ "SignalLongName" SG_ 2153807872 PsDoorOpenSwActV "Passenger Door Open Switch Active Validity";
BA_ "VNSigAllNodes" SG_ 2153807872 PsDoorOpenSwActV 1;
BA_ "GenSigSendType" SG_ 2153807872 PsDoorOpenSwAct 10;
BA_ "GenSigSendOnInit" SG_ 2153807872 PsDoorOpenSwAct 1;
BA_ "SignalType" SG_ 2153807872 PsDoorOpenSwAct "BLN";
BA_ "SignalLongName" SG_ 2153807872 PsDoorOpenSwAct "Passenger Door Open Switch Active";
BA_ "VNSigAllNodes" SG_ 2153807872 PsDoorOpenSwAct 1;
BA_ "GenSigSendType" SG_ 2153807872 DrDoorOpenSwActV 10;
BA_ "SignalType" SG_ 2153807872 DrDoorOpenSwActV "ENM";
BA_ "SignalLongName" SG_ 2153807872 DrDoorOpenSwActV "Driver Door Open Switch Active Validity";
BA_ "VNSigAllNodes" SG_ 2153807872 DrDoorOpenSwActV 1;
BA_ "GenSigSendType" SG_ 2153807872 DrDoorOpenSwAct 10;
BA_ "GenSigSendOnInit" SG_ 2153807872 DrDoorOpenSwAct 1;
BA_ "SignalType" SG_ 2153807872 DrDoorOpenSwAct "BLN";
BA_ "SignalLongName" SG_ 2153807872 DrDoorOpenSwAct "Driver Door Open Switch Active";
BA_ "VNSigAllNodes" SG_ 2153807872 DrDoorOpenSwAct 1;
BA_ "GenSigSendType" SG_ 2154938368 FobProgMdStat 10;
BA_ "SignalType" SG_ 2154938368 FobProgMdStat "ENM";
BA_ "SignalLongName" SG_ 2154938368 FobProgMdStat "Fob Programming Mode Status";
BA_ "VNSigAllNodes" SG_ 2154938368 FobProgMdStat 1;
BA_ "GenSigSendType" SG_ 2151751680 HptcStVbnStat 10;
BA_ "SignalType" SG_ 2151751680 HptcStVbnStat "ENM";
BA_ "SignalLongName" SG_ 2151751680 HptcStVbnStat "Haptic Seat Vibration Status";
BA_ "VNSigAllNodes" SG_ 2151751680 HptcStVbnStat 1;
BA_ "GenSigSendType" SG_ 2151751680 HptcStFldIO 10;
BA_ "SignalType" SG_ 2151751680 HptcStFldIO "BLN";
BA_ "SignalLongName" SG_ 2151751680 HptcStFldIO "Haptic Seat Failed Indication On";
BA_ "VNSigAllNodes" SG_ 2151751680 HptcStFldIO 1;
BA_ "GenSigSendType" SG_ 2151751680 CrshAlrtDrvrSlctdType 10;
BA_ "GenSigSendOnInit" SG_ 2151751680 CrshAlrtDrvrSlctdType 1;
BA_ "SignalType" SG_ 2151751680 CrshAlrtDrvrSlctdType "ENM";
BA_ "SignalLongName" SG_ 2151751680 CrshAlrtDrvrSlctdType "Crash Alert Driver Selected Type";
BA_ "VNSigAllNodes" SG_ 2151751680 CrshAlrtDrvrSlctdType 1;
BA_ "GenSigSendType" SG_ 2151751680 CrshAlrtStPrsnt 10;
BA_ "GenSigSendOnInit" SG_ 2151751680 CrshAlrtStPrsnt 1;
BA_ "SignalType" SG_ 2151751680 CrshAlrtStPrsnt "BLN";
BA_ "SignalLongName" SG_ 2151751680 CrshAlrtStPrsnt "Crash Alert Seat Present";
BA_ "VNSigAllNodes" SG_ 2151751680 CrshAlrtStPrsnt 1;
BA_ "GenSigSendType" SG_ 2152464384 RtLnDepWrnSt 10;
BA_ "SignalType" SG_ 2152464384 RtLnDepWrnSt "ENM";
BA_ "SignalLongName" SG_ 2152464384 RtLnDepWrnSt "Right Lane Departure Warning Status";
BA_ "VNSigAllNodes" SG_ 2152464384 RtLnDepWrnSt 1;
BA_ "GenSigSendType" SG_ 2152464384 LftLnDepWrnSt 10;
BA_ "SignalType" SG_ 2152464384 LftLnDepWrnSt "ENM";
BA_ "SignalLongName" SG_ 2152464384 LftLnDepWrnSt "Left Lane Departure Warning Status";
BA_ "VNSigAllNodes" SG_ 2152464384 LftLnDepWrnSt 1;
BA_ "GenSigSendType" SG_ 2152464384 TnDrvLDWOffUnbIO 10;
BA_ "SignalType" SG_ 2152464384 TnDrvLDWOffUnbIO "BLN";
BA_ "SignalLongName" SG_ 2152464384 TnDrvLDWOffUnbIO "Teen Driver Lane Departure Warning Off Unavailable Indication On";
BA_ "VNSigAllNodes" SG_ 2152464384 TnDrvLDWOffUnbIO 1;
BA_ "GenSigSendType" SG_ 2152464384 SrvcLnKpAstSysIO 10;
BA_ "SignalType" SG_ 2152464384 SrvcLnKpAstSysIO "BLN";
BA_ "SignalLongName" SG_ 2152464384 SrvcLnKpAstSysIO "Service Lane Keeping Assist System Indication On";
BA_ "VNSigAllNodes" SG_ 2152464384 SrvcLnKpAstSysIO 1;
BA_ "GenSigSendType" SG_ 2152464384 HndsOffStrWhlDtIO 10;
BA_ "SignalType" SG_ 2152464384 HndsOffStrWhlDtIO "BLN";
BA_ "SignalLongName" SG_ 2152464384 HndsOffStrWhlDtIO "Hands Off Steering Wheel Detection Indication On";
BA_ "VNSigAllNodes" SG_ 2152464384 HndsOffStrWhlDtIO 1;
BA_ "GenSigSendType" SG_ 2152464384 LnKpAstDisbldIO 10;
BA_ "SignalType" SG_ 2152464384 LnKpAstDisbldIO "BLN";
BA_ "SignalLongName" SG_ 2152464384 LnKpAstDisbldIO "Lane Keeping Assist Disabled Indication On";
BA_ "VNSigAllNodes" SG_ 2152464384 LnKpAstDisbldIO 1;
BA_ "GenSigSendType" SG_ 2152464384 LKAIC_AdbWngLn 10;
BA_ "SignalType" SG_ 2152464384 LKAIC_AdbWngLn "ENM";
BA_ "PacketOrder" SG_ 2152464384 LKAIC_AdbWngLn 4;
BA_ "SignalLongName" SG_ 2152464384 LKAIC_AdbWngLn "Lane Keeping Assist Indication Control : Audible Warning Location";
BA_ "VNSigAllNodes" SG_ 2152464384 LKAIC_AdbWngLn 1;
BA_ "GenSigSendType" SG_ 2152464384 LKAIC_Ind2 10;
BA_ "SignalType" SG_ 2152464384 LKAIC_Ind2 "BLN";
BA_ "PacketOrder" SG_ 2152464384 LKAIC_Ind2 3;
BA_ "SignalLongName" SG_ 2152464384 LKAIC_Ind2 "Lane Keeping Assist Indication Control : Indicator 2";
BA_ "VNSigAllNodes" SG_ 2152464384 LKAIC_Ind2 1;
BA_ "GenSigSendType" SG_ 2152464384 LKAIC_Ind1 10;
BA_ "SignalType" SG_ 2152464384 LKAIC_Ind1 "BLN";
BA_ "PacketOrder" SG_ 2152464384 LKAIC_Ind1 2;
BA_ "SignalLongName" SG_ 2152464384 LKAIC_Ind1 "Lane Keeping Assist Indication Control : Indicator 1";
BA_ "VNSigAllNodes" SG_ 2152464384 LKAIC_Ind1 1;
BA_ "GenSigSendType" SG_ 2152464384 LKAIC_IndReq 10;
BA_ "SignalType" SG_ 2152464384 LKAIC_IndReq "ENM";
BA_ "PacketOrder" SG_ 2152464384 LKAIC_IndReq 1;
BA_ "SignalLongName" SG_ 2152464384 LKAIC_IndReq "Lane Keeping Assist Indication Control : Indication Request";
BA_ "VNSigAllNodes" SG_ 2152464384 LKAIC_IndReq 1;
BA_ "GenSigSendType" SG_ 2152464384 SrvcLaneDepWrnSysIO 10;
BA_ "SignalType" SG_ 2152464384 SrvcLaneDepWrnSysIO "BLN";
BA_ "SignalLongName" SG_ 2152464384 SrvcLaneDepWrnSysIO "Service Lane Departure Warning System Indication On";
BA_ "VNSigAllNodes" SG_ 2152464384 SrvcLaneDepWrnSysIO 1;
BA_ "GenSigSendType" SG_ 2152464384 LDWIC_LnDepWAWLn 10;
BA_ "GenSigSendOnInit" SG_ 2152464384 LDWIC_LnDepWAWLn 2;
BA_ "SignalType" SG_ 2152464384 LDWIC_LnDepWAWLn "ENM";
BA_ "PacketOrder" SG_ 2152464384 LDWIC_LnDepWAWLn 4;
BA_ "SignalLongName" SG_ 2152464384 LDWIC_LnDepWAWLn "Lane Departure Warning Indication Control : Lane Deparature Warning Audible Warning Location";
BA_ "VNSigAllNodes" SG_ 2152464384 LDWIC_LnDepWAWLn 1;
BA_ "GenSigSendType" SG_ 2152464384 LDWIC_Ind2 10;
BA_ "GenSigSendOnInit" SG_ 2152464384 LDWIC_Ind2 2;
BA_ "SignalType" SG_ 2152464384 LDWIC_Ind2 "BLN";
BA_ "PacketOrder" SG_ 2152464384 LDWIC_Ind2 3;
BA_ "SignalLongName" SG_ 2152464384 LDWIC_Ind2 "Lane Departure Warning Indication Control : Indicator 2";
BA_ "VNSigAllNodes" SG_ 2152464384 LDWIC_Ind2 1;
BA_ "GenSigSendType" SG_ 2152464384 LDWIC_Ind1 10;
BA_ "GenSigSendOnInit" SG_ 2152464384 LDWIC_Ind1 2;
BA_ "SignalType" SG_ 2152464384 LDWIC_Ind1 "BLN";
BA_ "PacketOrder" SG_ 2152464384 LDWIC_Ind1 2;
BA_ "SignalLongName" SG_ 2152464384 LDWIC_Ind1 "Lane Departure Warning Indication Control : Indicator 1";
BA_ "VNSigAllNodes" SG_ 2152464384 LDWIC_Ind1 1;
BA_ "GenSigSendType" SG_ 2152464384 LDWIC_IndReq 10;
BA_ "GenSigSendOnInit" SG_ 2152464384 LDWIC_IndReq 2;
BA_ "SignalType" SG_ 2152464384 LDWIC_IndReq "ENM";
BA_ "PacketOrder" SG_ 2152464384 LDWIC_IndReq 1;
BA_ "SignalLongName" SG_ 2152464384 LDWIC_IndReq "Lane Departure Warning Indication Control : Indication Request";
BA_ "VNSigAllNodes" SG_ 2152464384 LDWIC_IndReq 1;
BA_ "GenSigSendType" SG_ 2152464384 LaneDepWrnDisbldIO 10;
BA_ "SignalType" SG_ 2152464384 LaneDepWrnDisbldIO "BLN";
BA_ "SignalLongName" SG_ 2152464384 LaneDepWrnDisbldIO "Lane Departure Warning Disabled Indication On";
BA_ "VNSigAllNodes" SG_ 2152464384 LaneDepWrnDisbldIO 1;
BA_ "GenSigSendType" SG_ 2151342080 PrkAstRtSysStat 10;
BA_ "SignalType" SG_ 2151342080 PrkAstRtSysStat "ENM";
BA_ "SignalLongName" SG_ 2151342080 PrkAstRtSysStat "Parking Assistance Right System Status";
BA_ "VNSigAllNodes" SG_ 2151342080 PrkAstRtSysStat 1;
BA_ "GenSigSendType" SG_ 2151342080 PARtRgn3ObjStat 10;
BA_ "SignalType" SG_ 2151342080 PARtRgn3ObjStat "ENM";
BA_ "SignalLongName" SG_ 2151342080 PARtRgn3ObjStat "Parking Assistance Right Region 3 Object Status";
BA_ "VNSigAllNodes" SG_ 2151342080 PARtRgn3ObjStat 1;
BA_ "GenSigSendType" SG_ 2151342080 PARtRgn2ObjStat 10;
BA_ "SignalType" SG_ 2151342080 PARtRgn2ObjStat "ENM";
BA_ "SignalLongName" SG_ 2151342080 PARtRgn2ObjStat "Parking Assistance Right Region 2 Object Status";
BA_ "VNSigAllNodes" SG_ 2151342080 PARtRgn2ObjStat 1;
BA_ "GenSigSendType" SG_ 2151342080 PARtRgn1ObjStat 10;
BA_ "SignalType" SG_ 2151342080 PARtRgn1ObjStat "ENM";
BA_ "SignalLongName" SG_ 2151342080 PARtRgn1ObjStat "Parking Assistance Right Region 1 Object Status";
BA_ "VNSigAllNodes" SG_ 2151342080 PARtRgn1ObjStat 1;
BA_ "GenSigSendType" SG_ 2151325696 PrkAstLtSysStat 10;
BA_ "SignalType" SG_ 2151325696 PrkAstLtSysStat "ENM";
BA_ "SignalLongName" SG_ 2151325696 PrkAstLtSysStat "Parking Assistance Left System Status";
BA_ "VNSigAllNodes" SG_ 2151325696 PrkAstLtSysStat 1;
BA_ "GenSigSendType" SG_ 2151325696 PALtRgn3ObjStat 10;
BA_ "SignalType" SG_ 2151325696 PALtRgn3ObjStat "ENM";
BA_ "SignalLongName" SG_ 2151325696 PALtRgn3ObjStat "Parking Assistance Left Region 3 Object Status";
BA_ "VNSigAllNodes" SG_ 2151325696 PALtRgn3ObjStat 1;
BA_ "GenSigSendType" SG_ 2151325696 PALtRgn2ObjStat 10;
BA_ "SignalType" SG_ 2151325696 PALtRgn2ObjStat "ENM";
BA_ "SignalLongName" SG_ 2151325696 PALtRgn2ObjStat "Parking Assistance Left Region 2 Object Status";
BA_ "VNSigAllNodes" SG_ 2151325696 PALtRgn2ObjStat 1;
BA_ "GenSigSendType" SG_ 2151325696 PALtRgn1ObjStat 10;
BA_ "SignalType" SG_ 2151325696 PALtRgn1ObjStat "ENM";
BA_ "SignalLongName" SG_ 2151325696 PALtRgn1ObjStat "Parking Assistance Left Region 1 Object Status";
BA_ "VNSigAllNodes" SG_ 2151325696 PALtRgn1ObjStat 1;
BA_ "GenSigSendType" SG_ 2150137856 LMTTCPrsnOffStat 10;
BA_ "SignalType" SG_ 2150137856 LMTTCPrsnOffStat "BLN";
BA_ "SignalLongName" SG_ 2150137856 LMTTCPrsnOffStat "Lead Me To The Car Personalization Off Status";
BA_ "VNSigAllNodes" SG_ 2150137856 LMTTCPrsnOffStat 1;
BA_ "GenSigSendType" SG_ 2150137856 FldTpMotReq 10;
BA_ "SignalType" SG_ 2150137856 FldTpMotReq "ENM";
BA_ "SignalLongName" SG_ 2150137856 FldTpMotReq "Folding Top Motion Request";
BA_ "VNSigAllNodes" SG_ 2150137856 FldTpMotReq 1;
BA_ "GenSigSendType" SG_ 2150137856 KeyInWrnIO 10;
BA_ "GenSigSendOnInit" SG_ 2150137856 KeyInWrnIO 2;
BA_ "SignalType" SG_ 2150137856 KeyInWrnIO "BLN";
BA_ "SignalLongName" SG_ 2150137856 KeyInWrnIO "Key In Warning Indication On";
BA_ "VNSigAllNodes" SG_ 2150137856 KeyInWrnIO 1;
BA_ "GenSigSendType" SG_ 2150137856 FobPrevLrndIndOn 10;
BA_ "SignalType" SG_ 2150137856 FobPrevLrndIndOn "BLN";
BA_ "SignalLongName" SG_ 2150137856 FobPrevLrndIndOn "Fob Previously Learned Indication On";
BA_ "VNSigAllNodes" SG_ 2150137856 FobPrevLrndIndOn 1;
BA_ "GenSigSendType" SG_ 2150137856 RemCtrlFobNumForProgER 10;
BA_ "SignalType" SG_ 2150137856 RemCtrlFobNumForProgER "ENM";
BA_ "SignalLongName" SG_ 2150137856 RemCtrlFobNumForProgER "Remote Control Fob Number For Programming Extended Range";
BA_ "VNSigAllNodes" SG_ 2150137856 RemCtrlFobNumForProgER 1;
BA_ "GenSigSendType" SG_ 2150137856 FbProgCustActRqd 10;
BA_ "SignalType" SG_ 2150137856 FbProgCustActRqd "BLN";
BA_ "SignalLongName" SG_ 2150137856 FbProgCustActRqd "Fob Programming Customer Action Required";
BA_ "VNSigAllNodes" SG_ 2150137856 FbProgCustActRqd 1;
BA_ "GenSigSendType" SG_ 2150137856 Ky_IdDevNotPrIO 10;
BA_ "GenSigSendOnInit" SG_ 2150137856 Ky_IdDevNotPrIO 2;
BA_ "SignalType" SG_ 2150137856 Ky_IdDevNotPrIO "BLN";
BA_ "SignalLongName" SG_ 2150137856 Ky_IdDevNotPrIO "Key/Identification Device Not Present Indication On";
BA_ "VNSigAllNodes" SG_ 2150137856 Ky_IdDevNotPrIO 1;
BA_ "GenSigDeltaValue" SG_ 2150137856 VehSecAtoLrnDlyTmr 1;
BA_ "GenSigSendType" SG_ 2150137856 VehSecAtoLrnDlyTmr 12;
BA_ "SignalType" SG_ 2150137856 VehSecAtoLrnDlyTmr "UNM";
BA_ "SignalLongName" SG_ 2150137856 VehSecAtoLrnDlyTmr "Vehicle Security Auto Learn Delay Timer";
BA_ "VNSigAllNodes" SG_ 2150137856 VehSecAtoLrnDlyTmr 1;
BA_ "GenSigSendType" SG_ 2150137856 VehSecAtoLrnAtv 10;
BA_ "SignalType" SG_ 2150137856 VehSecAtoLrnAtv "BLN";
BA_ "SignalLongName" SG_ 2150137856 VehSecAtoLrnAtv "Vehicle Security Auto Learn Active";
BA_ "VNSigAllNodes" SG_ 2150137856 VehSecAtoLrnAtv 1;
BA_ "GenSigSendType" SG_ 2150137856 Ky_IdDevPrgmAuthReq 10;
BA_ "SignalType" SG_ 2150137856 Ky_IdDevPrgmAuthReq "BLN";
BA_ "SignalLongName" SG_ 2150137856 Ky_IdDevPrgmAuthReq "Key / Identification Device Programming Authentication Requested";
BA_ "VNSigAllNodes" SG_ 2150137856 Ky_IdDevPrgmAuthReq 1;
BA_ "GenSigDeltaValue" SG_ 2155003904 LfLnChngThrtAprchSpd 1;
BA_ "GenSigSendType" SG_ 2155003904 LfLnChngThrtAprchSpd 12;
BA_ "SignalType" SG_ 2155003904 LfLnChngThrtAprchSpd "SNM";
BA_ "SignalLongName" SG_ 2155003904 LfLnChngThrtAprchSpd "Left Lane Change Threat Approach Speed";
BA_ "VNSigAllNodes" SG_ 2155003904 LfLnChngThrtAprchSpd 1;
BA_ "GenSigSendType" SG_ 2155003904 LftLnChgThrt 10;
BA_ "SignalType" SG_ 2155003904 LftLnChgThrt "BLN";
BA_ "SignalLongName" SG_ 2155003904 LftLnChgThrt "Left Lane Change Threat";
BA_ "VNSigAllNodes" SG_ 2155003904 LftLnChgThrt 1;
BA_ "GenSigSendType" SG_ 2155003904 SBZATmpUnvIndOn 10;
BA_ "SignalType" SG_ 2155003904 SBZATmpUnvIndOn "BLN";
BA_ "SignalLongName" SG_ 2155003904 SBZATmpUnvIndOn "Side Blind Zone Alert Temporarily Unavailable Indication On";
BA_ "VNSigAllNodes" SG_ 2155003904 SBZATmpUnvIndOn 1;
BA_ "GenSigSendType" SG_ 2155003904 SBZASysSrvIndOn 10;
BA_ "GenSigSendOnInit" SG_ 2155003904 SBZASysSrvIndOn 2;
BA_ "SignalType" SG_ 2155003904 SBZASysSrvIndOn "BLN";
BA_ "SignalLongName" SG_ 2155003904 SBZASysSrvIndOn "Side Blind Zone Alert System Service Indication On";
BA_ "VNSigAllNodes" SG_ 2155003904 SBZASysSrvIndOn 1;
BA_ "GenSigSendType" SG_ 2155003904 SBZASysOffIndOn 10;
BA_ "SignalType" SG_ 2155003904 SBZASysOffIndOn "BLN";
BA_ "SignalLongName" SG_ 2155003904 SBZASysOffIndOn "Side Blind Zone Alert System Off Indication On";
BA_ "VNSigAllNodes" SG_ 2155003904 SBZASysOffIndOn 1;
BA_ "GenSigSendType" SG_ 2155003904 SBZASysClnIndOn 10;
BA_ "SignalType" SG_ 2155003904 SBZASysClnIndOn "BLN";
BA_ "SignalLongName" SG_ 2155003904 SBZASysClnIndOn "Side Blind Zone Alert System Clean Indication On";
BA_ "VNSigAllNodes" SG_ 2155003904 SBZASysClnIndOn 1;
BA_ "GenSigDeltaValue" SG_ 2150662144 EnvIdRsp3 1;
BA_ "GenSigSendType" SG_ 2150662144 EnvIdRsp3 12;
BA_ "SignalType" SG_ 2150662144 EnvIdRsp3 "UNM";
BA_ "SignalLongName" SG_ 2150662144 EnvIdRsp3 "Environment Identification Response 3";
BA_ "VNSigAllNodes" SG_ 2150662144 EnvIdRsp3 1;
BA_ "GenSigSendType" SG_ 2150662144 EnvIdRspSt3 10;
BA_ "SignalType" SG_ 2150662144 EnvIdRspSt3 "ENM";
BA_ "SignalLongName" SG_ 2150662144 EnvIdRspSt3 "Environment Identification Response Status 3";
BA_ "VNSigAllNodes" SG_ 2150662144 EnvIdRspSt3 1;
BA_ "GenSigSendOnInit" SG_ 2150367232 LrnEnvIdSt 2;
BA_ "SignalType" SG_ 2150367232 LrnEnvIdSt "ENM";
BA_ "SignalLongName" SG_ 2150367232 LrnEnvIdSt "Learn Environment Identification Status";
BA_ "VNSigAllNodes" SG_ 2150367232 LrnEnvIdSt 1;
BA_ "GenSigSendOnInit" SG_ 2150367232 LrnEnvId 2;
BA_ "SignalType" SG_ 2150367232 LrnEnvId "UNM";
BA_ "SignalLongName" SG_ 2150367232 LrnEnvId "Learn Environment Identification";
BA_ "VNSigAllNodes" SG_ 2150367232 LrnEnvId 1;
BA_ "GenSigSendOnInit" SG_ 2150367232 ImoId 2;
BA_ "SignalType" SG_ 2150367232 ImoId "UNM";
BA_ "SignalLongName" SG_ 2150367232 ImoId "Immobilizer Identifier";
BA_ "VNSigAllNodes" SG_ 2150367232 ImoId 1;
BA_ "GenSigSendOnInit" SG_ 2150367232 ImoIdSt 2;
BA_ "SignalType" SG_ 2150367232 ImoIdSt "ENM";
BA_ "SignalLongName" SG_ 2150367232 ImoIdSt "Immobilizer Identifier Status";
BA_ "VNSigAllNodes" SG_ 2150367232 ImoIdSt 1;
BA_ "GenSigSendType" SG_ 2151522304 BrkPdLfSysDrvrRq 10;
BA_ "GenSigSendOnInit" SG_ 2151522304 BrkPdLfSysDrvrRq 1;
BA_ "SignalType" SG_ 2151522304 BrkPdLfSysDrvrRq "ENM";
BA_ "SignalLongName" SG_ 2151522304 BrkPdLfSysDrvrRq "Brake Pad Life System Driver Request";
BA_ "VNSigAllNodes" SG_ 2151522304 BrkPdLfSysDrvrRq 1;
BA_ "GenSigSendType" SG_ 2151522304 LnchCtrlRelLnLockReqd 10;
BA_ "SignalType" SG_ 2151522304 LnchCtrlRelLnLockReqd "BLN";
BA_ "SignalLongName" SG_ 2151522304 LnchCtrlRelLnLockReqd "Launch Control Release Line Lock Requested";
BA_ "VNSigAllNodes" SG_ 2151522304 LnchCtrlRelLnLockReqd 1;
BA_ "GenSigSendType" SG_ 2151522304 TCSTmpDsblReqConf 10;
BA_ "SignalType" SG_ 2151522304 TCSTmpDsblReqConf "ENM";
BA_ "SignalLongName" SG_ 2151522304 TCSTmpDsblReqConf "Traction Control System Temporary Disable Request Confirmation";
BA_ "VNSigAllNodes" SG_ 2151522304 TCSTmpDsblReqConf 1;
BA_ "GenSigSendType" SG_ 2151522304 ElEngyEconAvgRstRq 10;
BA_ "SignalType" SG_ 2151522304 ElEngyEconAvgRstRq "BLN";
BA_ "SignalLongName" SG_ 2151522304 ElEngyEconAvgRstRq "Electrical Energy Economy Average Reset Requested";
BA_ "VNSigAllNodes" SG_ 2151522304 ElEngyEconAvgRstRq 1;
BA_ "GenSigSendType" SG_ 2151522304 FuelFltLfRstRqd 10;
BA_ "GenSigSendOnInit" SG_ 2151522304 FuelFltLfRstRqd 1;
BA_ "SignalType" SG_ 2151522304 FuelFltLfRstRqd "BLN";
BA_ "SignalLongName" SG_ 2151522304 FuelFltLfRstRqd "Fuel Filter Life Reset Requested";
BA_ "VNSigAllNodes" SG_ 2151522304 FuelFltLfRstRqd 1;
BA_ "GenSigSendType" SG_ 2153791488 ArtcldRngBrdSt 10;
BA_ "GenSigSendOnInit" SG_ 2153791488 ArtcldRngBrdSt 1;
BA_ "SignalType" SG_ 2153791488 ArtcldRngBrdSt "ENM";
BA_ "SignalLongName" SG_ 2153791488 ArtcldRngBrdSt "Articulated Running Board State";
BA_ "VNSigAllNodes" SG_ 2153791488 ArtcldRngBrdSt 1;
BA_ "GenSigSendType" SG_ 2150449152 ESPDrvrExtIO 10;
BA_ "SignalType" SG_ 2150449152 ESPDrvrExtIO "BLN";
BA_ "SignalLongName" SG_ 2150449152 ESPDrvrExtIO "Electronic Shift Primary Driver Exit Indication On";
BA_ "VNSigAllNodes" SG_ 2150449152 ESPDrvrExtIO 1;
BA_ "GenSigSendType" SG_ 2150449152 ESPDrvrDrStIndtrmntIO 10;
BA_ "SignalType" SG_ 2150449152 ESPDrvrDrStIndtrmntIO "BLN";
BA_ "SignalLongName" SG_ 2150449152 ESPDrvrDrStIndtrmntIO "Electronic Shift Primary Driver Door State Indeterminate Indication On";
BA_ "VNSigAllNodes" SG_ 2150449152 ESPDrvrDrStIndtrmntIO 1;
BA_ "GenSigSendType" SG_ 2150449152 ESPAutoPrkIO 10;
BA_ "SignalType" SG_ 2150449152 ESPAutoPrkIO "BLN";
BA_ "SignalLongName" SG_ 2150449152 ESPAutoPrkIO "Electronic Shift Primary Auto Park Indication On";
BA_ "VNSigAllNodes" SG_ 2150449152 ESPAutoPrkIO 1;
BA_ "GenSigSendType" SG_ 2150449152 ManTransIndReq 10;
BA_ "SignalType" SG_ 2150449152 ManTransIndReq "ENM";
BA_ "SignalLongName" SG_ 2150449152 ManTransIndReq "Manual Transmission Indication Request";
BA_ "VNSigAllNodes" SG_ 2150449152 ManTransIndReq 1;
BA_ "GenSigSendType" SG_ 2150449152 SrvcFlSysPrkInOpnArIO 10;
BA_ "SignalType" SG_ 2150449152 SrvcFlSysPrkInOpnArIO "BLN";
BA_ "SignalLongName" SG_ 2150449152 SrvcFlSysPrkInOpnArIO "Service Fuel System Park In Open Area Indication On";
BA_ "VNSigAllNodes" SG_ 2150449152 SrvcFlSysPrkInOpnArIO 1;
BA_ "GenSigSendType" SG_ 2150449152 TnDrvStblCtrlOffUnbIO 10;
BA_ "SignalType" SG_ 2150449152 TnDrvStblCtrlOffUnbIO "BLN";
BA_ "SignalLongName" SG_ 2150449152 TnDrvStblCtrlOffUnbIO "Teen Driver Stability Control Off Unavailable Indication On";
BA_ "VNSigAllNodes" SG_ 2150449152 TnDrvStblCtrlOffUnbIO 1;
BA_ "GenSigSendType" SG_ 2150449152 TnDrvTrCtrlOffUnbIO 10;
BA_ "SignalType" SG_ 2150449152 TnDrvTrCtrlOffUnbIO "BLN";
BA_ "SignalLongName" SG_ 2150449152 TnDrvTrCtrlOffUnbIO "Teen Driver Traction Control Off Unavailable Indication On";
BA_ "VNSigAllNodes" SG_ 2150449152 TnDrvTrCtrlOffUnbIO 1;
BA_ "GenSigSendType" SG_ 2150449152 ASIRI_Indication08 10;
BA_ "SignalType" SG_ 2150449152 ASIRI_Indication08 "BLN";
BA_ "PacketOrder" SG_ 2150449152 ASIRI_Indication08 8;
BA_ "SignalLongName" SG_ 2150449152 ASIRI_Indication08 "Auto Stop Inhibit Reason Indication : Indication 8";
BA_ "VNSigAllNodes" SG_ 2150449152 ASIRI_Indication08 1;
BA_ "GenSigSendType" SG_ 2150449152 ASIRI_Indication07 10;
BA_ "SignalType" SG_ 2150449152 ASIRI_Indication07 "BLN";
BA_ "PacketOrder" SG_ 2150449152 ASIRI_Indication07 7;
BA_ "SignalLongName" SG_ 2150449152 ASIRI_Indication07 "Auto Stop Inhibit Reason Indication : Indication 7";
BA_ "VNSigAllNodes" SG_ 2150449152 ASIRI_Indication07 1;
BA_ "GenSigSendType" SG_ 2150449152 ASIRI_Indication06 10;
BA_ "SignalType" SG_ 2150449152 ASIRI_Indication06 "BLN";
BA_ "PacketOrder" SG_ 2150449152 ASIRI_Indication06 6;
BA_ "SignalLongName" SG_ 2150449152 ASIRI_Indication06 "Auto Stop Inhibit Reason Indication : Indication 6";
BA_ "VNSigAllNodes" SG_ 2150449152 ASIRI_Indication06 1;
BA_ "GenSigSendType" SG_ 2150449152 ASIRI_Indication05 10;
BA_ "SignalType" SG_ 2150449152 ASIRI_Indication05 "BLN";
BA_ "PacketOrder" SG_ 2150449152 ASIRI_Indication05 5;
BA_ "SignalLongName" SG_ 2150449152 ASIRI_Indication05 "Auto Stop Inhibit Reason Indication : Indication 5";
BA_ "VNSigAllNodes" SG_ 2150449152 ASIRI_Indication05 1;
BA_ "GenSigSendType" SG_ 2150449152 ASIRI_Indication04 10;
BA_ "SignalType" SG_ 2150449152 ASIRI_Indication04 "BLN";
BA_ "PacketOrder" SG_ 2150449152 ASIRI_Indication04 4;
BA_ "SignalLongName" SG_ 2150449152 ASIRI_Indication04 "Auto Stop Inhibit Reason Indication : Indication 4";
BA_ "VNSigAllNodes" SG_ 2150449152 ASIRI_Indication04 1;
BA_ "GenSigSendType" SG_ 2150449152 ASIRI_Indication03 10;
BA_ "SignalType" SG_ 2150449152 ASIRI_Indication03 "BLN";
BA_ "PacketOrder" SG_ 2150449152 ASIRI_Indication03 3;
BA_ "SignalLongName" SG_ 2150449152 ASIRI_Indication03 "Auto Stop Inhibit Reason Indication : Indication 3";
BA_ "VNSigAllNodes" SG_ 2150449152 ASIRI_Indication03 1;
BA_ "GenSigSendType" SG_ 2150449152 ASIRI_Indication02 10;
BA_ "SignalType" SG_ 2150449152 ASIRI_Indication02 "BLN";
BA_ "PacketOrder" SG_ 2150449152 ASIRI_Indication02 2;
BA_ "SignalLongName" SG_ 2150449152 ASIRI_Indication02 "Auto Stop Inhibit Reason Indication : Indication 2";
BA_ "VNSigAllNodes" SG_ 2150449152 ASIRI_Indication02 1;
BA_ "GenSigSendType" SG_ 2150449152 ASIRI_Indication01 10;
BA_ "SignalType" SG_ 2150449152 ASIRI_Indication01 "BLN";
BA_ "PacketOrder" SG_ 2150449152 ASIRI_Indication01 1;
BA_ "SignalLongName" SG_ 2150449152 ASIRI_Indication01 "Auto Stop Inhibit Reason Indication : Indication 1";
BA_ "VNSigAllNodes" SG_ 2150449152 ASIRI_Indication01 1;
BA_ "GenSigSendType" SG_ 2150449152 SpdLmtrSttngTypAct 10;
BA_ "SignalType" SG_ 2150449152 SpdLmtrSttngTypAct "ENM";
BA_ "SignalLongName" SG_ 2150449152 SpdLmtrSttngTypAct "Speed Limiter Setting Type Active";
BA_ "VNSigAllNodes" SG_ 2150449152 SpdLmtrSttngTypAct 1;
BA_ "GenSigSendType" SG_ 2150449152 FuelSysNEmsRltMalfAct 10;
BA_ "SignalType" SG_ 2150449152 FuelSysNEmsRltMalfAct "BLN";
BA_ "SignalLongName" SG_ 2150449152 FuelSysNEmsRltMalfAct "Fuel System Non Emissions Related Malfunction Active";
BA_ "VNSigAllNodes" SG_ 2150449152 FuelSysNEmsRltMalfAct 1;
BA_ "GenSigSendType" SG_ 2150449152 InActFuelMdFuelLvlIO 10;
BA_ "SignalType" SG_ 2150449152 InActFuelMdFuelLvlIO "BLN";
BA_ "SignalLongName" SG_ 2150449152 InActFuelMdFuelLvlIO "Inactive Fuel Mode Fuel Level Indication On";
BA_ "VNSigAllNodes" SG_ 2150449152 InActFuelMdFuelLvlIO 1;
BA_ "GenSigSendType" SG_ 2150449152 EngInltSpcfcHmdtyV 10;
BA_ "SignalType" SG_ 2150449152 EngInltSpcfcHmdtyV "ENM";
BA_ "SignalLongName" SG_ 2150449152 EngInltSpcfcHmdtyV "Engine Inlet Specific Humidity Validity";
BA_ "VNSigAllNodes" SG_ 2150449152 EngInltSpcfcHmdtyV 1;
BA_ "GenSigSendType" SG_ 2150449152 EngInltSpcfcHmdtyM 10;
BA_ "SignalType" SG_ 2150449152 EngInltSpcfcHmdtyM "ENM";
BA_ "SignalLongName" SG_ 2150449152 EngInltSpcfcHmdtyM "Engine Inlet Specific Humidity Mask";
BA_ "VNSigAllNodes" SG_ 2150449152 EngInltSpcfcHmdtyM 1;
BA_ "GenSigDeltaValue" SG_ 2150449152 EngInltSpcfcHmdty 1;
BA_ "GenSigSendType" SG_ 2150449152 EngInltSpcfcHmdty 12;
BA_ "SignalType" SG_ 2150449152 EngInltSpcfcHmdty "UNM";
BA_ "SignalLongName" SG_ 2150449152 EngInltSpcfcHmdty "Engine Inlet Specific Humidity";
BA_ "VNSigAllNodes" SG_ 2150449152 EngInltSpcfcHmdty 1;
BA_ "GenSigSendType" SG_ 2150449152 AltFuelSysOvrflDtdIO 10;
BA_ "SignalType" SG_ 2150449152 AltFuelSysOvrflDtdIO "BLN";
BA_ "SignalLongName" SG_ 2150449152 AltFuelSysOvrflDtdIO "Alternative Fuel System Overfill Detected Indication On";
BA_ "VNSigAllNodes" SG_ 2150449152 AltFuelSysOvrflDtdIO 1;
BA_ "GenSigSendType" SG_ 2155945984 VehStbEnhmntCurStRq 10;
BA_ "SignalType" SG_ 2155945984 VehStbEnhmntCurStRq "ENM";
BA_ "SignalLongName" SG_ 2155945984 VehStbEnhmntCurStRq "Vehicle Stability Enhancement Current State Request";
BA_ "VNSigAllNodes" SG_ 2155945984 VehStbEnhmntCurStRq 1;
BA_ "GenSigSendType" SG_ 2155945984 VehStbCmptvMdCurStRq 10;
BA_ "SignalType" SG_ 2155945984 VehStbCmptvMdCurStRq "ENM";
BA_ "SignalLongName" SG_ 2155945984 VehStbCmptvMdCurStRq "Vehicle Stability Competitive Mode Current State Request";
BA_ "VNSigAllNodes" SG_ 2155945984 VehStbCmptvMdCurStRq 1;
BA_ "GenSigSendType" SG_ 2155945984 TCSysCurStReq 10;
BA_ "SignalType" SG_ 2155945984 TCSysCurStReq "ENM";
BA_ "SignalLongName" SG_ 2155945984 TCSysCurStReq "Traction Control System Current State Request";
BA_ "VNSigAllNodes" SG_ 2155945984 TCSysCurStReq 1;
BA_ "GenSigSendType" SG_ 2155945984 JmpStrtReq 10;
BA_ "GenSigSendOnInit" SG_ 2155945984 JmpStrtReq 1;
BA_ "SignalType" SG_ 2155945984 JmpStrtReq "BLN";
BA_ "SignalLongName" SG_ 2155945984 JmpStrtReq "Jump Start Requested";
BA_ "VNSigAllNodes" SG_ 2155945984 JmpStrtReq 1;
BA_ "GenSigDeltaValue" SG_ 2150580224 CstNonUsbSOCDspLvl 1;
BA_ "GenSigSendType" SG_ 2150580224 CstNonUsbSOCDspLvl 12;
BA_ "GenSigSendOnInit" SG_ 2150580224 CstNonUsbSOCDspLvl 1;
BA_ "SignalType" SG_ 2150580224 CstNonUsbSOCDspLvl "UNM";
BA_ "SignalLongName" SG_ 2150580224 CstNonUsbSOCDspLvl "Customer Non Usable State of Charge Display Level";
BA_ "VNSigAllNodes" SG_ 2150580224 CstNonUsbSOCDspLvl 1;
BA_ "GenSigSendType" SG_ 2150580224 CstmrNonUsblSOCV 10;
BA_ "GenSigSendOnInit" SG_ 2150580224 CstmrNonUsblSOCV 1;
BA_ "SignalType" SG_ 2150580224 CstmrNonUsblSOCV "ENM";
BA_ "SignalLongName" SG_ 2150580224 CstmrNonUsblSOCV "Customer Non Usable State of Charge Validity";
BA_ "VNSigAllNodes" SG_ 2150580224 CstmrNonUsblSOCV 1;
BA_ "GenSigDeltaValue" SG_ 2150580224 CstmrNonUsblSOC 1;
BA_ "GenSigSendType" SG_ 2150580224 CstmrNonUsblSOC 12;
BA_ "GenSigSendOnInit" SG_ 2150580224 CstmrNonUsblSOC 1;
BA_ "SignalType" SG_ 2150580224 CstmrNonUsblSOC "UNM";
BA_ "SignalLongName" SG_ 2150580224 CstmrNonUsblSOC "Customer Non Usable State of Charge";
BA_ "VNSigAllNodes" SG_ 2150580224 CstmrNonUsblSOC 1;
BA_ "GenSigDeltaValue" SG_ 2150580224 PrpDspTtlPwrLvlPct 1;
BA_ "GenSigSendType" SG_ 2150580224 PrpDspTtlPwrLvlPct 12;
BA_ "GenSigSendOnInit" SG_ 2150580224 PrpDspTtlPwrLvlPct 1;
BA_ "VNSigInfotainment" SG_ 2150580224 PrpDspTtlPwrLvlPct 1;
BA_ "SignalType" SG_ 2150580224 PrpDspTtlPwrLvlPct "SNM";
BA_ "SignalLongName" SG_ 2150580224 PrpDspTtlPwrLvlPct "Propulsion Display Total Power Level Percent";
BA_ "VNSigAllNodes" SG_ 2150580224 PrpDspTtlPwrLvlPct 1;
BA_ "GenSigDeltaValue" SG_ 2150391808 EngRunAtvTm 1;
BA_ "GenSigSendType" SG_ 2150391808 EngRunAtvTm 12;
BA_ "GenSigSendOnInit" SG_ 2150391808 EngRunAtvTm 1;
BA_ "SignalType" SG_ 2150391808 EngRunAtvTm "UNM";
BA_ "SignalLongName" SG_ 2150391808 EngRunAtvTm "Engine Run Active Time";
BA_ "VNSigAllNodes" SG_ 2150391808 EngRunAtvTm 1;
BA_ "GenSigDeltaValue" SG_ 2150391808 EngIdlAtvTm 1;
BA_ "GenSigSendType" SG_ 2150391808 EngIdlAtvTm 12;
BA_ "GenSigSendOnInit" SG_ 2150391808 EngIdlAtvTm 1;
BA_ "SignalType" SG_ 2150391808 EngIdlAtvTm "UNM";
BA_ "SignalLongName" SG_ 2150391808 EngIdlAtvTm "Engine Idle Active Time";
BA_ "VNSigAllNodes" SG_ 2150391808 EngIdlAtvTm 1;
BA_ "GenSigSendType" SG_ 2151735296 RtSdDetSysServDsbld 10;
BA_ "SignalType" SG_ 2151735296 RtSdDetSysServDsbld "BLN";
BA_ "SignalLongName" SG_ 2151735296 RtSdDetSysServDsbld "Right Side Detection System Service Disabled";
BA_ "VNSigAllNodes" SG_ 2151735296 RtSdDetSysServDsbld 1;
BA_ "GenSigSendType" SG_ 2151735296 RtSdDetSysTmpDsbld 10;
BA_ "SignalType" SG_ 2151735296 RtSdDetSysTmpDsbld "BLN";
BA_ "SignalLongName" SG_ 2151735296 RtSdDetSysTmpDsbld "Right Side Detection System Temp Disabled";
BA_ "VNSigAllNodes" SG_ 2151735296 RtSdDetSysTmpDsbld 1;
BA_ "GenSigSendType" SG_ 2151735296 RtLnChgAlrtEnbld 10;
BA_ "SignalType" SG_ 2151735296 RtLnChgAlrtEnbld "BLN";
BA_ "SignalLongName" SG_ 2151735296 RtLnChgAlrtEnbld "Right Lane Change Alert Enabled";
BA_ "VNSigAllNodes" SG_ 2151735296 RtLnChgAlrtEnbld 1;
BA_ "GenSigSendType" SG_ 2151735296 RtSBZAlrtEnbld 10;
BA_ "SignalType" SG_ 2151735296 RtSBZAlrtEnbld "BLN";
BA_ "SignalLongName" SG_ 2151735296 RtSBZAlrtEnbld "Right Side Blind Zone Alert Enabled";
BA_ "VNSigAllNodes" SG_ 2151735296 RtSBZAlrtEnbld 1;
BA_ "GenSigSendType" SG_ 2151735296 RtRrCrsTrfcAlrtEnbld 10;
BA_ "SignalType" SG_ 2151735296 RtRrCrsTrfcAlrtEnbld "BLN";
BA_ "SignalLongName" SG_ 2151735296 RtRrCrsTrfcAlrtEnbld "Right Rear Cross Traffic Alert Enabled";
BA_ "VNSigAllNodes" SG_ 2151735296 RtRrCrsTrfcAlrtEnbld 1;
BA_ "GenSigSendType" SG_ 2151735296 LnChgAlrtOffIndOn 10;
BA_ "SignalType" SG_ 2151735296 LnChgAlrtOffIndOn "BLN";
BA_ "SignalLongName" SG_ 2151735296 LnChgAlrtOffIndOn "Lane Change Alert Off Indication On";
BA_ "VNSigAllNodes" SG_ 2151735296 LnChgAlrtOffIndOn 1;
BA_ "GenSigSendType" SG_ 2151735296 RrCrsTrfcAlrtOffIO 10;
BA_ "SignalType" SG_ 2151735296 RrCrsTrfcAlrtOffIO "BLN";
BA_ "SignalLongName" SG_ 2151735296 RrCrsTrfcAlrtOffIO "Rear Cross Traffic Alert Off Indication On";
BA_ "VNSigAllNodes" SG_ 2151735296 RrCrsTrfcAlrtOffIO 1;
BA_ "GenSigDeltaValue" SG_ 2159198208 ODI_IPC2AxIP 1;
BA_ "GenSigSendType" SG_ 2159198208 ODI_IPC2AxIP 12;
BA_ "VNSigInfotainment" SG_ 2159198208 ODI_IPC2AxIP 1;
BA_ "SignalType" SG_ 2159198208 ODI_IPC2AxIP "UNM";
BA_ "SignalLongName" SG_ 2159198208 ODI_IPC2AxIP "Open Display Interface IPC 2 AuxIP";
BA_ "VNSigAllNodes" SG_ 2159198208 ODI_IPC2AxIP 1;
BA_ "GenSigDeltaValue" SG_ 2159075328 ODI_IPC2DAB 1;
BA_ "GenSigSendType" SG_ 2159075328 ODI_IPC2DAB 12;
BA_ "VNSigInfotainment" SG_ 2159075328 ODI_IPC2DAB 1;
BA_ "SignalType" SG_ 2159075328 ODI_IPC2DAB "UNM";
BA_ "SignalLongName" SG_ 2159075328 ODI_IPC2DAB "Open Display Interface IPC 2 DAB";
BA_ "VNSigAllNodes" SG_ 2159075328 ODI_IPC2DAB 1;
BA_ "GenSigSendType" SG_ 2155298816 TrPrsMntrTrLdRstRqstd 10;
BA_ "SignalType" SG_ 2155298816 TrPrsMntrTrLdRstRqstd "ENM";
BA_ "SignalLongName" SG_ 2155298816 TrPrsMntrTrLdRstRqstd "Tire Pressure Monitoring Tire Loading Reset Requested";
BA_ "VNSigAllNodes" SG_ 2155298816 TrPrsMntrTrLdRstRqstd 1;
BA_ "GenSigSendType" SG_ 2155298816 TrPrsSnsProgEvntRqd 10;
BA_ "GenSigSendOnInit" SG_ 2155298816 TrPrsSnsProgEvntRqd 2;
BA_ "SignalType" SG_ 2155298816 TrPrsSnsProgEvntRqd "BLN";
BA_ "SignalLongName" SG_ 2155298816 TrPrsSnsProgEvntRqd "Tire Pressure Sensor Programming Event Requested";
BA_ "VNSigAllNodes" SG_ 2155298816 TrPrsSnsProgEvntRqd 1;
BA_ "GenSigSendType" SG_ 2155298816 EngAirFltMonDrvrReq 10;
BA_ "SignalType" SG_ 2155298816 EngAirFltMonDrvrReq "ENM";
BA_ "SignalLongName" SG_ 2155298816 EngAirFltMonDrvrReq "Engine Air Filter Monitor Driver Request";
BA_ "VNSigAllNodes" SG_ 2155298816 EngAirFltMonDrvrReq 1;
BA_ "GenSigSendType" SG_ 2157985792 FobProgEvntRqd 10;
BA_ "GenSigSendOnInit" SG_ 2157985792 FobProgEvntRqd 2;
BA_ "SignalType" SG_ 2157985792 FobProgEvntRqd "BLN";
BA_ "SignalLongName" SG_ 2157985792 FobProgEvntRqd "Fob Programming Event Requested";
BA_ "VNSigAllNodes" SG_ 2157985792 FobProgEvntRqd 1;
BA_ "GenSigSendType" SG_ 2153955328 EngOffTmExtRngV 10;
BA_ "VNSigInfotainment" SG_ 2153955328 EngOffTmExtRngV 1;
BA_ "SignalType" SG_ 2153955328 EngOffTmExtRngV "ENM";
BA_ "SignalLongName" SG_ 2153955328 EngOffTmExtRngV "Engine Off Time Extended Range Validity";
BA_ "VNSigAllNodes" SG_ 2153955328 EngOffTmExtRngV 1;
BA_ "GenSigDeltaValue" SG_ 2153955328 EngOffTmExtRng 1;
BA_ "GenSigSendType" SG_ 2153955328 EngOffTmExtRng 12;
BA_ "GenSigSendOnInit" SG_ 2153955328 EngOffTmExtRng 2;
BA_ "VNSigInfotainment" SG_ 2153955328 EngOffTmExtRng 1;
BA_ "SignalType" SG_ 2153955328 EngOffTmExtRng "UNM";
BA_ "SignalLongName" SG_ 2153955328 EngOffTmExtRng "Engine Off Time Extended Range";
BA_ "VNSigAllNodes" SG_ 2153955328 EngOffTmExtRng 1;
BA_ "GenSigSendType" SG_ 2153955328 ElpsdTimeCntRstOcc 10;
BA_ "SignalType" SG_ 2153955328 ElpsdTimeCntRstOcc "BLN";
BA_ "SignalLongName" SG_ 2153955328 ElpsdTimeCntRstOcc "Elapsed Time Count Reset Occurred";
BA_ "VNSigAllNodes" SG_ 2153955328 ElpsdTimeCntRstOcc 1;
BA_ "GenSigDeltaValue" SG_ 2153955328 ElpsdTimeCnt 1;
BA_ "GenSigSendType" SG_ 2153955328 ElpsdTimeCnt 12;
BA_ "SignalType" SG_ 2153955328 ElpsdTimeCnt "UNM";
BA_ "SignalLongName" SG_ 2153955328 ElpsdTimeCnt "Elapsed Time Count";
BA_ "VNSigAllNodes" SG_ 2153955328 ElpsdTimeCnt 1;
BA_REL_ "GenSigSuprvResp" BU_SG_REL_ VCU_LE SG_ 2154807296 AFLMnu3CstStAvl 1;
BA_REL_ "GenSigSuprvResp" BU_SG_REL_ CSM_LE SG_ 2154807296 AFLMnu3CstStAvl 1;
BA_REL_ "GenSigSuprvResp" BU_SG_REL_ RadioHead_LE SG_ 2154807296 AFLMnu3CstStAvl 1;
BA_REL_ "GenSigSuprvResp" BU_SG_REL_ VCU_LE SG_ 2154807296 AFLMnu2CstStAvl 1;
BA_REL_ "GenSigSuprvResp" BU_SG_REL_ CSM_LE SG_ 2154807296 AFLMnu2CstStAvl 1;
BA_REL_ "GenSigSuprvResp" BU_SG_REL_ RadioHead_LE SG_ 2154807296 AFLMnu2CstStAvl 1;
BA_REL_ "GenSigSuprvResp" BU_SG_REL_ VCU_LE SG_ 2154807296 AFLGPSMnu2CstStAvl 1;
BA_REL_ "GenSigSuprvResp" BU_SG_REL_ CSM_LE SG_ 2154807296 AFLGPSMnu2CstStAvl 1;
BA_REL_ "GenSigSuprvResp" BU_SG_REL_ RadioHead_LE SG_ 2154807296 AFLGPSMnu2CstStAvl 1;
BA_REL_ "GenSigSuprvResp" BU_SG_REL_ VCU_LE SG_ 2154807296 AFLGPSCstStAvl 1;
BA_REL_ "GenSigSuprvResp" BU_SG_REL_ CSM_LE SG_ 2154807296 AFLGPSCstStAvl 1;
BA_REL_ "GenSigSuprvResp" BU_SG_REL_ RadioHead_LE SG_ 2154807296 AFLGPSCstStAvl 1;
BA_REL_ "GenSigSuprvResp" BU_SG_REL_ VCU_LE SG_ 2154807296 AFLGPSCstCrStVal 1;
BA_REL_ "GenSigSuprvResp" BU_SG_REL_ CSM_LE SG_ 2154807296 AFLGPSCstCrStVal 1;
BA_REL_ "GenSigSuprvResp" BU_SG_REL_ RadioHead_LE SG_ 2154807296 AFLGPSCstCrStVal 1;
BA_REL_ "GenSigSuprvResp" BU_SG_REL_ VCU_LE SG_ 2154807296 AFLCstStAvl 1;
BA_REL_ "GenSigSuprvResp" BU_SG_REL_ CSM_LE SG_ 2154807296 AFLCstStAvl 1;
BA_REL_ "GenSigSuprvResp" BU_SG_REL_ RadioHead_LE SG_ 2154807296 AFLCstStAvl 1;
BA_REL_ "GenSigSuprvResp" BU_SG_REL_ VCU_LE SG_ 2154807296 AFLCstCrStVal 1;
BA_REL_ "GenSigSuprvResp" BU_SG_REL_ CSM_LE SG_ 2154807296 AFLCstCrStVal 1;
BA_REL_ "GenSigSuprvResp" BU_SG_REL_ RadioHead_LE SG_ 2154807296 AFLCstCrStVal 1;
BA_REL_ "GenSigSuprvResp" BU_SG_REL_ VCU_LE SG_ 2155970560 ClmCntBatSaverIO 1;
BA_REL_ "GenSigSuprvResp" BU_SG_REL_ IPC_LE SG_ 2155970560 ClmCntBatSaverIO 1;
BA_REL_ "GenSigSuprvResp" BU_SG_REL_ RCRM_LE SG_ 2151686144 RrCmrDeplmntReqtsd 1;
BA_REL_ "GenSigSuprvResp" BU_SG_REL_ VCU_LE SG_ 2153914368 EUSS_TrEgUgScrMxScVal 1;
BA_REL_ "GenSigSuprvResp" BU_SG_REL_ CSM_LE SG_ 2153914368 EUSS_TrEgUgScrMxScVal 1;
BA_REL_ "GenSigSuprvResp" BU_SG_REL_ RadioHead_LE SG_ 2153914368 EUSS_TrEgUgScrMxScVal 1;
BA_REL_ "GenSigSuprvResp" BU_SG_REL_ VCU_LE SG_ 2153914368 EUSS_TrEgUgScrMnScVal 1;
BA_REL_ "GenSigSuprvResp" BU_SG_REL_ CSM_LE SG_ 2153914368 EUSS_TrEgUgScrMnScVal 1;
BA_REL_ "GenSigSuprvResp" BU_SG_REL_ RadioHead_LE SG_ 2153914368 EUSS_TrEgUgScrMnScVal 1;
BA_REL_ "GenSigSuprvResp" BU_SG_REL_ VCU_LE SG_ 2153914368 EUSS_TcEgUgScrMxScVal 1;
BA_REL_ "GenSigSuprvResp" BU_SG_REL_ CSM_LE SG_ 2153914368 EUSS_TcEgUgScrMxScVal 1;
BA_REL_ "GenSigSuprvResp" BU_SG_REL_ RadioHead_LE SG_ 2153914368 EUSS_TcEgUgScrMxScVal 1;
BA_REL_ "GenSigSuprvResp" BU_SG_REL_ VCU_LE SG_ 2153914368 EUSS_TcEgUgScrMnScVal 1;
BA_REL_ "GenSigSuprvResp" BU_SG_REL_ CSM_LE SG_ 2153914368 EUSS_TcEgUgScrMnScVal 1;
BA_REL_ "GenSigSuprvResp" BU_SG_REL_ RadioHead_LE SG_ 2153914368 EUSS_TcEgUgScrMnScVal 1;
BA_REL_ "GenSigSuprvResp" BU_SG_REL_ VCU_LE SG_ 2153914368 EUSS_ITEgUgScrMxScVal 1;
BA_REL_ "GenSigSuprvResp" BU_SG_REL_ CSM_LE SG_ 2153914368 EUSS_ITEgUgScrMxScVal 1;
BA_REL_ "GenSigSuprvResp" BU_SG_REL_ RadioHead_LE SG_ 2153914368 EUSS_ITEgUgScrMxScVal 1;
BA_REL_ "GenSigSuprvResp" BU_SG_REL_ VCU_LE SG_ 2153914368 EUSS_ITEgUgScrMnScVal 1;
BA_REL_ "GenSigSuprvResp" BU_SG_REL_ CSM_LE SG_ 2153914368 EUSS_ITEgUgScrMnScVal 1;
BA_REL_ "GenSigSuprvResp" BU_SG_REL_ RadioHead_LE SG_ 2153914368 EUSS_ITEgUgScrMnScVal 1;
BA_REL_ "GenSigSuprvResp" BU_SG_REL_ VCU_LE SG_ 2153914368 EUSS_OTEgUgScrMxScVal 1;
BA_REL_ "GenSigSuprvResp" BU_SG_REL_ CSM_LE SG_ 2153914368 EUSS_OTEgUgScrMxScVal 1;
BA_REL_ "GenSigSuprvResp" BU_SG_REL_ RadioHead_LE SG_ 2153914368 EUSS_OTEgUgScrMxScVal 1;
BA_REL_ "GenSigSuprvResp" BU_SG_REL_ VCU_LE SG_ 2153914368 EUSS_OTEgUgScrMnScVal 1;
BA_REL_ "GenSigSuprvResp" BU_SG_REL_ CSM_LE SG_ 2153914368 EUSS_OTEgUgScrMnScVal 1;
BA_REL_ "GenSigSuprvResp" BU_SG_REL_ RadioHead_LE SG_ 2153914368 EUSS_OTEgUgScrMnScVal 1;
BA_REL_ "GenSigSuprvResp" BU_SG_REL_ VCU_LE SG_ 2153390080 RrClosOpenSwAct_2D1 1;
BA_REL_ "GenSigSuprvResp" BU_SG_REL_ IPC_LE SG_ 2153390080 RrClosOpenSwAct_2D1 1;
BA_REL_ "GenSigSuprvResp" BU_SG_REL_ VCU_LE SG_ 2151415808 FrPedDetCsCrStVal 1;
BA_REL_ "GenSigSuprvResp" BU_SG_REL_ CSM_LE SG_ 2151415808 FrPedDetCsCrStVal 1;
BA_REL_ "GenSigSuprvResp" BU_SG_REL_ RadioHead_LE SG_ 2151415808 FrPedDetCsCrStVal 1;
BA_REL_ "GenSigSuprvResp" BU_SG_REL_ VCU_LE SG_ 2150080512 LBCVLS_VehGPSLctV 1;
BA_REL_ "GenSigSuprvResp" BU_SG_REL_ CSM_LE SG_ 2150080512 LBCVLS_VehGPSLctV 1;
BA_REL_ "GenSigSuprvResp" BU_SG_REL_ RadioHead_LE SG_ 2150080512 LBCVLS_VehGPSLctV 1;
BA_REL_ "GenSigSuprvResp" BU_SG_REL_ VCU_LE SG_ 2150080512 LBCVLS_VehGPSLct 1;
BA_REL_ "GenSigSuprvResp" BU_SG_REL_ CSM_LE SG_ 2150080512 LBCVLS_VehGPSLct 1;
BA_REL_ "GenSigSuprvResp" BU_SG_REL_ RadioHead_LE SG_ 2150080512 LBCVLS_VehGPSLct 1;
BA_REL_ "GenSigSuprvResp" BU_SG_REL_ VCU_LE SG_ 2150080512 LBCCF_Lct4PosStrdIO 1;
BA_REL_ "GenSigSuprvResp" BU_SG_REL_ CSM_LE SG_ 2150080512 LBCCF_Lct4PosStrdIO 1;
BA_REL_ "GenSigSuprvResp" BU_SG_REL_ RadioHead_LE SG_ 2150080512 LBCCF_Lct4PosStrdIO 1;
BA_REL_ "GenSigSuprvResp" BU_SG_REL_ VCU_LE SG_ 2150080512 LBCCF_Lct3PosStrdIO 1;
BA_REL_ "GenSigSuprvResp" BU_SG_REL_ CSM_LE SG_ 2150080512 LBCCF_Lct3PosStrdIO 1;
BA_REL_ "GenSigSuprvResp" BU_SG_REL_ RadioHead_LE SG_ 2150080512 LBCCF_Lct3PosStrdIO 1;
BA_REL_ "GenSigSuprvResp" BU_SG_REL_ VCU_LE SG_ 2150080512 LBCCF_Lct2PosStrdIO 1;
BA_REL_ "GenSigSuprvResp" BU_SG_REL_ CSM_LE SG_ 2150080512 LBCCF_Lct2PosStrdIO 1;
BA_REL_ "GenSigSuprvResp" BU_SG_REL_ RadioHead_LE SG_ 2150080512 LBCCF_Lct2PosStrdIO 1;
BA_REL_ "GenSigSuprvResp" BU_SG_REL_ VCU_LE SG_ 2150080512 LBCCF_Lct1PosStrdIO 1;
BA_REL_ "GenSigSuprvResp" BU_SG_REL_ CSM_LE SG_ 2150080512 LBCCF_Lct1PosStrdIO 1;
BA_REL_ "GenSigSuprvResp" BU_SG_REL_ RadioHead_LE SG_ 2150080512 LBCCF_Lct1PosStrdIO 1;
BA_REL_ "GenSigSuprvResp" BU_SG_REL_ VCU_LE SG_ 2150080512 ChrgCyclOvrlEngyEcnEq 1;
BA_REL_ "GenSigSuprvResp" BU_SG_REL_ CSM_LE SG_ 2150080512 ChrgCyclOvrlEngyEcnEq 1;
BA_REL_ "GenSigSuprvResp" BU_SG_REL_ RadioHead_LE SG_ 2150080512 ChrgCyclOvrlEngyEcnEq 1;
BA_REL_ "GenSigSuprvResp" BU_SG_REL_ VCU_LE SG_ 2150080512 ChrgCyclElecEngyEcnEq 1;
BA_REL_ "GenSigSuprvResp" BU_SG_REL_ CSM_LE SG_ 2150080512 ChrgCyclElecEngyEcnEq 1;
BA_REL_ "GenSigSuprvResp" BU_SG_REL_ RadioHead_LE SG_ 2150080512 ChrgCyclElecEngyEcnEq 1;
BA_REL_ "GenSigSuprvResp" BU_SG_REL_ VCU_LE SG_ 2153988096 EUS_TtEngyUsgScrAvVal 1;
BA_REL_ "GenSigSuprvResp" BU_SG_REL_ CSM_LE SG_ 2153988096 EUS_TtEngyUsgScrAvVal 1;
BA_REL_ "GenSigSuprvResp" BU_SG_REL_ RadioHead_LE SG_ 2153988096 EUS_TtEngyUsgScrAvVal 1;
BA_REL_ "GenSigSuprvResp" BU_SG_REL_ VCU_LE SG_ 2153988096 EUS_ITEngyUsgScrAvVal 1;
BA_REL_ "GenSigSuprvResp" BU_SG_REL_ CSM_LE SG_ 2153988096 EUS_ITEngyUsgScrAvVal 1;
BA_REL_ "GenSigSuprvResp" BU_SG_REL_ RadioHead_LE SG_ 2153988096 EUS_ITEngyUsgScrAvVal 1;
BA_REL_ "GenSigSuprvResp" BU_SG_REL_ VCU_LE SG_ 2153988096 EUS_OTEngyUsgScrAvVal 1;
BA_REL_ "GenSigSuprvResp" BU_SG_REL_ CSM_LE SG_ 2153988096 EUS_OTEngyUsgScrAvVal 1;
BA_REL_ "GenSigSuprvResp" BU_SG_REL_ RadioHead_LE SG_ 2153988096 EUS_OTEngyUsgScrAvVal 1;
BA_REL_ "GenSigSuprvResp" BU_SG_REL_ VCU_LE SG_ 2153988096 EUS_TrEngyUsgScrAvVal 1;
BA_REL_ "GenSigSuprvResp" BU_SG_REL_ CSM_LE SG_ 2153988096 EUS_TrEngyUsgScrAvVal 1;
BA_REL_ "GenSigSuprvResp" BU_SG_REL_ RadioHead_LE SG_ 2153988096 EUS_TrEngyUsgScrAvVal 1;
BA_REL_ "GenSigSuprvResp" BU_SG_REL_ VCU_LE SG_ 2153988096 EUS_TcEngyUsgScrAvVal 1;
BA_REL_ "GenSigSuprvResp" BU_SG_REL_ CSM_LE SG_ 2153988096 EUS_TcEngyUsgScrAvVal 1;
BA_REL_ "GenSigSuprvResp" BU_SG_REL_ RadioHead_LE SG_ 2153988096 EUS_TcEngyUsgScrAvVal 1;
BA_REL_ "GenSigSuprvResp" BU_SG_REL_ VCU_LE SG_ 2151915520 ElcShfPriTwoGrsSlInRq 1;
BA_REL_ "GenSigSuprvResp" BU_SG_REL_ IPC_LE SG_ 2151915520 ElcShfPriTwoGrsSlInRq 1;
BA_REL_ "GenSigSuprvResp" BU_SG_REL_ VCU_LE SG_ 2151915520 DrvEffInd 1;
BA_REL_ "GenSigSuprvResp" BU_SG_REL_ IPC_LE SG_ 2151915520 DrvEffInd 1;
BA_REL_ "GenSigSuprvResp" BU_SG_REL_ VCU_LE SG_ 2151915520 EngIntkArBstPrExtRng 1;
BA_REL_ "GenSigSuprvResp" BU_SG_REL_ IPC_LE SG_ 2151915520 EngIntkArBstPrExtRng 1;
BA_REL_ "GenSigSuprvResp" BU_SG_REL_ VCU_LE SG_ 2151915520 ElecShfRngDispRCExtd 1;
BA_REL_ "GenSigSuprvResp" BU_SG_REL_ IPC_LE SG_ 2151915520 ElecShfRngDispRCExtd 1;
BA_REL_ "GenSigSuprvResp" BU_SG_REL_ VCU_LE SG_ 2151915520 ElecShfRngDisp 1;
BA_REL_ "GenSigSuprvResp" BU_SG_REL_ IPC_LE SG_ 2151915520 ElecShfRngDisp 1;
BA_REL_ "GenSigVDAFailComment" BU_SG_REL_ VCU_LE SG_ 2151915520 ESPTransMalfIO "Electronic Transmission Range Select Virtual Device Availability";
BA_REL_ "GenSigVDAFailResp" BU_SG_REL_ VCU_LE SG_ 2151915520 ESPTransMalfIO 1;
BA_REL_ "GenSigSuprvResp" BU_SG_REL_ VCU_LE SG_ 2151915520 ESPTransMalfIO 1;
BA_REL_ "GenSigVDAFailComment" BU_SG_REL_ IPC_LE SG_ 2151915520 ESPTransMalfIO "Electronic Transmission Range Select Virtual Device Availability";
BA_REL_ "GenSigVDAFailResp" BU_SG_REL_ IPC_LE SG_ 2151915520 ESPTransMalfIO 1;
BA_REL_ "GenSigSuprvResp" BU_SG_REL_ IPC_LE SG_ 2151915520 ESPTransMalfIO 1;
BA_REL_ "GenSigSuprvResp" BU_SG_REL_ VCU_LE SG_ 2151915520 ESPRngInvldReqIO 1;
BA_REL_ "GenSigSuprvResp" BU_SG_REL_ IPC_LE SG_ 2151915520 ESPRngInvldReqIO 1;
BA_REL_ "GenSigSuprvResp" BU_SG_REL_ VCU_LE SG_ 2151915520 ESPPrkInvldReqIO 1;
BA_REL_ "GenSigSuprvResp" BU_SG_REL_ IPC_LE SG_ 2151915520 ESPPrkInvldReqIO 1;
BA_REL_ "GenSigSuprvResp" BU_SG_REL_ VCU_LE SG_ 2151915520 ESPHldShfLvrToEngRgIO 1;
BA_REL_ "GenSigSuprvResp" BU_SG_REL_ IPC_LE SG_ 2151915520 ESPHldShfLvrToEngRgIO 1;
BA_REL_ "GenSigSuprvResp" BU_SG_REL_ VCU_LE SG_ 2151915520 ESPDrvrPrkIlkSftAtdIO 1;
BA_REL_ "GenSigSuprvResp" BU_SG_REL_ IPC_LE SG_ 2151915520 ESPDrvrPrkIlkSftAtdIO 1;
BA_REL_ "GenSigSuprvResp" BU_SG_REL_ VCU_LE SG_ 2151915520 ESPDrvrIlkShfAtdIO 1;
BA_REL_ "GenSigSuprvResp" BU_SG_REL_ IPC_LE SG_ 2151915520 ESPDrvrIlkShfAtdIO 1;
BA_REL_ "GenSigSuprvResp" BU_SG_REL_ VCU_LE SG_ 2151915520 AHAct 1;
BA_REL_ "GenSigSuprvResp" BU_SG_REL_ IPC_LE SG_ 2151915520 AHAct 1;
BA_REL_ "GenSigSuprvResp" BU_SG_REL_ VCU_LE SG_ 2151915520 AHEnbld 1;
BA_REL_ "GenSigSuprvResp" BU_SG_REL_ IPC_LE SG_ 2151915520 AHEnbld 1;
BA_REL_ "GenSigSuprvResp" BU_SG_REL_ VCU_LE SG_ 2151915520 ShfToPrkBfExtngIO 1;
BA_REL_ "GenSigSuprvResp" BU_SG_REL_ IPC_LE SG_ 2151915520 ShfToPrkBfExtngIO 1;
BA_REL_ "GenSigSuprvResp" BU_SG_REL_ VCU_LE SG_ 2151915520 AHServcIO 1;
BA_REL_ "GenSigSuprvResp" BU_SG_REL_ IPC_LE SG_ 2151915520 AHServcIO 1;
BA_REL_ "GenSigSuprvResp" BU_SG_REL_ VCU_LE SG_ 2151915520 AHAppBrkPedlIO 1;
BA_REL_ "GenSigSuprvResp" BU_SG_REL_ IPC_LE SG_ 2151915520 AHAppBrkPedlIO 1;
BA_REL_ "GenSigSuprvResp" BU_SG_REL_ VCU_LE SG_ 2151915520 AHDisbldStbltIO 1;
BA_REL_ "GenSigSuprvResp" BU_SG_REL_ IPC_LE SG_ 2151915520 AHDisbldStbltIO 1;
BA_REL_ "GenSigSuprvResp" BU_SG_REL_ VCU_LE SG_ 2151915520 AHDisbldDrOpnIO 1;
BA_REL_ "GenSigSuprvResp" BU_SG_REL_ IPC_LE SG_ 2151915520 AHDisbldDrOpnIO 1;
BA_REL_ "GenSigSuprvResp" BU_SG_REL_ VCU_LE SG_ 2151489536 NVSysStat 1;
BA_REL_ "GenSigSuprvResp" BU_SG_REL_ IPC_LE SG_ 2151489536 NVSysStat 1;
BA_REL_ "GenSigSuprvResp" BU_SG_REL_ VCU_LE SG_ 2152857600 ACCGrnMdStat 1;
BA_REL_ "GenSigSuprvResp" BU_SG_REL_ IPC_LE SG_ 2152857600 ACCGrnMdStat 1;
BA_REL_ "GenSigSuprvResp" BU_SG_REL_ VCU_LE SG_ 2152857600 ACCRteSpdAdaptStat 1;
BA_REL_ "GenSigSuprvResp" BU_SG_REL_ IPC_LE SG_ 2152857600 ACCRteSpdAdaptStat 1;
BA_REL_ "GenSigSuprvResp" BU_SG_REL_ VCU_LE SG_ 2152857600 ACCRteSpdDrvIntvReq 1;
BA_REL_ "GenSigSuprvResp" BU_SG_REL_ IPC_LE SG_ 2152857600 ACCRteSpdDrvIntvReq 1;
BA_REL_ "GenSigSuprvResp" BU_SG_REL_ VCU_LE SG_ 2152857600 ACCTrfcJamAstActStat 1;
BA_REL_ "GenSigSuprvResp" BU_SG_REL_ IPC_LE SG_ 2152857600 ACCTrfcJamAstActStat 1;
BA_REL_ "GenSigSuprvResp" BU_SG_REL_ VCU_LE SG_ 2152857600 ACCTrfcJamAstRmnTm 1;
BA_REL_ "GenSigSuprvResp" BU_SG_REL_ IPC_LE SG_ 2152857600 ACCTrfcJamAstRmnTm 1;
BA_REL_ "GenSigSuprvResp" BU_SG_REL_ VCU_LE SG_ 2150825984 PdstIntdProtSysDplyd 1;
BA_REL_ "GenSigSuprvResp" BU_SG_REL_ IPC_LE SG_ 2150825984 PdstIntdProtSysDplyd 1;
BA_REL_ "GenSigSuprvResp" BU_SG_REL_ VCU_LE SG_ 2150825984 PdstIntdProtSysDsbld 1;
BA_REL_ "GenSigSuprvResp" BU_SG_REL_ IPC_LE SG_ 2150825984 PdstIntdProtSysDsbld 1;
BA_REL_ "GenSigSuprvResp" BU_SG_REL_ VCU_LE SG_ 2150825984 SrvIntdPdstProtSysIO 1;
BA_REL_ "GenSigSuprvResp" BU_SG_REL_ IPC_LE SG_ 2150825984 SrvIntdPdstProtSysIO 1;
BA_REL_ "GenSigSuprvResp" BU_SG_REL_ V2V_LE SG_ 2150825984 FstnThrdRwCtPsStbtInR 1;
BA_REL_ "GenSigSuprvResp" BU_SG_REL_ V2V_LE SG_ 2150825984 FPSIC_IndPer 1;
BA_REL_ "GenSigSuprvResp" BU_SG_REL_ V2V_LE SG_ 2150825984 FPSIC_IO 1;
BA_REL_ "GenSigSuprvResp" BU_SG_REL_ V2V_LE SG_ 2150825984 FPSIC_IndDtCyc 1;
BA_REL_ "GenSigSuprvResp" BU_SG_REL_ V2V_LE SG_ 2150825984 FDSIC_IndPer 1;
BA_REL_ "GenSigSuprvResp" BU_SG_REL_ V2V_LE SG_ 2150825984 FDSIC_IO 1;
BA_REL_ "GenSigSuprvResp" BU_SG_REL_ V2V_LE SG_ 2150825984 FDSIC_IndDC 1;
BA_REL_ "GenSigSuprvResp" BU_SG_REL_ V2V_LE SG_ 2150825984 AirbgFldIO 1;
BA_REL_ "GenSigSuprvResp" BU_SG_REL_ VCU_LE SG_ 2150825984 AirbgFldIO 1;
BA_REL_ "GenSigSuprvResp" BU_SG_REL_ IPC_LE SG_ 2150825984 AirbgFldIO 1;
BA_REL_ "GenSigSuprvResp" BU_SG_REL_ VCU_LE SG_ 2150825984 AirbgICIndPer 1;
BA_REL_ "GenSigSuprvResp" BU_SG_REL_ IPC_LE SG_ 2150825984 AirbgICIndPer 1;
BA_REL_ "GenSigSuprvResp" BU_SG_REL_ VCU_LE SG_ 2150825984 AirbgICDutCyc 1;
BA_REL_ "GenSigSuprvResp" BU_SG_REL_ IPC_LE SG_ 2150825984 AirbgICDutCyc 1;
BA_REL_ "GenSigSuprvResp" BU_SG_REL_ VCU_LE SG_ 2150825984 AirbgICIO 1;
BA_REL_ "GenSigSuprvResp" BU_SG_REL_ IPC_LE SG_ 2150825984 AirbgICIO 1;
BA_REL_ "GenSigSuprvResp" BU_SG_REL_ V2V_LE SG_ 2150825984 FstnSndRwRtPsStbtInR 1;
BA_REL_ "GenSigSuprvResp" BU_SG_REL_ V2V_LE SG_ 2150825984 FstnSndRwLtPsStbtInR 1;
BA_REL_ "GenSigSuprvResp" BU_SG_REL_ VPM_LE SG_ 2149974016 AlrmStat 1;
BA_REL_ "GenSigSuprvResp" BU_SG_REL_ VCU_LE SG_ 2155929600 DslExhFldDiagWrnIdRq 1;
BA_REL_ "GenSigSuprvResp" BU_SG_REL_ IPC_LE SG_ 2155929600 DslExhFldDiagWrnIdRq 1;
BA_REL_ "GenSigSuprvResp" BU_SG_REL_ VCU_LE SG_ 2155929600 DslExhFluidDistTIndcmt 1;
BA_REL_ "GenSigSuprvResp" BU_SG_REL_ IPC_LE SG_ 2155929600 DslExhFluidDistTIndcmt 1;
BA_REL_ "GenSigSuprvResp" BU_SG_REL_ V2V_LE SG_ 2153807872 PsDoorOpenSwAct 1;
BA_REL_ "GenSigSuprvResp" BU_SG_REL_ V2V_LE SG_ 2153807872 DrDoorOpenSwAct 1;
BA_REL_ "GenSigSuprvResp" BU_SG_REL_ V2V_LE SG_ 2151751680 HptcStVbnStat 1;
BA_REL_ "GenSigSuprvResp" BU_SG_REL_ V2V_LE SG_ 2151751680 HptcStFldIO 1;
BA_REL_ "GenSigSuprvResp" BU_SG_REL_ VCU_LE SG_ 2151751680 HptcStFldIO 1;
BA_REL_ "GenSigSuprvResp" BU_SG_REL_ IPC_LE SG_ 2151751680 HptcStFldIO 1;
BA_REL_ "GenSigSuprvResp" BU_SG_REL_ V2V_LE SG_ 2151751680 CrshAlrtDrvrSlctdType 1;
BA_REL_ "GenSigSuprvResp" BU_SG_REL_ V2V_LE SG_ 2151751680 CrshAlrtStPrsnt 1;
BA_REL_ "GenSigSuprvResp" BU_SG_REL_ VCU_LE SG_ 2152464384 RtLnDepWrnSt 1;
BA_REL_ "GenSigSuprvResp" BU_SG_REL_ IPC_LE SG_ 2152464384 RtLnDepWrnSt 1;
BA_REL_ "GenSigSuprvResp" BU_SG_REL_ VCU_LE SG_ 2152464384 LftLnDepWrnSt 1;
BA_REL_ "GenSigSuprvResp" BU_SG_REL_ IPC_LE SG_ 2152464384 LftLnDepWrnSt 1;
BA_REL_ "GenSigSuprvResp" BU_SG_REL_ VCU_LE SG_ 2152464384 TnDrvLDWOffUnbIO 1;
BA_REL_ "GenSigSuprvResp" BU_SG_REL_ IPC_LE SG_ 2152464384 TnDrvLDWOffUnbIO 1;
BA_REL_ "GenSigSuprvResp" BU_SG_REL_ VCU_LE SG_ 2152464384 SrvcLnKpAstSysIO 1;
BA_REL_ "GenSigSuprvResp" BU_SG_REL_ IPC_LE SG_ 2152464384 SrvcLnKpAstSysIO 1;
BA_REL_ "GenSigSuprvResp" BU_SG_REL_ VCU_LE SG_ 2152464384 HndsOffStrWhlDtIO 1;
BA_REL_ "GenSigSuprvResp" BU_SG_REL_ IPC_LE SG_ 2152464384 HndsOffStrWhlDtIO 1;
BA_REL_ "GenSigSuprvResp" BU_SG_REL_ VCU_LE SG_ 2152464384 LnKpAstDisbldIO 1;
BA_REL_ "GenSigSuprvResp" BU_SG_REL_ IPC_LE SG_ 2152464384 LnKpAstDisbldIO 1;
BA_REL_ "GenSigSuprvResp" BU_SG_REL_ VCU_LE SG_ 2152464384 LKAIC_AdbWngLn 1;
BA_REL_ "GenSigSuprvResp" BU_SG_REL_ IPC_LE SG_ 2152464384 LKAIC_AdbWngLn 1;
BA_REL_ "GenSigSuprvResp" BU_SG_REL_ VCU_LE SG_ 2152464384 LKAIC_Ind2 1;
BA_REL_ "GenSigSuprvResp" BU_SG_REL_ IPC_LE SG_ 2152464384 LKAIC_Ind2 1;
BA_REL_ "GenSigSuprvResp" BU_SG_REL_ VCU_LE SG_ 2152464384 LKAIC_Ind1 1;
BA_REL_ "GenSigSuprvResp" BU_SG_REL_ IPC_LE SG_ 2152464384 LKAIC_Ind1 1;
BA_REL_ "GenSigSuprvResp" BU_SG_REL_ VCU_LE SG_ 2152464384 LKAIC_IndReq 1;
BA_REL_ "GenSigSuprvResp" BU_SG_REL_ IPC_LE SG_ 2152464384 LKAIC_IndReq 1;
BA_REL_ "GenSigSuprvResp" BU_SG_REL_ VCU_LE SG_ 2152464384 LDWIC_LnDepWAWLn 1;
BA_REL_ "GenSigSuprvResp" BU_SG_REL_ IPC_LE SG_ 2152464384 LDWIC_LnDepWAWLn 1;
BA_REL_ "GenSigSuprvResp" BU_SG_REL_ VCU_LE SG_ 2152464384 LDWIC_Ind2 1;
BA_REL_ "GenSigSuprvResp" BU_SG_REL_ IPC_LE SG_ 2152464384 LDWIC_Ind2 1;
BA_REL_ "GenSigSuprvResp" BU_SG_REL_ VCU_LE SG_ 2152464384 LDWIC_Ind1 1;
BA_REL_ "GenSigSuprvResp" BU_SG_REL_ IPC_LE SG_ 2152464384 LDWIC_Ind1 1;
BA_REL_ "GenSigSuprvResp" BU_SG_REL_ VCU_LE SG_ 2152464384 LDWIC_IndReq 1;
BA_REL_ "GenSigSuprvResp" BU_SG_REL_ IPC_LE SG_ 2152464384 LDWIC_IndReq 1;
BA_REL_ "GenSigSuprvResp" BU_SG_REL_ VCU_LE SG_ 2151342080 PrkAstRtSysStat 1;
BA_REL_ "GenSigSuprvResp" BU_SG_REL_ IPC_LE SG_ 2151342080 PrkAstRtSysStat 1;
BA_REL_ "GenSigSuprvResp" BU_SG_REL_ VCU_LE SG_ 2151342080 PARtRgn3ObjStat 1;
BA_REL_ "GenSigSuprvResp" BU_SG_REL_ IPC_LE SG_ 2151342080 PARtRgn3ObjStat 1;
BA_REL_ "GenSigSuprvResp" BU_SG_REL_ VCU_LE SG_ 2151342080 PARtRgn2ObjStat 1;
BA_REL_ "GenSigSuprvResp" BU_SG_REL_ IPC_LE SG_ 2151342080 PARtRgn2ObjStat 1;
BA_REL_ "GenSigSuprvResp" BU_SG_REL_ VCU_LE SG_ 2151342080 PARtRgn1ObjStat 1;
BA_REL_ "GenSigSuprvResp" BU_SG_REL_ IPC_LE SG_ 2151342080 PARtRgn1ObjStat 1;
BA_REL_ "GenSigSuprvResp" BU_SG_REL_ VCU_LE SG_ 2151325696 PrkAstLtSysStat 1;
BA_REL_ "GenSigSuprvResp" BU_SG_REL_ IPC_LE SG_ 2151325696 PrkAstLtSysStat 1;
BA_REL_ "GenSigSuprvResp" BU_SG_REL_ VCU_LE SG_ 2151325696 PALtRgn3ObjStat 1;
BA_REL_ "GenSigSuprvResp" BU_SG_REL_ IPC_LE SG_ 2151325696 PALtRgn3ObjStat 1;
BA_REL_ "GenSigSuprvResp" BU_SG_REL_ VCU_LE SG_ 2151325696 PALtRgn2ObjStat 1;
BA_REL_ "GenSigSuprvResp" BU_SG_REL_ IPC_LE SG_ 2151325696 PALtRgn2ObjStat 1;
BA_REL_ "GenSigSuprvResp" BU_SG_REL_ VCU_LE SG_ 2151325696 PALtRgn1ObjStat 1;
BA_REL_ "GenSigSuprvResp" BU_SG_REL_ IPC_LE SG_ 2151325696 PALtRgn1ObjStat 1;
BA_REL_ "GenSigSuprvResp" BU_SG_REL_ V2V_LE SG_ 2150367232 ImoId 1;
BA_REL_ "GenSigSuprvResp" BU_SG_REL_ VCU_LE SG_ 2150449152 ESPDrvrExtIO 1;
BA_REL_ "GenSigSuprvResp" BU_SG_REL_ IPC_LE SG_ 2150449152 ESPDrvrExtIO 1;
BA_REL_ "GenSigSuprvResp" BU_SG_REL_ VCU_LE SG_ 2150449152 ESPDrvrDrStIndtrmntIO 1;
BA_REL_ "GenSigSuprvResp" BU_SG_REL_ IPC_LE SG_ 2150449152 ESPDrvrDrStIndtrmntIO 1;
BA_REL_ "GenSigSuprvResp" BU_SG_REL_ VCU_LE SG_ 2150449152 ESPAutoPrkIO 1;
BA_REL_ "GenSigSuprvResp" BU_SG_REL_ IPC_LE SG_ 2150449152 ESPAutoPrkIO 1;
BA_REL_ "GenSigSuprvResp" BU_SG_REL_ VCU_LE SG_ 2150449152 ManTransIndReq 1;
BA_REL_ "GenSigSuprvResp" BU_SG_REL_ IPC_LE SG_ 2150449152 ManTransIndReq 1;
BA_REL_ "GenSigSuprvResp" BU_SG_REL_ VCU_LE SG_ 2150449152 SrvcFlSysPrkInOpnArIO 1;
BA_REL_ "GenSigSuprvResp" BU_SG_REL_ IPC_LE SG_ 2150449152 SrvcFlSysPrkInOpnArIO 1;
BA_REL_ "GenSigSuprvResp" BU_SG_REL_ VCU_LE SG_ 2150449152 TnDrvStblCtrlOffUnbIO 1;
BA_REL_ "GenSigSuprvResp" BU_SG_REL_ IPC_LE SG_ 2150449152 TnDrvStblCtrlOffUnbIO 1;
BA_REL_ "GenSigSuprvResp" BU_SG_REL_ VCU_LE SG_ 2150449152 TnDrvTrCtrlOffUnbIO 1;
BA_REL_ "GenSigSuprvResp" BU_SG_REL_ IPC_LE SG_ 2150449152 TnDrvTrCtrlOffUnbIO 1;
BA_REL_ "GenSigSuprvResp" BU_SG_REL_ VCU_LE SG_ 2150449152 ASIRI_Indication08 1;
BA_REL_ "GenSigSuprvResp" BU_SG_REL_ IPC_LE SG_ 2150449152 ASIRI_Indication08 1;
BA_REL_ "GenSigSuprvResp" BU_SG_REL_ VCU_LE SG_ 2150449152 ASIRI_Indication07 1;
BA_REL_ "GenSigSuprvResp" BU_SG_REL_ IPC_LE SG_ 2150449152 ASIRI_Indication07 1;
BA_REL_ "GenSigSuprvResp" BU_SG_REL_ VCU_LE SG_ 2150449152 ASIRI_Indication06 1;
BA_REL_ "GenSigSuprvResp" BU_SG_REL_ IPC_LE SG_ 2150449152 ASIRI_Indication06 1;
BA_REL_ "GenSigSuprvResp" BU_SG_REL_ VCU_LE SG_ 2150449152 ASIRI_Indication05 1;
BA_REL_ "GenSigSuprvResp" BU_SG_REL_ IPC_LE SG_ 2150449152 ASIRI_Indication05 1;
BA_REL_ "GenSigSuprvResp" BU_SG_REL_ VCU_LE SG_ 2150449152 ASIRI_Indication04 1;
BA_REL_ "GenSigSuprvResp" BU_SG_REL_ IPC_LE SG_ 2150449152 ASIRI_Indication04 1;
BA_REL_ "GenSigSuprvResp" BU_SG_REL_ VCU_LE SG_ 2150449152 ASIRI_Indication03 1;
BA_REL_ "GenSigSuprvResp" BU_SG_REL_ IPC_LE SG_ 2150449152 ASIRI_Indication03 1;
BA_REL_ "GenSigSuprvResp" BU_SG_REL_ VCU_LE SG_ 2150449152 ASIRI_Indication02 1;
BA_REL_ "GenSigSuprvResp" BU_SG_REL_ IPC_LE SG_ 2150449152 ASIRI_Indication02 1;
BA_REL_ "GenSigSuprvResp" BU_SG_REL_ VCU_LE SG_ 2150449152 ASIRI_Indication01 1;
BA_REL_ "GenSigSuprvResp" BU_SG_REL_ IPC_LE SG_ 2150449152 ASIRI_Indication01 1;
BA_REL_ "GenSigSuprvResp" BU_SG_REL_ VCU_LE SG_ 2150449152 SpdLmtrSttngTypAct 1;
BA_REL_ "GenSigSuprvResp" BU_SG_REL_ IPC_LE SG_ 2150449152 SpdLmtrSttngTypAct 1;
BA_REL_ "GenSigSuprvResp" BU_SG_REL_ VCU_LE SG_ 2150449152 FuelSysNEmsRltMalfAct 1;
BA_REL_ "GenSigSuprvResp" BU_SG_REL_ IPC_LE SG_ 2150449152 FuelSysNEmsRltMalfAct 1;
BA_REL_ "GenSigSuprvResp" BU_SG_REL_ VCU_LE SG_ 2150449152 InActFuelMdFuelLvlIO 1;
BA_REL_ "GenSigSuprvResp" BU_SG_REL_ IPC_LE SG_ 2150449152 InActFuelMdFuelLvlIO 1;
BA_REL_ "GenSigSuprvResp" BU_SG_REL_ VCU_LE SG_ 2150580224 CstNonUsbSOCDspLvl 1;
BA_REL_ "GenSigSuprvResp" BU_SG_REL_ IPC_LE SG_ 2150580224 CstNonUsbSOCDspLvl 1;
BA_REL_ "GenSigSuprvResp" BU_SG_REL_ VCU_LE SG_ 2150580224 CstmrNonUsblSOC 1;
BA_REL_ "GenSigSuprvResp" BU_SG_REL_ IPC_LE SG_ 2150580224 CstmrNonUsblSOC 1;
BA_REL_ "GenSigSuprvResp" BU_SG_REL_ VCU_LE SG_ 2150580224 PrpDspTtlPwrLvlPct 1;
BA_REL_ "GenSigSuprvResp" BU_SG_REL_ IPC_LE SG_ 2150580224 PrpDspTtlPwrLvlPct 1;
BA_REL_ "GenSigSuprvResp" BU_SG_REL_ VCU_LE SG_ 2151735296 LnChgAlrtOffIndOn 1;
BA_REL_ "GenSigSuprvResp" BU_SG_REL_ IPC_LE SG_ 2151735296 LnChgAlrtOffIndOn 1;
VAL_ 2154807296 TnDrvStBltShftIntrlkCsStAvl 1 "true" 0 "false" ;
VAL_ 2154807296 TnDrvStBltShftIntrlkCrStVal 2 "On" 1 "Off" 0 "No Action" ;
VAL_ 2154807296 StBltShftIntrlkCsStAvl 1 "true" 0 "false" ;
VAL_ 2154807296 StBltShftIntrlkCsCrStVal 2 "On" 1 "Off" 0 "No Action" ;
VAL_ 2154807296 EASSI_UnsdRsrvd2 1 "true" 0 "false" ;
VAL_ 2154807296 EASSI_StlDetd 1 "true" 0 "false" ;
VAL_ 2154807296 EASSI_TrqDetd 1 "true" 0 "false" ;
VAL_ 2154807296 EASSI_FuelReqOn 1 "true" 0 "false" ;
VAL_ 2154807296 EASSI_StrtTyp 7 "Type G" 6 "Type F" 5 "Type E" 4 "Type D" 3 "Type C" 2 "Type B" 1 "Type A" 0 "No Start" ;
VAL_ 2154807296 EASSI_StrtStpSt 3 "Engine Stopping" 2 "Engine Starting" 1 "Engine Running" 0 "Engine Off" ;
VAL_ 2154807296 EASSI_TorqDetdIndet 1 "true" 0 "false" ;
VAL_ 2154807296 EngAutoStpNotProb 1 "true" 0 "false" ;
VAL_ 2154807296 AFLMnu3CstStAvl 1 "true" 0 "false" ;
VAL_ 2154807296 AFLMnu2CstStAvl 1 "true" 0 "false" ;
VAL_ 2154807296 AFLGPSMnu2CstStAvl 1 "true" 0 "false" ;
VAL_ 2154807296 AFLGPSCstStAvl 1 "true" 0 "false" ;
VAL_ 2154807296 AFLGPSCstCrStVal 0 "No Value" 1 "Corner And Curve Lighting Only" 2 "Intelligent Light Distribution" 3 "GPS Assistance" 4 "Reserved1" 5 "Reserved2" 6 "Reserved3" 7 "Off" ;
VAL_ 2154807296 AFLCstStAvl 1 "true" 0 "false" ;
VAL_ 2154807296 AFLCstCrStVal 0 "No Value" 1 "Corner And Curve Lighting Only" 2 "Intelligent Light Distribution" 3 "Reserved1" 4 "Reserved2" 5 "Reserved3" 6 "Reserved4" 7 "Off" ;
VAL_ 2155970560 ClmCntLdShdLvlRq 0 "No Load Shedding" 1 "Load Shed Level 1" 2 "Load Shed Level 2" 3 "Load Shed Level 3" 4 "Load Shed Level 4" ;
VAL_ 2155970560 ClmCntBatSaverIO 1 "true" 0 "false" ;
VAL_ 2151686144 RrCmrDeplmntReqtsd 1 "true" 0 "false" ;
VAL_ 2151686144 NoSDCrdPrIO 1 "true" 0 "false" ;
VAL_ 2151686144 SDCrdFullIO 1 "true" 0 "false" ;
VAL_ 2151686144 SDCrdErrIO 1 "true" 0 "false" ;
VAL_ 2150629376 CVSysFlrIO 1 "true" 0 "false" ;
VAL_ 2153390080 RrClosOpenSwAct_2D1V 1 "Invalid" 0 "Valid" ;
VAL_ 2153390080 RrClosOpenSwAct_2D1 1 "true" 0 "false" ;
VAL_ 2151415808 FrPedDetCsStAvl 1 "true" 0 "false" ;
VAL_ 2151415808 FrPedDetCsCrStVal 3 "Alert and Brake" 2 "Alert" 1 "Off" 0 "No Action" ;
VAL_ 2150080512 LBCVLS_VehGPSLctV 1 "Invalid" 0 "Valid" ;
VAL_ 2150080512 LBCVLS_VehGPSLct 4 "Vehicle Within Stored GPS Region 4" 3 "Vehicle Within Stored GPS Region 3" 2 "Vehicle Within Stored GPS Region 2" 1 "Vehicle Within Stored GPS Region 1" 0 "Vehicle Not Within Stored GPS Region" ;
VAL_ 2150080512 EngAstHtDfrdHtMdAct 1 "true" 0 "false" ;
VAL_ 2150080512 LBCPSS_PosUpdtStat 2 "Position Modification Failed " 1 "Position  Updated  " 0 "No Action" ;
VAL_ 2150080512 LBCPSS_PosUpdtLct 4 "Position 4" 3 "Position 3" 2 "Position 2" 1 "Position 1" 0 "No Action" ;
VAL_ 2150080512 LBCCsStAvl 1 "true" 0 "false" ;
VAL_ 2150080512 LBCCsCrStVal 2 "On" 1 "Off" 0 "No Action" ;
VAL_ 2150080512 LBCCF_Lct4PosStrdIO 1 "true" 0 "false" ;
VAL_ 2150080512 LBCCF_Lct3PosStrdIO 1 "true" 0 "false" ;
VAL_ 2150080512 LBCCF_Lct2PosStrdIO 1 "true" 0 "false" ;
VAL_ 2150080512 LBCCF_Lct1PosStrdIO 1 "true" 0 "false" ;
VAL_ 2150080512 LBCCDRR_PosNumbr 4 "Position Number 4 " 3 "Position Number 3" 2 "Position Number 2" 1 "Position Number 1" 0 "No Action" ;
VAL_ 2150080512 LBCCDRR_ClrStrdPosResp 2 "Clear Position Performed" 1 "Clear Position Request Acknowledged" 0 "No Action" ;
VAL_ 2150080512 LBCChrgLvlPrfExpIO 1 "true" 0 "false" ;
VAL_ 2150080512 AuxClntHtrVlvStat 7 "Unused and Reserved 2" 6 "De-Aeration Routine Active" 5 "Diagnostic Override" 4 "Re-Calibration" 3 "Fault Active" 2 "Engine Link" 1 "Transition" 0 "Engine Bypass" ;
VAL_ 2153988096 PwrElecCoolLpTempM 0 "Don't Use Data" 1 "Use Data" ;
VAL_ 2153988096 PwrElecCoolLpTempV 1 "Invalid" 0 "Valid" ;
VAL_ 2151915520 ESPTrnVehOffFrPrkIO 1 "true" 0 "false" ;
VAL_ 2151915520 ESPTrnsCtlrMalfIO 1 "true" 0 "false" ;
VAL_ 2151915520 ESPShfToDrvTryAgnIO 1 "true" 0 "false" ;
VAL_ 2151915520 ElcShfPriTwoGrsSlInRq 3 "Drive Indication" 2 "Neutral Indication" 1 "Park Indication" 0 "No Indication" ;
VAL_ 2151915520 ESPRedSpdReqShftIO 1 "true" 0 "false" ;
VAL_ 2151915520 EngIntkArBstPrExtRngV 1 "Invalid" 0 "Valid" ;
VAL_ 2151915520 ElecShfRngDisp 15 "Unused and Reserved 3" 14 "Unused and Reserved 2" 13 "Unused and Reserved 1" 12 "Park Requested And Denied" 11 "Drive Requested And In Progress" 10 "Neutral Requested And In Progress" 9 "Reverse Requested And In Progress" 8 "Park Requested And In Progress" 7 "Reserved" 6 "Manual Nominal" 5 "Low Nominal" 4 "Drive Nominal" 3 "Neutral Nominal" 2 "Reverse Nominal" 1 "Park Nominal" 0 "No Display " ;
VAL_ 2151915520 ESPTransMalfIO 1 "true" 0 "false" ;
VAL_ 2151915520 ESPRngInvldReqIO 1 "true" 0 "false" ;
VAL_ 2151915520 ESPPrkInvldReqIO 1 "true" 0 "false" ;
VAL_ 2151915520 ESPHldShfLvrToEngRgIO 1 "true" 0 "false" ;
VAL_ 2151915520 ESPDrvrPrkIlkSftAtdIO 1 "true" 0 "false" ;
VAL_ 2151915520 ESPDrvrIlkShfAtdIO 1 "true" 0 "false" ;
VAL_ 2151915520 AHAct 1 "true" 0 "false" ;
VAL_ 2151915520 AHEnbld 1 "true" 0 "false" ;
VAL_ 2151915520 ShfToPrkBfExtngIO 1 "true" 0 "false" ;
VAL_ 2151915520 AHServcIO 1 "true" 0 "false" ;
VAL_ 2151915520 AHAppBrkPedlIO 1 "true" 0 "false" ;
VAL_ 2151915520 AHDisbldStbltIO 1 "true" 0 "false" ;
VAL_ 2151915520 AHDisbldDrOpnIO 1 "true" 0 "false" ;
VAL_ 2151915520 ElcTransRngSlctVDA 1 "Virtual Device Available" 0 "Virtual Device Unavailable" ;
VAL_ 2151489536 ACCLwVisbltyIO 1 "true" 0 "false" ;
VAL_ 2151489536 NVSysStat 7 "Needs Headlights" 6 "Temporarily Unavailable" 5 "Not Dark" 4 "Needs Service" 3 "Active" 2 "Inactive" 1 "Initializing" 0 "Unknown" ;
VAL_ 2151489536 RVBShtToPrkBfExtngVehIO 1 "true" 0 "false" ;
VAL_ 2151489536 RVBAutoBrkRlsIO 1 "true" 0 "false" ;
VAL_ 2154676224 CmpsModSlfTstReq 1 "Initiate Self Test" 0 "No Action" ;
VAL_ 2154676224 CmpsModManCalReq 1 "Calibrate Sensor" 0 "No Action" ;
VAL_ 2154676224 CmpsDecZonSetReq 1 "Set New Zone" 0 "No Request" ;
VAL_ 2154676224 CmpsDecZonCmndVal 15 "Zone 15" 14 "Zone 14" 13 "Zone 13" 12 "Zone 12" 11 "Zone 11" 10 "Zone 10" 9 "Zone 9" 8 "Zone 8" 7 "Zone 7" 6 "Zone 6" 5 "Zone 5" 4 "Zone 4" 3 "Zone 3" 2 "Zone 2" 1 "Zone 1" 0 "Unknown" ;
VAL_ 2152857600 ACCGrnMdStat 0 "Not Active" 1 "Ready to Assist" 2 "(Curve / Urban / Slope) Active" 3 "Temporarily not Available" ;
VAL_ 2152857600 ACCRteSpdAdaptStat 0 "Not Active" 1 "Ready to Assist" 2 "Active" 3 "Temporarily not Available" ;
VAL_ 2152857600 ACCRteSpdDrvIntvReq 0 "No Indication" 1 "Indication Level 1" 2 "Indication Level 2" 3 "Indication Level 3" ;
VAL_ 2152857600 ACCTrfcJamAstActStat 0 "Not Active" 1 "Timer Elapsed" 2 "Timer Active" 3 "Timer Retriggered" 4 "Timer Canceled" 5 "Temporarily Not Available" 6 "Traffic Jam Assist Failed" 7 "Vehicle Auto Go Notification" ;
VAL_ 2154995712 HVHtrFldIO 1 "true" 0 "false" ;
VAL_ 2154995712 HVHtrOvrTmpIndOn 1 "true" 0 "false" ;
VAL_ 2150825984 PdstIntdProtSysDplyd 1 "true" 0 "false" ;
VAL_ 2150825984 PdstIntdProtSysDsbld 1 "true" 0 "false" ;
VAL_ 2150825984 SrvIntdPdstProtSysIO 1 "true" 0 "false" ;
VAL_ 2150825984 FstnThrdRwRtPsStbtInR 3 "Unbuckled information indication" 2 "Buckled Indication" 1 "Unbuckled Indication" 0 "No Indication" ;
VAL_ 2150825984 FstnThrdRwLtPsStbtInR 3 "Unbuckled information indication" 2 "Buckled Indication" 1 "Unbuckled Indication" 0 "No Indication" ;
VAL_ 2150825984 FstnThrdRwCtPsStbtInR 3 "Unbuckled information indication" 2 "Buckled Indication" 1 "Unbuckled Indication" 0 "No Indication" ;
VAL_ 2150825984 FPSIC_IndPer 15 "8.0 s" 14 "7.0 s" 13 "6.0 s" 12 "5.0 s" 11 "4.0 s" 10 "3.5 s" 9 "3.0 s" 8 "2.5 s" 7 "2.0 s" 6 "1.75 s" 5 "1.50 s" 4 "1.25 s" 3 "1.0 s" 2 "0.75 s" 1 "0.5 s" 0 "0.25 s" ;
VAL_ 2150825984 FPSIC_IO 1 "true" 0 "false" ;
VAL_ 2150825984 FDSIC_IndPer 15 "8.0 s" 14 "7.0 s" 13 "6.0 s" 12 "5.0 s" 11 "4.0 s" 10 "3.5 s" 9 "3.0 s" 8 "2.5 s" 7 "2.0 s" 6 "1.75 s" 5 "1.50 s" 4 "1.25 s" 3 "1.0 s" 2 "0.75 s" 1 "0.5 s" 0 "0.25 s" ;
VAL_ 2150825984 FDSIC_IO 1 "true" 0 "false" ;
VAL_ 2150825984 AirbgFldIO 1 "true" 0 "false" ;
VAL_ 2150825984 SndRwStbltRdIndMd 0 "No Indication" 1 "Information Indication" 2 "Warning Indication" ;
VAL_ 2150825984 AirbgICIndPer 15 "8.0 s" 14 "7.0 s" 13 "6.0 s" 12 "5.0 s" 11 "4.0 s" 10 "3.5 s" 9 "3.0 s" 8 "2.5 s" 7 "2.0 s" 6 "1.75" 5 "1.5 s" 4 "1.25 s" 3 "1.0 s" 2 ".75 s" 1 ".5 s" 0 "0.25 s" ;
VAL_ 2150825984 AirbgICIO 1 "true" 0 "false" ;
VAL_ 2150825984 FstnSndRwRtPsStbtInR 3 "Unbuckled information indication" 2 "Buckled Indication" 1 "Unbuckled Indication" 0 "No Indication" ;
VAL_ 2150825984 FstnSndRwLtPsStbtInR 3 "Unbuckled information indication" 2 "Buckled Indication" 1 "Unbuckled Indication" 0 "No Indication" ;
VAL_ 2150825984 FstnSndRwCtPsStbtInR 3 "Unbuckled information indication" 2 "Buckled Indication" 1 "Unbuckled Indication" 0 "No Indication" ;
VAL_ 2150825984 FsnDrStbAuxIR 2 "Warning Level 2" 1 "Warning Level 1" 0 "No Indication" ;
VAL_ 2150825984 FsnPsStbAuxIR 4 "Child Warning Level 2" 3 "Child Warning Level 1" 2 "Adult Warning Level 2" 1 "Adult Warning Level 1" 0 "No Indication" ;
VAL_ 2151268352 ClmnLckTT 2 "Flashing Indication" 1 "Continuous Indication" 0 "No Indication" ;
VAL_ 2154659840 StrgClmnLckVisNot 1 "true" 0 "false" ;
VAL_ 2154659840 UnlockRtryPshIndOn 1 "true" 0 "false" ;
VAL_ 2154659840 UnlckRtryRotIndOn 1 "true" 0 "false" ;
VAL_ 2154659840 ClmSysFlrIndOn 1 "true" 0 "false" ;
VAL_ 2154659840 StrngClmnLckTT 2 "Flashing Indication" 1 "Continous Indication" 0 "No indication" ;
VAL_ 2154659840 ClmnLckStatV 1 "Invalid" 0 "Valid" ;
VAL_ 2154659840 ClmnLckStat 2 "Locked unsuccessful" 1 "Unlocked" 0 "Locked" 3 "Unlocked unsuccessful" ;
VAL_ 2149974016 IntrSnsDisbld 1 "true" 0 "false" ;
VAL_ 2149974016 AlrmStat 4 "Arming Delay" 3 "Alarm Active" 2 "Disarmed" 1 "Armed" 0 "Off" ;
VAL_ 2149974016 AlrmTrggrdBattRcnctd 1 "true" 0 "false" ;
VAL_ 2149974016 AlrmTrgDrvDr 1 "true" 0 "false" ;
VAL_ 2149974016 AlrmTrgGlsBrkSns 1 "true" 0 "false" ;
VAL_ 2149974016 AlrmTrgHd 1 "true" 0 "false" ;
VAL_ 2149974016 AlrmTrgdIO 1 "true" 0 "false" ;
VAL_ 2149974016 AlrmTrgIntMvmntSns 1 "true" 0 "false" ;
VAL_ 2149974016 AlrmTrgNonOffPM 1 "true" 0 "false" ;
VAL_ 2149974016 AlrmTrgPsngDr 1 "true" 0 "false" ;
VAL_ 2149974016 AlrmTrgRrLftDr 1 "true" 0 "false" ;
VAL_ 2149974016 AlrmTrgRrRtDr 1 "true" 0 "false" ;
VAL_ 2149974016 AlrmTrgTltSns 1 "true" 0 "false" ;
VAL_ 2149974016 AlrmTrgTrnk 1 "true" 0 "false" ;
VAL_ 2149974016 SrvAlrmSysIO 1 "true" 0 "false" ;
VAL_ 2149974016 AlrmTrigMidClsr 1 "true" 0 "false" ;
VAL_ 2149974016 AlrmTrigTonn 1 "true" 0 "false" ;
VAL_ 2155929600 DslExhFldDiagWrnIdRq 0 "No Indication" 1 "Warning Level 1" 2 "Warning Level 2" 3 "Warning Level 3" 4 "Warning Level 4" 5 "Warning Level 5" 6 "Warning Level 6" 7 "Warning Level 7" ;
VAL_ 2155929600 DslExFldTpWrngIndRq 15 "Warning Level 15" 14 "Warning Level 14" 13 "Warning Level 13" 12 "Warning Level 12" 11 "Warning Level 11" 10 "Warning Level 10" 9 "Warning Level 9" 8 "Warning Level 8" 7 "Warning Level 7" 6 "Warning Level 6" 5 "Warning Level 5" 4 "Warning Level 4" 3 "Warning Level 3" 2 "Warning Level 2" 1 "Warning Level 1" 0 "No Indication" ;
VAL_ 2155929600 DslExhFldQlyWrngIReq 15 "Warning Level 15" 14 "Warning Level 14" 13 "Warning Level 13" 12 "Warning Level 12" 11 "Warning Level 11" 10 "Warning Level 10" 9 "Warning Level 9" 8 "Warning Level 8" 7 "Warning Level 7" 6 "Warning Level 6" 5 "Warning Level 5" 4 "Warning Level 4" 3 "Warning Level 3" 2 "Warning Level 2" 1 "Warning Level 1" 0 "No Indication" ;
VAL_ 2155929600 DslExhFldWrngIdRqER 15 "Warning Level 15" 14 "Warning Level 14" 13 "Warning Level 13" 12 "Warning Level 12" 11 "Warning Level 11" 10 "Warning Level 10" 9 "Warning Level 9" 8 "Warning Level 8" 7 "Warning Level 7" 6 "Warning Level 6" 5 "Warning Level 5" 4 "Warning Level 4" 3 "Warning Level 3" 2 "Warning Level 2" 1 "Warning Level 1" 0 "No Indication" ;
VAL_ 2155929600 DslExFldCnWrngIndRq 15 "Warning Level 15" 14 "Warning Level 14" 13 "Warning Level 13" 12 "Warning Level 12" 11 "Warning Level 11" 10 "Warning Level 10" 9 "Warning Level 9" 8 "Warning Level 8" 7 "Warning Level 7" 6 "Warning Level 6" 5 "Warning Level 5" 4 "Warning Level 4" 3 "Warning Level 3" 2 "Warning Level 2" 1 "Warning Level 1" 0 "No Indication" ;
VAL_ 2155929600 DslExNxEmWrngIndRq 15 "Warning Level 15" 14 "Warning Level 14" 13 "Warning Level 13" 12 "Warning Level 12" 11 "Warning Level 11" 10 "Warning Level 10" 9 "Warning Level 9" 8 "Warning Level 8" 7 "Warning Level 7" 6 "Warning Level 6" 5 "Warning Level 5" 4 "Warning Level 4" 3 "Warning Level 3" 2 "Warning Level 2" 1 "Warning Level 1" 0 "No Indication" ;
VAL_ 2153807872 PsvStrtStrngClmnLckTT 2 "Flashing Indication" 1 "Continous Indication" 0 "No indication" ;
VAL_ 2153807872 ClmSysAuxFlrIndOn 1 "true" 0 "false" ;
VAL_ 2153807872 PsDoorOpenSwActV 1 "Invalid" 0 "Valid" ;
VAL_ 2153807872 PsDoorOpenSwAct 1 "true" 0 "false" ;
VAL_ 2153807872 DrDoorOpenSwActV 1 "Invalid" 0 "Valid" ;
VAL_ 2153807872 DrDoorOpenSwAct 1 "true" 0 "false" ;
VAL_ 2154938368 FobProgMdStat 2 "Complete" 1 "Active" 0 "Inactive" ;
VAL_ 2151751680 HptcStVbnStat 0 "Normal Operation" 1 "Unknown" 2 "Failed" ;
VAL_ 2151751680 HptcStFldIO 1 "true" 0 "false" ;
VAL_ 2151751680 CrshAlrtDrvrSlctdType 0 "Chime" 1 "Seat" ;
VAL_ 2151751680 CrshAlrtStPrsnt 1 "true" 0 "false" ;
VAL_ 2152464384 RtLnDepWrnSt 3 "Service Alignment" 2 "Right Lane Alert" 1 "Right Lane Ready to Assist" 0 "Right Lane Not Ready to Assist" ;
VAL_ 2152464384 LftLnDepWrnSt 3 "Service Alignment" 2 "Left Lane Alert" 1 "Left Lane Ready to Assist" 0 "Left Lane Not Ready to Assist" ;
VAL_ 2152464384 TnDrvLDWOffUnbIO 1 "true" 0 "false" ;
VAL_ 2152464384 SrvcLnKpAstSysIO 1 "true" 0 "false" ;
VAL_ 2152464384 HndsOffStrWhlDtIO 1 "true" 0 "false" ;
VAL_ 2152464384 LnKpAstDisbldIO 1 "true" 0 "false" ;
VAL_ 2152464384 LKAIC_AdbWngLn 0 "Off" 1 "Left Front Speaker" 2 "Right Front Speaker" ;
VAL_ 2152464384 LKAIC_Ind2 1 "true" 0 "false" ;
VAL_ 2152464384 LKAIC_Ind1 1 "true" 0 "false" ;
VAL_ 2152464384 LKAIC_IndReq 0 "Off" 1 "Continuous Indication" 2 "Flash Rate #1 Indication" ;
VAL_ 2152464384 SrvcLaneDepWrnSysIO 1 "true" 0 "false" ;
VAL_ 2152464384 LDWIC_LnDepWAWLn 2 "Right Front Speaker" 1 "Left Front Speaker" 0 "Off" ;
VAL_ 2152464384 LDWIC_Ind2 1 "true" 0 "false" ;
VAL_ 2152464384 LDWIC_Ind1 1 "true" 0 "false" ;
VAL_ 2152464384 LDWIC_IndReq 2 "Flash Rate #1 Indication" 1 "Continuous Indication" 0 "Off" ;
VAL_ 2152464384 LaneDepWrnDisbldIO 1 "true" 0 "false" ;
VAL_ 2151342080 PrkAstRtSysStat 0 "Disabled" 1 "Enabled" 2 "Inhibited" 3 "Failed" ;
VAL_ 2151342080 PARtRgn3ObjStat 0 "No Object" 1 "Zone 1" 2 "Zone 2" 3 "Zone 3" 4 "Zone 4" 5 "Zone 5" 6 "Zone 6" 7 "Zone 7" 8 "Zone 8" 9 "Zone 9" 10 "Zone 10" 11 "Zone 11" 12 "Zone 12" 13 "Zone 13" 14 "Zone 14" 15 "Zone 15" ;
VAL_ 2151342080 PARtRgn2ObjStat 0 "No Object" 1 "Zone 1" 2 "Zone 2" 3 "Zone 3" 4 "Zone 4" 5 "Zone 5" 6 "Zone 6" 7 "Zone 7" 8 "Zone 8" 9 "Zone 9" 10 "Zone 10" 11 "Zone 11" 12 "Zone 12" 13 "Zone 13" 14 "Zone 14" 15 "Zone 15" ;
VAL_ 2151342080 PARtRgn1ObjStat 0 "No Object" 1 "Zone 1" 2 "Zone 2" 3 "Zone 3" 4 "Zone 4" 5 "Zone 5" 6 "Zone 6" 7 "Zone 7" 8 "Zone 8" 9 "Zone 9" 10 "Zone 10" 11 "Zone 11" 12 "Zone 12" 13 "Zone 13" 14 "Zone 14" 15 "Zone 15" ;
VAL_ 2151325696 PrkAstLtSysStat 0 "Disabled" 1 "Enabled" 2 "Inhibited" 3 "Failed" ;
VAL_ 2151325696 PALtRgn3ObjStat 0 "No Object" 1 "Zone 1" 2 "Zone 2" 3 "Zone 3" 4 "Zone 4" 5 "Zone 5" 6 "Zone 6" 7 "Zone 7" 8 "Zone 8" 9 "Zone 9" 10 "Zone 10" 11 "Zone 11" 12 "Zone 12" 13 "Zone 13" 14 "Zone 14" 15 "Zone 15" ;
VAL_ 2151325696 PALtRgn2ObjStat 0 "No Object" 1 "Zone 1" 2 "Zone 2" 3 "Zone 3" 4 "Zone 4" 5 "Zone 5" 6 "Zone 6" 7 "Zone 7" 8 "Zone 8" 9 "Zone 9" 10 "Zone 10" 11 "Zone 11" 12 "Zone 12" 13 "Zone 13" 14 "Zone 14" 15 "Zone 15" ;
VAL_ 2151325696 PALtRgn1ObjStat 0 "No Object" 1 "Zone 1" 2 "Zone 2" 3 "Zone 3" 4 "Zone 4" 5 "Zone 5" 6 "Zone 6" 7 "Zone 7" 8 "Zone 8" 9 "Zone 9" 10 "Zone 10" 11 "Zone 11" 12 "Zone 12" 13 "Zone 13" 14 "Zone 14" 15 "Zone 15" ;
VAL_ 2150137856 LMTTCPrsnOffStat 1 "true" 0 "false" ;
VAL_ 2150137856 FldTpMotReq 0 "No Request" 1 "Stop Motion" 2 "Start Motion" 3 "Authentication Failed" ;
VAL_ 2150137856 KeyInWrnIO 1 "true" 0 "false" ;
VAL_ 2150137856 FobPrevLrndIndOn 1 "true" 0 "false" ;
VAL_ 2150137856 RemCtrlFobNumForProgER 0 "No Fob" 1 "Remote Control Fob #1" 2 "Remote Control Fob #2" 3 "Remote Control Fob #3" 4 "Remote Control Fob #4" 5 "Remote Control Fob #5" 6 "Remote Control Fob #6" 7 "Remote Control Fob #7" 8 "Remote Control Fob #8" 9 "Unused" 10 "Unused" 11 "Unused" 12 "Unused" 13 "Unused" 14 "Unused" 15 "Unused" ;
VAL_ 2150137856 FbProgCustActRqd 1 "true" 0 "false" ;
VAL_ 2150137856 Ky_IdDevNotPrIO 1 "true" 0 "false" ;
VAL_ 2150137856 VehSecAtoLrnAtv 1 "true" 0 "false" ;
VAL_ 2150137856 Ky_IdDevPrgmAuthReq 1 "true" 0 "false" ;
VAL_ 2155003904 LftLnChgThrt 1 "true" 0 "false" ;
VAL_ 2155003904 SBZATmpUnvIndOn 1 "true" 0 "false" ;
VAL_ 2155003904 SBZASysSrvIndOn 1 "true" 0 "false" ;
VAL_ 2155003904 SBZASysOffIndOn 1 "true" 0 "false" ;
VAL_ 2155003904 SBZASysClnIndOn 1 "true" 0 "false" ;
VAL_ 2150662144 EnvIdRspSt3 3 "Environment_id_request" 2 "Incorrect_immo_id" 1 "Info_valid" 0 "No_info" ;
VAL_ 2150367232 LrnEnvIdSt 1 "Info_valid" 0 "No_info" ;
VAL_ 2150367232 ImoIdSt 1 "Info valid" 0 "No info" ;
VAL_ 2151522304 BrkPdLfSysDrvrRq 4 "Reset Rear" 3 "Reset Front" 2 "Enable" 1 "Disable" 0 "No Action" ;
VAL_ 2151522304 LnchCtrlRelLnLockReqd 1 "true" 0 "false" ;
VAL_ 2151522304 TCSTmpDsblReqConf 2 "Yes" 1 "No" 0 "No Action" ;
VAL_ 2151522304 ElEngyEconAvgRstRq 1 "true" 0 "false" ;
VAL_ 2151522304 FuelFltLfRstRqd 1 "true" 0 "false" ;
VAL_ 2153791488 ArtcldRngBrdSt 5 "Running Boards Inhibited" 4 "Running Boards Cargo Access" 0 "No Action" 1 "Resume Normal Operation" 2 "Running Boards Deployed" 3 "Running Boards Stowed" ;
VAL_ 2150449152 ESPDrvrExtIO 1 "true" 0 "false" ;
VAL_ 2150449152 ESPDrvrDrStIndtrmntIO 1 "true" 0 "false" ;
VAL_ 2150449152 ESPAutoPrkIO 1 "true" 0 "false" ;
VAL_ 2150449152 ManTransIndReq 3 "Indication 3" 2 "Indication 2" 1 "Indication 1" 0 "No Indication" ;
VAL_ 2150449152 SrvcFlSysPrkInOpnArIO 1 "true" 0 "false" ;
VAL_ 2150449152 TnDrvStblCtrlOffUnbIO 1 "true" 0 "false" ;
VAL_ 2150449152 TnDrvTrCtrlOffUnbIO 1 "true" 0 "false" ;
VAL_ 2150449152 ASIRI_Indication08 1 "true" 0 "false" ;
VAL_ 2150449152 ASIRI_Indication07 1 "true" 0 "false" ;
VAL_ 2150449152 ASIRI_Indication06 1 "true" 0 "false" ;
VAL_ 2150449152 ASIRI_Indication05 1 "true" 0 "false" ;
VAL_ 2150449152 ASIRI_Indication04 1 "true" 0 "false" ;
VAL_ 2150449152 ASIRI_Indication03 1 "true" 0 "false" ;
VAL_ 2150449152 ASIRI_Indication02 1 "true" 0 "false" ;
VAL_ 2150449152 ASIRI_Indication01 1 "true" 0 "false" ;
VAL_ 2150449152 SpdLmtrSttngTypAct 3 "Reserved" 2 "Auto" 1 "Manual" 0 "Off" ;
VAL_ 2150449152 FuelSysNEmsRltMalfAct 1 "true" 0 "false" ;
VAL_ 2150449152 InActFuelMdFuelLvlIO 1 "true" 0 "false" ;
VAL_ 2150449152 EngInltSpcfcHmdtyV 1 "Invalid" 0 "Valid" ;
VAL_ 2150449152 EngInltSpcfcHmdtyM 0 "Don't Use Data" 1 "Use Data" ;
VAL_ 2150449152 AltFuelSysOvrflDtdIO 1 "true" 0 "false" ;
VAL_ 2155945984 VehStbEnhmntCurStRq 2 "On" 1 "Off" 0 "No Action" ;
VAL_ 2155945984 VehStbCmptvMdCurStRq 2 "On" 1 "Off" 0 "No Action" ;
VAL_ 2155945984 TCSysCurStReq 2 "On" 1 "Off" 0 "No Action" ;
VAL_ 2155945984 JmpStrtReq 1 "true" 0 "false" ;
VAL_ 2150580224 CstmrNonUsblSOCV 1 "Invalid" 0 "Valid" ;
VAL_ 2151735296 RtSdDetSysServDsbld 1 "true" 0 "false" ;
VAL_ 2151735296 RtSdDetSysTmpDsbld 1 "true" 0 "false" ;
VAL_ 2151735296 RtLnChgAlrtEnbld 1 "true" 0 "false" ;
VAL_ 2151735296 RtSBZAlrtEnbld 1 "true" 0 "false" ;
VAL_ 2151735296 RtRrCrsTrfcAlrtEnbld 1 "true" 0 "false" ;
VAL_ 2151735296 LnChgAlrtOffIndOn 1 "true" 0 "false" ;
VAL_ 2151735296 RrCrsTrfcAlrtOffIO 1 "true" 0 "false" ;
VAL_ 2155298816 TrPrsMntrTrLdRstRqstd 0 "Unknown" 1 "Light Load" 2 "Best Economy Load" 3 "Max Load" ;
VAL_ 2155298816 TrPrsSnsProgEvntRqd 1 "true" 0 "false" ;
VAL_ 2155298816 EngAirFltMonDrvrReq 3 "Reset" 2 "Disable" 1 "Enable" 0 "No Action" ;
VAL_ 2157985792 FobProgEvntRqd 1 "true" 0 "false" ;
VAL_ 2153955328 EngOffTmExtRngV 1 "Invalid" 0 "Valid" ;
VAL_ 2153955328 ElpsdTimeCntRstOcc 1 "true" 0 "false" ;
SIG_GROUP_ 2154807296 EngAutoStrtStpInfo 1 : EASSI_UnsdRsrvd2 EASSI_StlDetd EASSI_TrqDetd EASSI_FuelReqOn EASSI_StrtTyp EASSI_StrtStpSt EASSI_TorqDetdIndet;
SIG_GROUP_ 2153914368 EngyUsgScrScal 1 : EUSS_TrEgUgScrMxScVal EUSS_TrEgUgScrMnScVal EUSS_TcEgUgScrMxScVal EUSS_TcEgUgScrMnScVal EUSS_ITEgUgScrMxScVal EUSS_ITEgUgScrMnScVal EUSS_OTEgUgScrMxScVal EUSS_OTEgUgScrMnScVal;
SIG_GROUP_ 2150080512 LBCVehLctStat 1 : LBCVLS_VehGPSLctV LBCVLS_VehGPSLct;
SIG_GROUP_ 2150080512 LBCPosStgStat 1 : LBCPSS_PosUpdtStat LBCPSS_PosUpdtLct;
SIG_GROUP_ 2150080512 LBCCstmrFdbk 1 : LBCCF_Lct4PosStrdIO LBCCF_Lct3PosStrdIO LBCCF_Lct2PosStrdIO LBCCF_Lct1PosStrdIO;
SIG_GROUP_ 2150080512 LBCCstmrDaRstResp 1 : LBCCDRR_PosNumbr LBCCDRR_ClrStrdPosResp;
SIG_GROUP_ 2153988096 EngyUsgScr 1 : EUS_TtEngyUsgScrAvVal EUS_ITEngyUsgScrAvVal EUS_OTEngyUsgScrAvVal EUS_TrEngyUsgScrAvVal EUS_TcEngyUsgScrAvVal;
SIG_GROUP_ 2150809600 ImpDltVlcSamp12 1 : IDVS12_Axis2 IDVS12_Axis1;
SIG_GROUP_ 2150809600 ImpDltVlcSamp13 1 : IDVS13_Axis2 IDVS13_Axis1;
SIG_GROUP_ 2150809600 ImpDltVlcSamp14 1 : IDVS14_Axis2 IDVS14_Axis1;
SIG_GROUP_ 2150809600 ImpDltVlcSamp15 1 : IDVS15_Axis2 IDVS15_Axis1;
SIG_GROUP_ 2150801408 ImpDltVlcSamp10 1 : IDVS10_Axis2 IDVS10_Axis1;
SIG_GROUP_ 2150801408 ImpDltVlcSamp11 1 : IDVS11_Axis2 IDVS11_Axis1;
SIG_GROUP_ 2150801408 ImpDltVlcSamp8 1 : IDVS8_Axis2 IDVS8_Axis1;
SIG_GROUP_ 2150801408 ImpDltVlcSamp9 1 : IDVS9_Axis2 IDVS9_Axis1;
SIG_GROUP_ 2150793216 ImpDltVlcSamp4 1 : IDVS4_Axis2 IDVS4_Axis1;
SIG_GROUP_ 2150793216 ImpDltVlcSamp5 1 : IDVS5_Axis2 IDVS5_Axis1;
SIG_GROUP_ 2150793216 ImpDltVlcSamp6 1 : IDVS6_Axis2 IDVS6_Axis1;
SIG_GROUP_ 2150793216 ImpDltVlcSamp7 1 : IDVS7_Axis2 IDVS7_Axis1;
SIG_GROUP_ 2150785024 ImpDltVlcSamp1 1 : IDVS1_Axis2 IDVS1_Axis1;
SIG_GROUP_ 2150785024 ImpDltVlcSamp2 1 : IDVS2_Axis2 IDVS2_Axis1;
SIG_GROUP_ 2150785024 ImpDltVlcSamp3 1 : IDVS3_Axis2 IDVS3_Axis1;
SIG_GROUP_ 2150825984 FsnPsngStbltIC 1 : FPSIC_IndPer FPSIC_IO FPSIC_IndDtCyc;
SIG_GROUP_ 2150825984 FsnDrvStbltIC 1 : FDSIC_IndPer FDSIC_IO FDSIC_IndDC;
SIG_GROUP_ 2150825984 AirbgIC 1 : AirbgICIndPer AirbgICDutCyc AirbgICIO;
SIG_GROUP_ 2155929600 DslExFldWrngVSpdLmt 1 : DEFWVSL_S3SpdLmt DEFWVSL_S2SpdLmt DEFWVSL_S1SpdLmt;
SIG_GROUP_ 2152464384 LnKpAstIndCntrl 1 : LKAIC_AdbWngLn LKAIC_Ind2 LKAIC_Ind1 LKAIC_IndReq;
SIG_GROUP_ 2152464384 LaneDepWrnIndCntrl 1 : LDWIC_LnDepWAWLn LDWIC_Ind2 LDWIC_Ind1 LDWIC_IndReq;
SIG_GROUP_ 2150449152 AutoStpInhbtRsnInd 1 : ASIRI_Indication08 ASIRI_Indication07 ASIRI_Indication06 ASIRI_Indication05 ASIRI_Indication04 ASIRI_Indication03 ASIRI_Indication02 ASIRI_Indication01;
